VERSION ""

NS_ :

BS_:

BU_: Turbocharger OnBoardDataLogger OffBoardDiagnosticTool2 OffBoardDiagnosticTool1 FileServer ParkingBrakeController SeatControl2 FanDriveController SteeringColumnUnit CommunicationUnitRadio CommunicationUnitSatellite CommunicationUnitCellular PropulsionBatteryCharger ChassisController2 ChassisController1 EngineValveControl AuxiliaryHeater2 AuxiliaryHeater1 ClutchUnit RampControl InformationSystem1 SuspensionSystemController2 OilSensor VehicleDynamicStability ExhaustEmissionController TransmissionDisplay2 TransmissionDisplay1 ClimateControl2 WaterPumpController RearAxleSteeringController LightingOperatorControl SeatController1 IgnitionController2 IgnitionController1 TirePressureController CabController2 CabController1 PneumaticSystemController SuspensionSystemController1 HydraulicPumpController EnduranceBrakingSystem RetarderExhaustEngine2 OnBoardDiagnosticUnit HeadwayController RetarderExhaustEngine1 CabDisplay1 ManagementComputer VirtualTerminal OffVehicleGateway PowerTakeOffFront HitchControl AuxiliaryValveControl BodyController TractorTrailerBridge1 StarterSystem ElectricalSystem VehicleSecurity VehicleNavigation AerodynamicControl ElectricalChargingSystem ClimateControl1 TripRecorder InstrumentCluster SuspensionDriveAxle2 SuspensionDriveAxle1 SuspensionSteerAxle SteeringController FuelSystem CruiseControl RetarderDriveline RetarderEngine BrakesDriveAxle2 BrakesDriveAxle1 BrakesSystemController BrakesSteerAxle AxleDrive2 AxleDrive1 AxleSteering PowerTakeOff ShiftConsoleSecondary ShiftConsolePrimary Transmission2 Transmission1 Engine2 Engine1
VAL_TABLE_ FMI 31 "Not available" 19 "Received network data in error" 18 "Below normal (moderately severe)" 17 "Below normal (least severe)" 16 "Above normal (moderately severe)" 15 "Above normal (least severe)" 14 "Special intstructions" 13 "Out of calibration" 12 "Bad intelligent device" 11 "Root cause not known" 10 "Abnormal rate of change" 9 "Abnormal update rate" 8 "Abnormal frequency" 7 "Mechanical system not responding" 6 "Current above normal" 5 "Current below normal" 4 "Voltage below normal" 3 "Voltage above normal" 2 "Data erratic" 1 "Below normal (most severe)" 0 "Above normal (most severe)" ;

BO_ 3221225472 VECTOR__INDEPENDENT_SIG_MSG: 0 Vector__XXX
 SG_ TrailerWeight : 0|16@1+ (2,0) [0|128510] "kg" Vector__XXX
 SG_ ReferenceTirePressSetting : 0|8@1+ (1,0) [0|2000] "kPa" Vector__XXX
 SG_ ReferenceTirePress : 0|8@1+ (1,0) [0|2000] "kPa" Vector__XXX
 SG_ TirePressThresholdDetection : 0|3@1+ (1,0) [0|7] "" Vector__XXX
 SG_ TireAirLeakageRate : 0|16@1+ (0.1,0) [0|6425.5] "Pa/s" Vector__XXX
 SG_ CTIWheelEndElectricalFault : 0|2@1+ (1,0) [0|3] "" Vector__XXX
 SG_ CTITireStatus : 0|2@1+ (1,0) [0|3] "" Vector__XXX
 SG_ CTIWheelSensorStatus : 0|2@1+ (1,0) [0|3] "" Vector__XXX
 SG_ TireTemp : 0|16@1+ (0.03125,-273) [-273|1734.96875] "deg C" Vector__XXX
 SG_ TirePress : 0|8@1+ (4,0) [0|1000] "kPa" Vector__XXX
 SG_ EngTurningGearEngaged : 0|2@1+ (1,0) [0|3] "" Vector__XXX

BO_ 2632975290 TEST_ABSESC_DEVICE_BA: 8 Vector__XXX
 SG_ Can1RxIntrCnt : 32|32@1+ (1,0) [0|4294967295] "" Vector__XXX
 SG_ Can0RxIntrCnt : 0|32@1+ (1,0) [0|4294967295] "" Vector__XXX

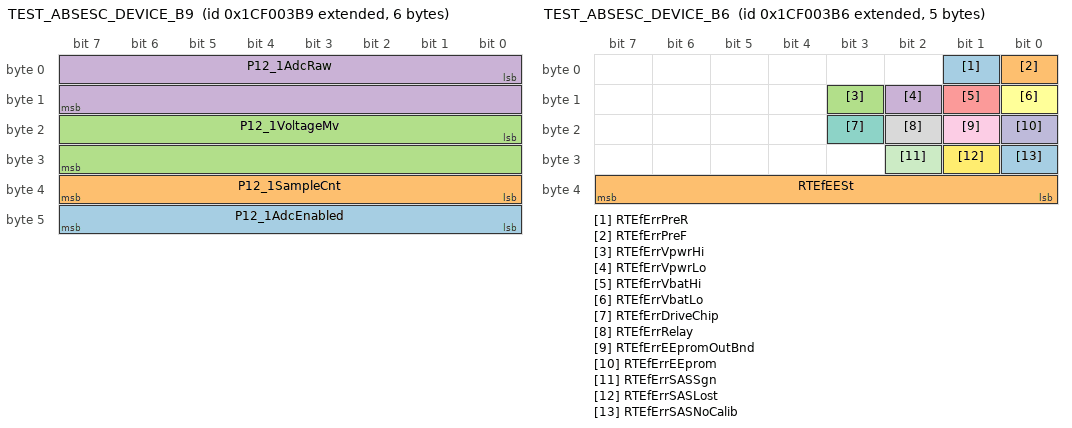
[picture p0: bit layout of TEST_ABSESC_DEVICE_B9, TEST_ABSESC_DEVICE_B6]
BO_ 2632975289 TEST_ABSESC_DEVICE_B9: 6 Vector__XXX
 SG_ P12_1AdcEnabled : 40|8@1+ (1,0) [0|1] "" Vector__XXX
 SG_ P12_1SampleCnt : 32|8@1+ (1,0) [0|255] "" Vector__XXX
 SG_ P12_1VoltageMv : 16|16@1+ (1,0) [0|5000] "mV" Vector__XXX
 SG_ P12_1AdcRaw : 0|16@1+ (1,0) [0|4095] "" Vector__XXX

BO_ 2632975286 TEST_ABSESC_DEVICE_B6: 5 Vector__XXX
 SG_ RTEfErrPreR : 1|1@1+ (1,0) [0|1] "" Vector__XXX
 SG_ RTEfErrPreF : 0|1@1+ (1,0) [0|1] "" Vector__XXX
 SG_ RTEfErrVpwrHi : 11|1@1+ (1,0) [0|1] "" Vector__XXX
 SG_ RTEfErrVpwrLo : 10|1@1+ (1,0) [0|1] "" Vector__XXX
 SG_ RTEfErrVbatHi : 9|1@1+ (1,0) [0|1] "" Vector__XXX
 SG_ RTEfErrVbatLo : 8|1@1+ (1,0) [0|1] "" Vector__XXX
 SG_ RTEfErrDriveChip : 19|1@1+ (1,0) [0|1] "" Vector__XXX
 SG_ RTEfErrRelay : 18|1@1+ (1,0) [0|1] "" Vector__XXX
 SG_ RTEfErrEEpromOutBnd : 17|1@1+ (1,0) [0|1] "" Vector__XXX
 SG_ RTEfErrEEprom : 16|1@1+ (1,0) [0|1] "" Vector__XXX
 SG_ RTEfErrSASSgn : 26|1@1+ (1,0) [0|1] "" Vector__XXX
 SG_ RTEfErrSASLost : 25|1@1+ (1,0) [0|1] "" Vector__XXX
 SG_ RTEfErrSASNoCalib : 24|1@1+ (1,0) [0|1] "" Vector__XXX
 SG_ RTEfEESt : 32|8@1+ (1,0) [0|255] "" Vector__XXX

BO_ 2632975285 TEST_ABSESC_DEVICE_B5: 8 Vector__XXX
 SG_ RTEfErrASRValveShortX : 57|1@1+ (1,0) [0|1] "" Vector__XXX
 SG_ RTEfErrASRValveOpenX : 56|1@1+ (1,0) [0|1] "" Vector__XXX
 SG_ RTEfErrASRValveShortR : 51|1@1+ (1,0) [0|1] "" Vector__XXX
 SG_ RTEfErrASRValveOpenR : 50|1@1+ (1,0) [0|1] "" Vector__XXX
 SG_ RTEfErrASRValveShortF : 49|1@1+ (1,0) [0|1] "" Vector__XXX
 SG_ RTEfErrASRValveOpenF : 48|1@1+ (1,0) [0|1] "" Vector__XXX
 SG_ RTEfErrOutValShortXR : 41|1@1+ (1,0) [0|1] "" Vector__XXX
 SG_ RTEfErrOutValOpenXR : 40|1@1+ (1,0) [0|1] "" Vector__XXX
 SG_ RTEfErrInValShortXR : 33|1@1+ (1,0) [0|1] "" Vector__XXX
 SG_ RTEfErrInValOpenXR : 32|1@1+ (1,0) [0|1] "" Vector__XXX
 SG_ RTEfErrOutValShortXL : 25|1@1+ (1,0) [0|1] "" Vector__XXX
 SG_ RTEfErrOutValOpenXL : 24|1@1+ (1,0) [0|1] "" Vector__XXX
 SG_ RTEfErrInValShortXL : 17|1@1+ (1,0) [0|1] "" Vector__XXX
 SG_ RTEfErrInValOpenXL : 16|1@1+ (1,0) [0|1] "" Vector__XXX
 SG_ RTEfErrOutValShortTr : 9|1@1+ (1,0) [0|1] "" Vector__XXX
 SG_ RTEfErrOutValOpenTr : 8|1@1+ (1,0) [0|1] "" Vector__XXX
 SG_ RTEfErrInValShortTr : 1|1@1+ (1,0) [0|1] "" Vector__XXX
 SG_ RTEfErrInValOpenTr : 0|1@1+ (1,0) [0|1] "" Vector__XXX

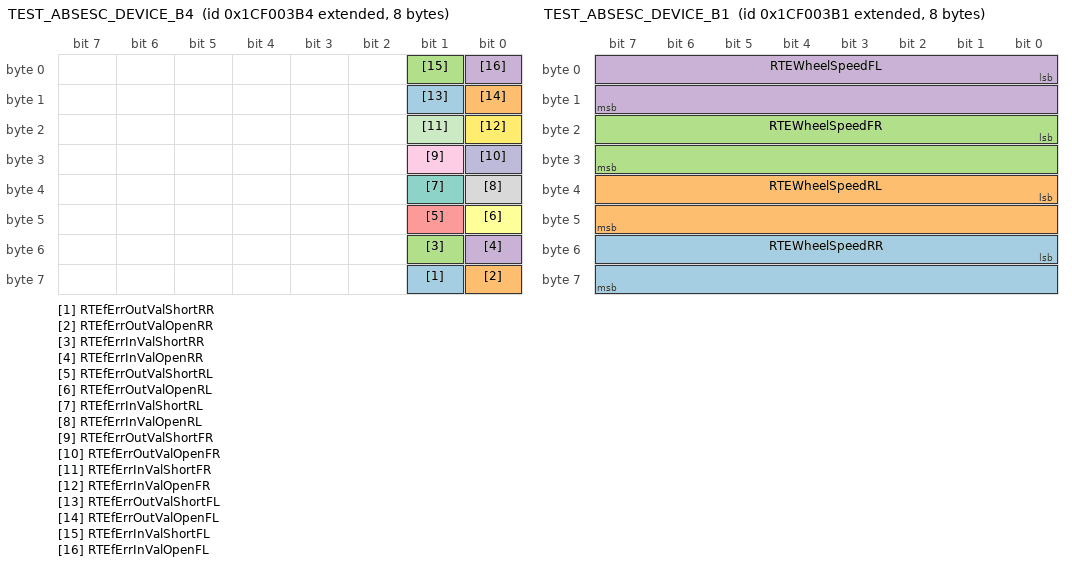
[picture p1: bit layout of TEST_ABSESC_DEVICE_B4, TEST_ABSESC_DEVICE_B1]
BO_ 2632975284 TEST_ABSESC_DEVICE_B4: 8 Vector__XXX
 SG_ RTEfErrOutValShortRR : 57|1@1+ (1,0) [0|1] "" Vector__XXX
 SG_ RTEfErrOutValOpenRR : 56|1@1+ (1,0) [0|1] "" Vector__XXX
 SG_ RTEfErrInValShortRR : 49|1@1+ (1,0) [0|1] "" Vector__XXX
 SG_ RTEfErrInValOpenRR : 48|1@1+ (1,0) [0|1] "" Vector__XXX
 SG_ RTEfErrOutValShortRL : 41|1@1+ (1,0) [0|1] "" Vector__XXX
 SG_ RTEfErrOutValOpenRL : 40|1@1+ (1,0) [0|1] "" Vector__XXX
 SG_ RTEfErrInValShortRL : 33|1@1+ (1,0) [0|1] "" Vector__XXX
 SG_ RTEfErrInValOpenRL : 32|1@1+ (1,0) [0|1] "" Vector__XXX
 SG_ RTEfErrOutValShortFR : 25|1@1+ (1,0) [0|1] "" Vector__XXX
 SG_ RTEfErrOutValOpenFR : 24|1@1+ (1,0) [0|1] "" Vector__XXX
 SG_ RTEfErrInValShortFR : 17|1@1+ (1,0) [0|1] "" Vector__XXX
 SG_ RTEfErrInValOpenFR : 16|1@1+ (1,0) [0|1] "" Vector__XXX
 SG_ RTEfErrOutValShortFL : 9|1@1+ (1,0) [0|1] "" Vector__XXX
 SG_ RTEfErrOutValOpenFL : 8|1@1+ (1,0) [0|1] "" Vector__XXX
 SG_ RTEfErrInValShortFL : 1|1@1+ (1,0) [0|1] "" Vector__XXX
 SG_ RTEfErrInValOpenFL : 0|1@1+ (1,0) [0|1] "" Vector__XXX

BO_ 2632975283 TEST_ABSESC_DEVICE_B3: 6 Vector__XXX
 SG_ RTEfErrWssGapXR : 42|1@1+ (1,0) [0|1] "" Vector__XXX
 SG_ RTEfErrWssShortXR : 41|1@1+ (1,0) [0|1] "" Vector__XXX
 SG_ RTEfErrWssOpenXR : 40|1@1+ (1,0) [0|1] "" Vector__XXX
 SG_ RTEfErrWssGapXL : 34|1@1+ (1,0) [0|1] "" Vector__XXX
 SG_ RTEfErrWssShortXL : 33|1@1+ (1,0) [0|1] "" Vector__XXX
 SG_ RTEfErrWssOpenXL : 32|1@1+ (1,0) [0|1] "" Vector__XXX
 SG_ RTEfErrWssGapRR : 26|1@1+ (1,0) [0|1] "" Vector__XXX
 SG_ RTEfErrWssShortRR : 25|1@1+ (1,0) [0|1] "" Vector__XXX
 SG_ RTEfErrWssOpenRR : 24|1@1+ (1,0) [0|1] "" Vector__XXX
 SG_ RTEfErrWssGapRL : 18|1@1+ (1,0) [0|1] "" Vector__XXX
 SG_ RTEfErrWssShortRL : 17|1@1+ (1,0) [0|1] "" Vector__XXX
 SG_ RTEfErrWssOpenRL : 16|1@1+ (1,0) [0|1] "" Vector__XXX
 SG_ RTEfErrWssGapFR : 10|1@1+ (1,0) [0|1] "" Vector__XXX
 SG_ RTEfErrWssShortFR : 9|1@1+ (1,0) [0|1] "" Vector__XXX
 SG_ RTEfErrWssOpenFR : 8|1@1+ (1,0) [0|1] "" Vector__XXX
 SG_ RTEfErrWssGapFL : 2|1@1+ (1,0) [0|1] "" Vector__XXX
 SG_ RTEfErrWssShortFL : 1|1@1+ (1,0) [0|1] "" Vector__XXX
 SG_ RTEfErrWssOpenFL : 0|1@1+ (1,0) [0|1] "" Vector__XXX

BO_ 2632975282 TEST_ABSESC_DEVICE_B2: 4 Vector__XXX
 SG_ RTEWheelSpeedXR : 16|16@1+ (1,0) [0|65535] "mm/s" Vector__XXX
 SG_ RTEWheelSpeedXL : 0|16@1+ (1,0) [0|65535] "mm/s" Vector__XXX

BO_ 2632975281 TEST_ABSESC_DEVICE_B1: 8 Vector__XXX
 SG_ RTEWheelSpeedRR : 48|16@1+ (1,0) [0|65535] "mm/s" Vector__XXX
 SG_ RTEWheelSpeedRL : 32|16@1+ (1,0) [0|65535] "mm/s" Vector__XXX
 SG_ RTEWheelSpeedFR : 16|16@1+ (1,0) [0|65535] "mm/s" Vector__XXX
 SG_ RTEWheelSpeedFL : 0|16@1+ (1,0) [0|65535] "mm/s" Vector__XXX

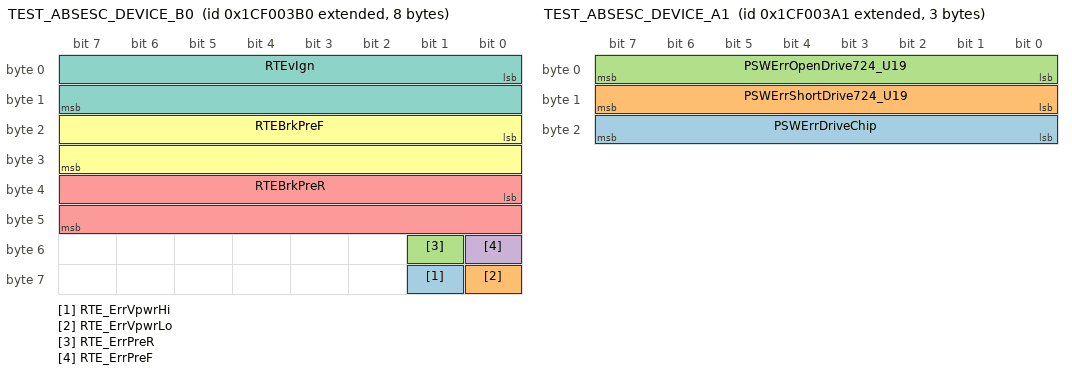
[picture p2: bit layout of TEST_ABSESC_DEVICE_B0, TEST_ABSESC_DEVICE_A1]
BO_ 2632975280 TEST_ABSESC_DEVICE_B0: 8 Vector__XXX
 SG_ RTE_ErrVpwrHi : 57|1@1+ (1,0) [0|1] "" Vector__XXX
 SG_ RTE_ErrVpwrLo : 56|1@1+ (1,0) [0|1] "" Vector__XXX
 SG_ RTE_ErrPreR : 49|1@1+ (1,0) [0|1] "" Vector__XXX
 SG_ RTE_ErrPreF : 48|1@1+ (1,0) [0|1] "" Vector__XXX
 SG_ RTEBrkPreR : 32|16@1+ (1,0) [0|65535] "kPa" Vector__XXX
 SG_ RTEBrkPreF : 16|16@1+ (1,0) [0|65535] "kPa" Vector__XXX
 SG_ RTEvIgn : 0|16@1+ (1,0) [0|65535] "0.1V" Vector__XXX

BO_ 2632975265 TEST_ABSESC_DEVICE_A1: 3 Vector__XXX
 SG_ PSWErrDriveChip : 16|8@1+ (1,0) [0|10] "" Vector__XXX
 SG_ PSWErrShortDrive724_U19 : 8|8@1+ (1,0) [0|3] "" Vector__XXX
 SG_ PSWErrOpenDrive724_U19 : 0|8@1+ (1,0) [0|3] "" Vector__XXX

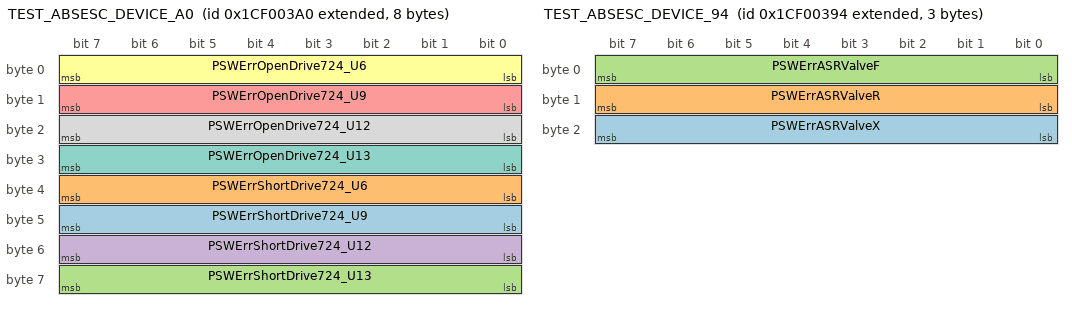
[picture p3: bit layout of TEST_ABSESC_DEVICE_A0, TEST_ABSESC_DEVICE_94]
BO_ 2632975264 TEST_ABSESC_DEVICE_A0: 8 Vector__XXX
 SG_ PSWErrShortDrive724_U9 : 40|8@1+ (1,0) [0|3] "" Vector__XXX
 SG_ PSWErrShortDrive724_U6 : 32|8@1+ (1,0) [0|3] "" Vector__XXX
 SG_ PSWErrShortDrive724_U13 : 56|8@1+ (1,0) [0|3] "" Vector__XXX
 SG_ PSWErrShortDrive724_U12 : 48|8@1+ (1,0) [0|3] "" Vector__XXX
 SG_ PSWErrOpenDrive724_U9 : 8|8@1+ (1,0) [0|3] "" Vector__XXX
 SG_ PSWErrOpenDrive724_U6 : 0|8@1+ (1,0) [0|3] "" Vector__XXX
 SG_ PSWErrOpenDrive724_U13 : 24|8@1+ (1,0) [0|3] "" Vector__XXX
 SG_ PSWErrOpenDrive724_U12 : 16|8@1+ (1,0) [0|3] "" Vector__XXX

BO_ 2632975252 TEST_ABSESC_DEVICE_94: 3 Vector__XXX
 SG_ PSWErrASRValveX : 16|8@1+ (1,0) [0|3] "" Vector__XXX
 SG_ PSWErrASRValveR : 8|8@1+ (1,0) [0|3] "" Vector__XXX
 SG_ PSWErrASRValveF : 0|8@1+ (1,0) [0|0] "" Vector__XXX

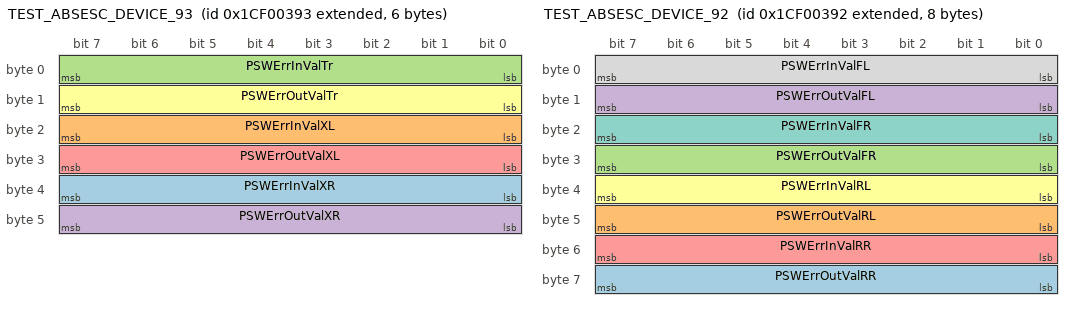
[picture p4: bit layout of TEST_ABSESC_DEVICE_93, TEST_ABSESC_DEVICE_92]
BO_ 2632975251 TEST_ABSESC_DEVICE_93: 6 Vector__XXX
 SG_ PSWErrInValXR : 32|8@1+ (1,0) [0|3] "" Vector__XXX
 SG_ PSWErrInValXL : 16|8@1+ (1,0) [0|3] "" Vector__XXX
 SG_ PSWErrInValTr : 0|8@1+ (1,0) [0|3] "" Vector__XXX
 SG_ PSWErrOutValXR : 40|8@1+ (1,0) [0|3] "" Vector__XXX
 SG_ PSWErrOutValXL : 24|8@1+ (1,0) [0|3] "" Vector__XXX
 SG_ PSWErrOutValTr : 8|8@1+ (1,0) [0|3] "" Vector__XXX

BO_ 2632975250 TEST_ABSESC_DEVICE_92: 8 Vector__XXX
 SG_ PSWErrOutValRR : 56|8@1+ (1,0) [0|3] "" Vector__XXX
 SG_ PSWErrOutValRL : 40|8@1+ (1,0) [0|3] "" Vector__XXX
 SG_ PSWErrOutValFR : 24|8@1+ (1,0) [0|3] "" Vector__XXX
 SG_ PSWErrOutValFL : 8|8@1+ (1,0) [0|3] "" Vector__XXX
 SG_ PSWErrInValRR : 48|8@1+ (1,0) [0|3] "" Vector__XXX
 SG_ PSWErrInValRL : 32|8@1+ (1,0) [0|3] "" Vector__XXX
 SG_ PSWErrInValFR : 16|8@1+ (1,0) [0|3] "" Vector__XXX
 SG_ PSWErrInValFL : 0|8@1+ (1,0) [0|3] "" Vector__XXX

BO_ 2632975249 TEST_ABSESC_DEVICE_91: 0 Vector__XXX

BO_ 2632975248 TEST_ABSESC_DEVICE_90: 2 Vector__XXX
 SG_ ASRRLowSideSt : 8|8@1+ (1,0) [0|1] "" Vector__XXX
 SG_ ASRFLowSideSt : 0|8@1+ (1,0) [0|1] "" Vector__XXX

BO_ 2632975233 TEST_ABSESC_DEVICE_81: 4 Vector__XXX
 SG_ PSWWheelSpeedXR : 16|16@1+ (1,0) [0|65535] "mm/s" Vector__XXX
 SG_ PSWWheelSpeedXL : 0|16@1+ (1,0) [0|65535] "mm/s" Vector__XXX

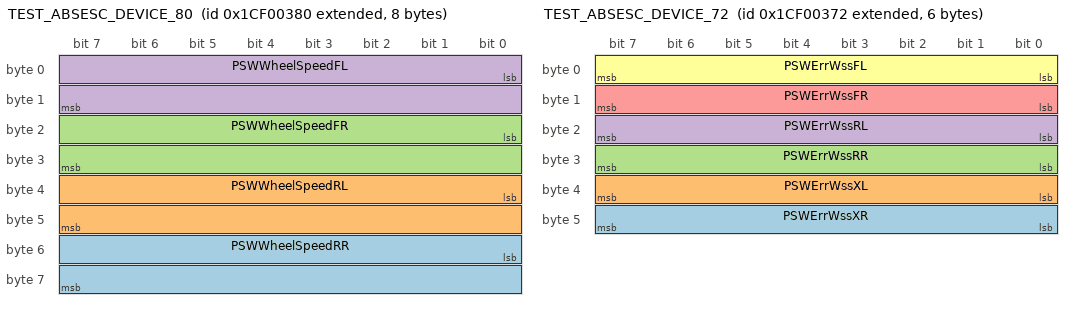
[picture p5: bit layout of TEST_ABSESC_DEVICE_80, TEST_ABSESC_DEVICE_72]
BO_ 2632975232 TEST_ABSESC_DEVICE_80: 8 Vector__XXX
 SG_ PSWWheelSpeedRR : 48|16@1+ (1,0) [0|65535] "mm/s" Vector__XXX
 SG_ PSWWheelSpeedRL : 32|16@1+ (1,0) [0|65535] "mm/s" Vector__XXX
 SG_ PSWWheelSpeedFR : 16|16@1+ (1,0) [0|65535] "mm/s" Vector__XXX
 SG_ PSWWheelSpeedFL : 0|16@1+ (1,0) [0|65535] "mm/s" Vector__XXX

BO_ 2632975218 TEST_ABSESC_DEVICE_72: 6 Vector__XXX
 SG_ PSWErrWssXR : 40|8@1+ (1,0) [0|3] "" Vector__XXX
 SG_ PSWErrWssXL : 32|8@1+ (1,0) [0|3] "" Vector__XXX
 SG_ PSWErrWssRR : 24|8@1+ (1,0) [0|3] "" Vector__XXX
 SG_ PSWErrWssRL : 16|8@1+ (1,0) [0|3] "" Vector__XXX
 SG_ PSWErrWssFR : 8|8@1+ (1,0) [0|3] "" Vector__XXX
 SG_ PSWErrWssFL : 0|8@1+ (1,0) [0|3] "" Vector__XXX

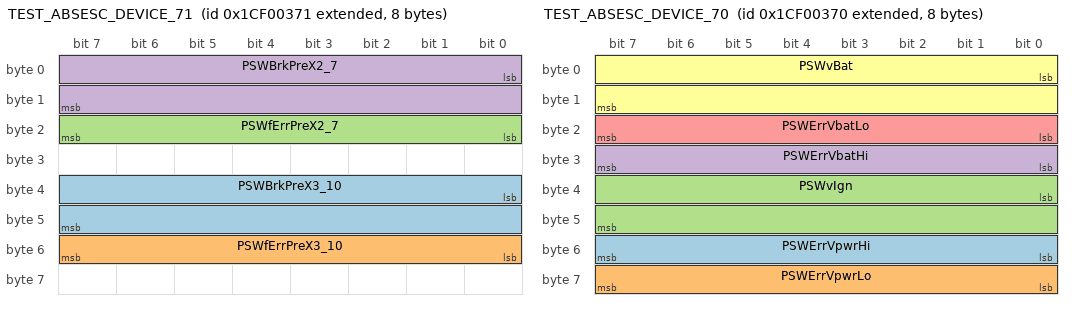
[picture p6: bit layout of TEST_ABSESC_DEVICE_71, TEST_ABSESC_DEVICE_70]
BO_ 2632975217 TEST_ABSESC_DEVICE_71: 8 Vector__XXX
 SG_ PSWBrkPreX3_10 : 32|16@1+ (1,0) [0|0] "" Vector__XXX
 SG_ PSWfErrPreX3_10 : 48|8@1+ (1,0) [0|0] "" Vector__XXX
 SG_ PSWfErrPreX2_7 : 16|8@1+ (1,0) [0|0] "" Vector__XXX
 SG_ PSWBrkPreX2_7 : 0|16@1+ (1,0) [0|0] "" Vector__XXX

BO_ 2632975216 TEST_ABSESC_DEVICE_70: 8 Vector__XXX
 SG_ PSWErrVpwrHi : 48|8@1+ (1,0) [0|0] "" Vector__XXX
 SG_ PSWErrVpwrLo : 56|8@1+ (1,0) [0|0] "" Vector__XXX
 SG_ PSWvIgn : 32|16@1+ (1,0) [0|0] "" Vector__XXX
 SG_ PSWErrVbatHi : 24|8@1+ (1,0) [0|0] "" Vector__XXX
 SG_ PSWErrVbatLo : 16|8@1+ (1,0) [0|0] "" Vector__XXX
 SG_ PSWvBat : 0|16@1+ (1,0) [0|0] "" Vector__XXX

BO_ 2632975205 TEST_ABSESC_DEVICE_65: 2 Vector__XXX
 SG_ PSWfErrEEpromOutBnd : 8|8@1+ (1,0) [0|0] "" Vector__XXX
 SG_ PSWfErrEEprom : 0|8@1+ (1,0) [0|0] "" Vector__XXX

BO_ 2632975204 TEST_ABSESC_DEVICE_64: 2 Vector__XXX
 SG_ flFlag : 0|16@1+ (1,0) [0|0] "" Vector__XXX

BO_ 2632975203 TEST_ABSESC_DEVICE_63: 2 Vector__XXX
 SG_ flFlag : 0|16@1+ (1,0) [0|0] "" Vector__XXX

BO_ 2632975202 TEST_ABSESC_DEVICE_62: 1 Vector__XXX
 SG_ PSWfErrEEprom : 0|8@1+ (1,0) [0|0] "" Vector__XXX

BO_ 2632975201 TEST_ABSESC_DEVICE_61: 1 Vector__XXX
 SG_ eeFlag : 0|8@1+ (1,0) [0|0] "" Vector__XXX

BO_ 2632975200 TEST_ABSESC_DEVICE_60: 2 Vector__XXX
 SG_ phase : 0|8@1+ (1,0) [0|4] "" Vector__XXX
 SG_ PSWfErrEEprom : 8|8@1+ (1,0) [0|1] "" Vector__XXX

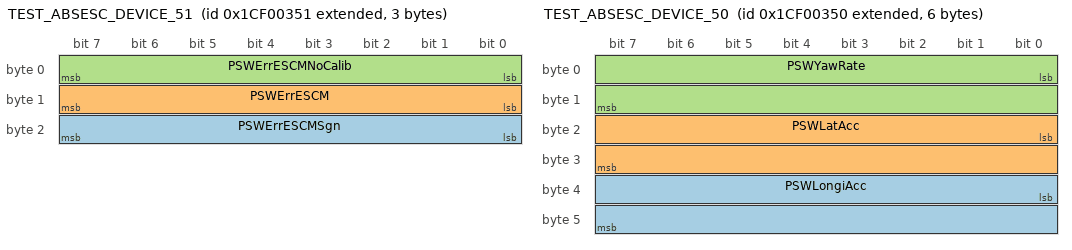
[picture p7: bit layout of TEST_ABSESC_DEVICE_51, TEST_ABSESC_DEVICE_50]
BO_ 2632975185 TEST_ABSESC_DEVICE_51: 3 Vector__XXX
 SG_ PSWErrESCMSgn : 16|8@1+ (1,0) [0|0] "" Vector__XXX
 SG_ PSWErrESCM : 8|8@1+ (1,0) [0|0] "" Vector__XXX
 SG_ PSWErrESCMNoCalib : 0|8@1+ (1,0) [0|0] "" Vector__XXX

BO_ 2632975184 TEST_ABSESC_DEVICE_50: 6 Vector__XXX
 SG_ PSWLongiAcc : 32|16@1+ (0.01,-21) [0|0] "m/s2" Vector__XXX
 SG_ PSWLatAcc : 16|16@1+ (0.01,-21) [0|0] "m/s2" Vector__XXX
 SG_ PSWYawRate : 0|16@1+ (0.01,-300) [0|0] "rad/s" Vector__XXX

BO_ 2632975170 TEST_ABSESC_DEVICE_42: 1 Vector__XXX
 SG_ PSWErrRelay : 0|8@1+ (1,0) [0|1] "" Vector__XXX

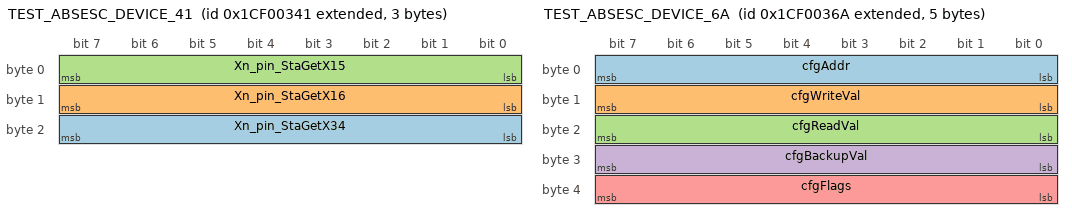
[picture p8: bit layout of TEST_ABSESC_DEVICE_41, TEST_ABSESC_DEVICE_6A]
BO_ 2632975169 TEST_ABSESC_DEVICE_41: 3 Vector__XXX
 SG_ Xn_pin_StaGetX34 : 16|8@1+ (1,0) [0|0] "" Vector__XXX
 SG_ Xn_pin_StaGetX16 : 8|8@1+ (1,0) [0|0] "" Vector__XXX
 SG_ Xn_pin_StaGetX15 : 0|8@1+ (1,0) [0|0] "" Vector__XXX

BO_ 2632975168 TEST_ABSESC_DEVICE_40: 3 Vector__XXX
 SG_ gpoFlag_phase : 0|8@1+ (1,0) [0|0] "0" Vector__XXX
 SG_ gpoFlag : 8|16@1+ (1,0) [0|0] "0" Vector__XXX

BO_ 2632975152 TEST_ABSESC_DEVICE_30: 4 Vector__XXX
 SG_ timercnt10ms : 0|32@1+ (1,0) [0|0] "" Vector__XXX

BO_ 2632975137 TEST_ABSESC_DEVICE_21: 2 Vector__XXX
 SG_ WD_cnt : 0|16@1+ (1,0) [0|65535] "" Vector__XXX

BO_ 2632975136 TEST_ABSESC_DEVICE_20: 2 Vector__XXX
 SG_ WD_cnt : 0|16@1+ (1,0) [0|65535] "" Vector__XXX

BO_ 2632975121 TEST_ABSESC_DEVICE_11: 4 Vector__XXX
 SG_ resetReason : 0|32@1+ (1,0) [0|0] "" Vector__XXX

BO_ 2632975120 TEST_ABSESC_DEVICE_10: 1 Vector__XXX
 SG_ rstFlag : 0|8@1+ (1,0) [0|0] "8" Vector__XXX

BO_ 2632975106 TEST_ABSESC_DEVICE_02: 4 Vector__XXX
 SG_ extCnt : 0|16@1+ (1,0) [0|65535] "" Vector__XXX
 SG_ stdCnt : 16|16@1+ (1,0) [0|65535] "" Vector__XXX

BO_ 2632975107 TEST_ABSESC_DEVICE_03: 2 Vector__XXX
 SG_ busoffState0 : 0|8@1+ (1,0) [0|1] "" Vector__XXX
 SG_ busoffState1 : 8|8@1+ (1,0) [0|1] "" Vector__XXX

BO_ 2632975210 TEST_ABSESC_DEVICE_6A: 5 Vector__XXX
 SG_ cfgAddr : 0|8@1+ (1,0) [0|31] "" Vector__XXX
 SG_ cfgWriteVal : 8|8@1+ (1,0) [0|255] "" Vector__XXX
 SG_ cfgReadVal : 16|8@1+ (1,0) [0|255] "" Vector__XXX
 SG_ cfgBackupVal : 24|8@1+ (1,0) [0|255] "" Vector__XXX
 SG_ cfgFlags : 32|8@1+ (1,0) [0|7] "" Vector__XXX

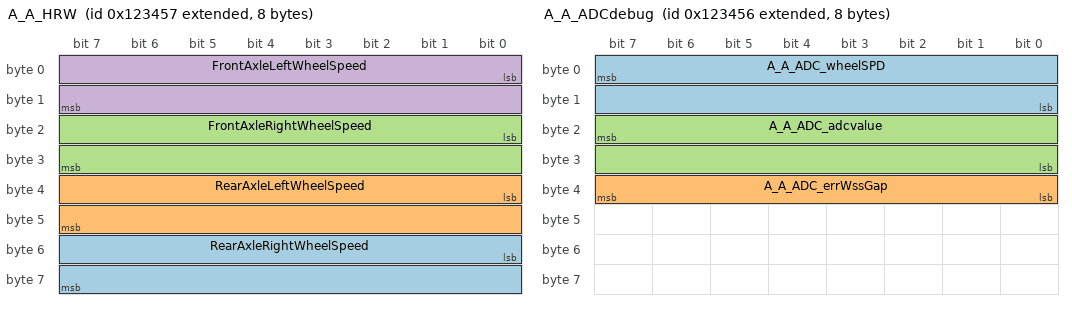
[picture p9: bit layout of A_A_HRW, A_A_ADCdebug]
BO_ 2148676695 A_A_HRW: 8 Vector__XXX
 SG_ RearAxleRightWheelSpeed : 48|16@1+ (0.0036,0) [0|200] "km/h" Vector__XXX
 SG_ RearAxleLeftWheelSpeed : 32|16@1+ (0.0036,0) [0|200] "km/h" Vector__XXX
 SG_ FrontAxleRightWheelSpeed : 16|16@1+ (0.0036,0) [0|200] "km/h" Vector__XXX
 SG_ FrontAxleLeftWheelSpeed : 0|16@1+ (0.0036,0) [0|200] "km/h" Vector__XXX

BO_ 2148676694 A_A_ADCdebug: 8 Vector__XXX
 SG_ A_A_ADC_wheelSPD : 7|16@0+ (0.0036,0) [0|150] "km/h" Vector__XXX
 SG_ A_A_ADC_errWssGap : 32|8@1+ (1,0) [0|5] "" Vector__XXX
 SG_ A_A_ADC_adcvalue : 23|16@0+ (1,0) [0|5000] "" Vector__XXX

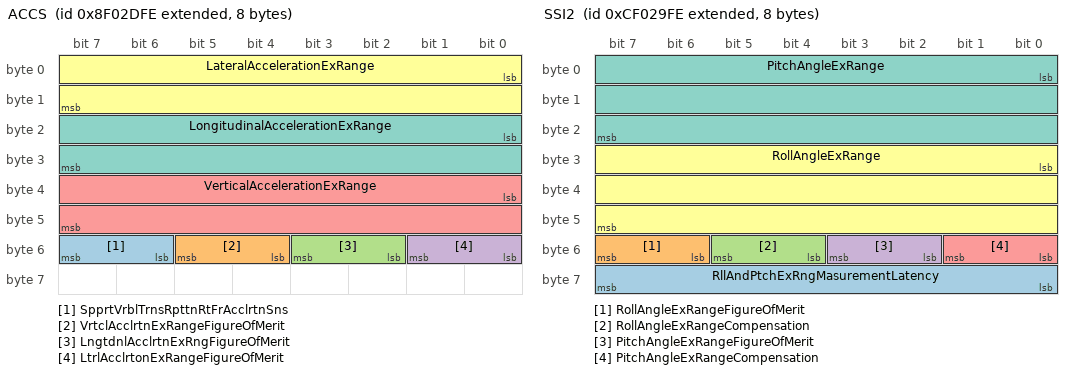
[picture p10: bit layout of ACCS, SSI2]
BO_ 2297441790 ACCS: 8 Vector__XXX
 SG_ SpprtVrblTrnsRpttnRtFrAcclrtnSns : 54|2@1+ (1,0) [0|3] "" Vector__XXX
 SG_ VrtclAcclrtnExRangeFigureOfMerit : 52|2@1+ (1,0) [0|3] "" Vector__XXX
 SG_ LngtdnlAcclrtnExRngFigureOfMerit : 50|2@1+ (1,0) [0|3] "" Vector__XXX
 SG_ LtrlAcclrtonExRangeFigureOfMerit : 48|2@1+ (1,0) [0|3] "" Vector__XXX
 SG_ VerticalAccelerationExRange : 32|16@1+ (0.01,-320) [-320|322.55] "m/s�" Vector__XXX
 SG_ LateralAccelerationExRange : 0|16@1+ (0.01,-320) [-320|322.55] "m/s�" Vector__XXX
 SG_ LongitudinalAccelerationExRange : 16|16@1+ (0.01,-320) [-320|322.55] "m/s�" Vector__XXX

BO_ 2566712062 VEP4: 8 Vector__XXX
 SG_ HybridBatteryPackRemainingCharge : 0|16@1+ (0.0025,0) [0|160.6375] "%" Vector__XXX

BO_ 2364549630 SSI2: 8 Vector__XXX
 SG_ RllAndPtchExRngMasurementLatency : 56|8@1+ (0.5,0) [0|125] "ms" Vector__XXX
 SG_ RollAngleExRangeFigureOfMerit : 54|2@1+ (1,0) [0|3] "" Vector__XXX
 SG_ RollAngleExRangeCompensation : 52|2@1+ (1,0) [0|3] "" Vector__XXX
 SG_ PitchAngleExRangeFigureOfMerit : 50|2@1+ (1,0) [0|3] "" Vector__XXX
 SG_ PitchAngleExRangeCompensation : 48|2@1+ (1,0) [0|3] "" Vector__XXX
 SG_ RollAngleExRange : 24|24@1+ (1,-250) [-250|250.9999] "deg" Vector__XXX
 SG_ PitchAngleExRange : 0|24@1+ (1,-250) [-250|250.9999] "deg" Vector__XXX

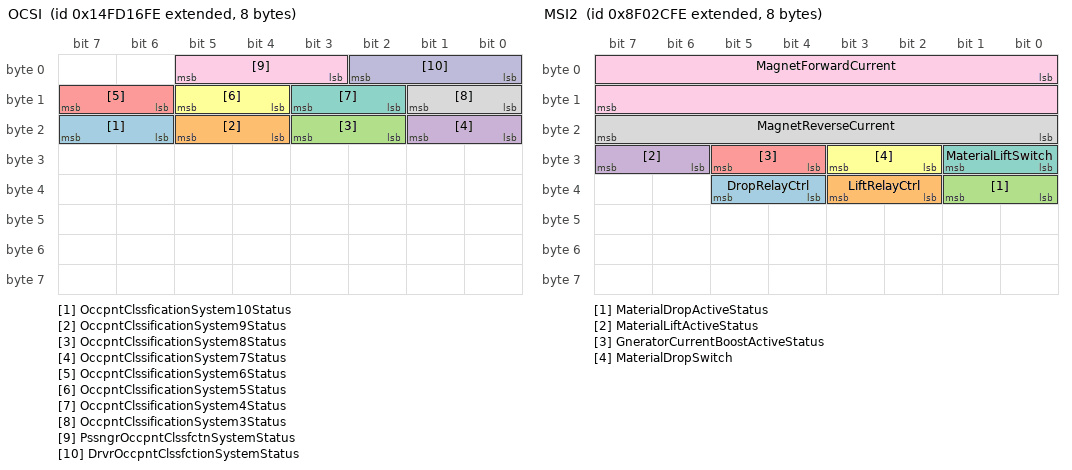
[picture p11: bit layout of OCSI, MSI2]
BO_ 2499614462 OCSI: 8 Vector__XXX
 SG_ OccpntClssficationSystem10Status : 22|2@1+ (1,0) [0|3] "" Vector__XXX
 SG_ OccpntClssificationSystem9Status : 20|2@1+ (1,0) [0|3] "" Vector__XXX
 SG_ OccpntClssificationSystem8Status : 18|2@1+ (1,0) [0|3] "" Vector__XXX
 SG_ OccpntClssificationSystem7Status : 16|2@1+ (1,0) [0|3] "" Vector__XXX
 SG_ OccpntClssificationSystem6Status : 14|2@1+ (1,0) [0|3] "" Vector__XXX
 SG_ OccpntClssificationSystem5Status : 12|2@1+ (1,0) [0|3] "" Vector__XXX
 SG_ OccpntClssificationSystem4Status : 10|2@1+ (1,0) [0|3] "" Vector__XXX
 SG_ OccpntClssificationSystem3Status : 8|2@1+ (1,0) [0|3] "" Vector__XXX
 SG_ PssngrOccpntClssfctnSystemStatus : 3|3@1+ (1,0) [0|7] "" Vector__XXX
 SG_ DrvrOccpntClssfctionSystemStatus : 0|3@1+ (1,0) [0|7] "" Vector__XXX

BO_ 2560098046 NCS: 8 Vector__XXX
 SG_ CabNoiseCtrlTuningStatus : 2|4@1+ (1,0) [0|15] "" Vector__XXX
 SG_ CabNoiseCtrlStatus : 0|2@1+ (1,0) [0|3] "" Vector__XXX

BO_ 2560163582 NC1: 8 Vector__XXX
 SG_ CabNoiseCtrlTuningState : 2|3@1+ (1,0) [0|7] "" Vector__XXX
 SG_ CabNoiseCtrlState : 0|2@1+ (1,0) [0|3] "" Vector__XXX

BO_ 2297441534 MSI2: 8 Vector__XXX
 SG_ DropRelayCtrl : 36|2@1+ (1,0) [0|3] "" Vector__XXX
 SG_ LiftRelayCtrl : 34|2@1+ (1,0) [0|3] "" Vector__XXX
 SG_ MaterialDropActiveStatus : 32|2@1+ (1,0) [0|3] "" Vector__XXX
 SG_ MaterialLiftActiveStatus : 30|2@1+ (1,0) [0|3] "" Vector__XXX
 SG_ GneratorCurrentBoostActiveStatus : 28|2@1+ (1,0) [0|3] "" Vector__XXX
 SG_ MaterialDropSwitch : 26|2@1+ (1,0) [0|3] "" Vector__XXX
 SG_ MaterialLiftSwitch : 24|2@1+ (1,0) [0|3] "" Vector__XXX
 SG_ MagnetReverseCurrent : 16|8@1+ (1,0) [0|250] "A" Vector__XXX
 SG_ MagnetForwardCurrent : 0|16@1+ (1,0) [0|64255] "Amps" Vector__XXX

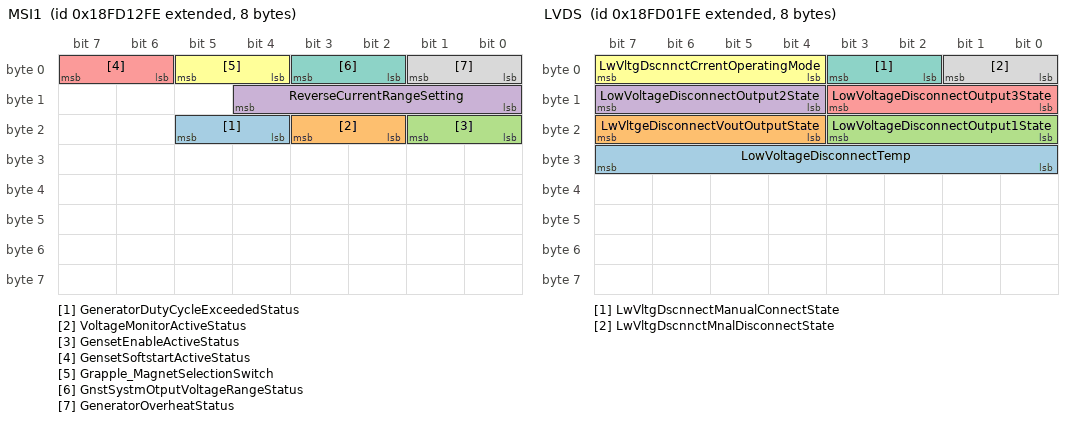
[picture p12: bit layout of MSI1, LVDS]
BO_ 2566722302 MSI1: 8 Vector__XXX
 SG_ GeneratorDutyCycleExceededStatus : 20|2@1+ (1,0) [0|3] "" Vector__XXX
 SG_ VoltageMonitorActiveStatus : 18|2@1+ (1,0) [0|3] "" Vector__XXX
 SG_ GensetEnableActiveStatus : 16|2@1+ (1,0) [0|3] "" Vector__XXX
 SG_ ReverseCurrentRangeSetting : 8|5@1+ (1,0) [0|31] "" Vector__XXX
 SG_ GensetSoftstartActiveStatus : 6|2@1+ (1,0) [0|3] "" Vector__XXX
 SG_ Grapple_MagnetSelectionSwitch : 4|2@1+ (1,0) [0|3] "" Vector__XXX
 SG_ GnstSystmOtputVoltageRangeStatus : 2|2@1+ (1,0) [0|3] "" Vector__XXX
 SG_ GeneratorOverheatStatus : 0|2@1+ (1,0) [0|3] "" Vector__XXX

BO_ 2566722558 MSCI: 8 Vector__XXX
 SG_ MagnetRatedPower : 8|16@1+ (1,0) [0|32127.5] "kW" Vector__XXX
 SG_ MagnetBoostTime : 0|8@1+ (1,0) [0|62.5] "s" Vector__XXX

BO_ 2560032510 LVDSOM: 8 Vector__XXX
 SG_ LwVltgDscnnctDsiredOperatingMode : 0|4@1+ (1,0) [0|15] "" Vector__XXX

BO_ 2566717950 LVDS: 8 Vector__XXX
 SG_ LowVoltageDisconnectTemp : 24|8@1+ (1,-40) [-40|210] "deg C" Vector__XXX
 SG_ LwVltgeDisconnectVoutOutputState : 20|4@1+ (1,0) [0|15] "" Vector__XXX
 SG_ LowVoltageDisconnectOutput1State : 16|4@1+ (1,0) [0|15] "" Vector__XXX
 SG_ LowVoltageDisconnectOutput2State : 12|4@1+ (1,0) [0|15] "" Vector__XXX
 SG_ LowVoltageDisconnectOutput3State : 8|4@1+ (1,0) [0|15] "" Vector__XXX
 SG_ LwVltgDscnnctCrrentOperatingMode : 4|4@1+ (1,0) [0|15] "" Vector__XXX
 SG_ LwVltgDscnnectManualConnectState : 2|2@1+ (1,0) [0|3] "" Vector__XXX
 SG_ LwVltgDscnnctMnalDisconnectState : 0|2@1+ (1,0) [0|3] "" Vector__XXX

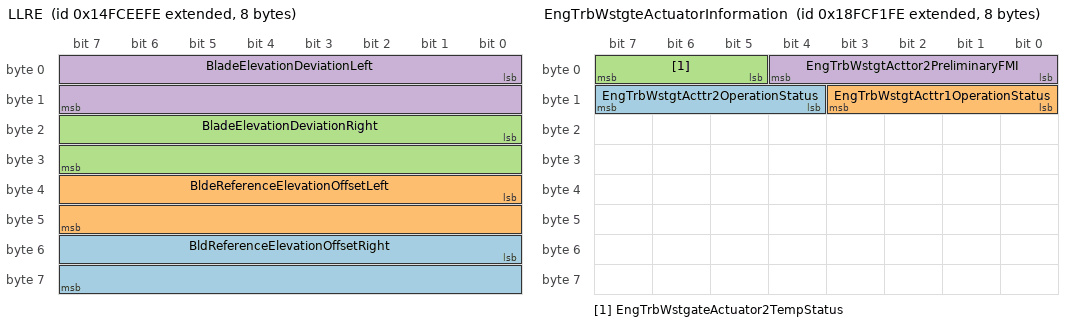
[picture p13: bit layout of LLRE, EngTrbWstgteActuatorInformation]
BO_ 2499604222 LLRE: 8 Vector__XXX
 SG_ BldReferenceElevationOffsetRight : 48|16@1+ (1,-32000) [-32000|32255] "mm" Vector__XXX
 SG_ BldeReferenceElevationOffsetLeft : 32|16@1+ (1,-32000) [-32000|32255] "mm" Vector__XXX
 SG_ BladeElevationDeviationRight : 16|16@1+ (1,-32000) [-32000|32255] "mm" Vector__XXX
 SG_ BladeElevationDeviationLeft : 0|16@1+ (1,-32000) [-32000|32255] "mm" Vector__XXX

BO_ 2358902526 JLCM: 8 Vector__XXX
 SG_ Joystick3Lamp10Cmd : 58|2@1+ (1,0) [0|3] "" Vector__XXX
 SG_ Joystick3Lamp9Cmd : 56|2@1+ (1,0) [0|3] "" Vector__XXX
 SG_ Joystick3Lamp8Cmd : 54|2@1+ (1,0) [0|3] "" Vector__XXX
 SG_ Joystick3Lamp7Cmd : 52|2@1+ (1,0) [0|3] "" Vector__XXX
 SG_ Joystick3Lamp6Cmd : 50|2@1+ (1,0) [0|3] "" Vector__XXX
 SG_ Joystick3Lamp5Cmd : 48|2@1+ (1,0) [0|3] "" Vector__XXX
 SG_ Joystick3Lamp4Cmd : 46|2@1+ (1,0) [0|3] "" Vector__XXX
 SG_ Joystick3Lamp3Cmd : 44|2@1+ (1,0) [0|3] "" Vector__XXX
 SG_ Joystick3Lamp2Cmd : 42|2@1+ (1,0) [0|3] "" Vector__XXX
 SG_ Joystick3Lamp1Cmd : 40|2@1+ (1,0) [0|3] "" Vector__XXX
 SG_ Joystick2Lamp10Cmd : 38|2@1+ (1,0) [0|3] "" Vector__XXX
 SG_ Joystick2Lamp9Cmd : 36|2@1+ (1,0) [0|3] "" Vector__XXX
 SG_ Joystick2Lamp8Cmd : 34|2@1+ (1,0) [0|3] "" Vector__XXX
 SG_ Joystick2Lamp7Cmd : 32|2@1+ (1,0) [0|3] "" Vector__XXX
 SG_ Joystick2Lamp6Cmd : 30|2@1+ (1,0) [0|3] "" Vector__XXX
 SG_ Joystick2Lamp5Cmd : 28|2@1+ (1,0) [0|3] "" Vector__XXX
 SG_ Joystick2Lamp4Cmd : 26|2@1+ (1,0) [0|3] "" Vector__XXX
 SG_ Joystick2Lamp3Cmd : 24|2@1+ (1,0) [0|3] "" Vector__XXX
 SG_ Joystick2Lamp2Cmd : 22|2@1+ (1,0) [0|3] "" Vector__XXX
 SG_ Joystick2Lamp1Cmd : 20|2@1+ (1,0) [0|3] "" Vector__XXX
 SG_ Joystick1Lamp10Cmd : 18|2@1+ (1,0) [0|3] "" Vector__XXX
 SG_ Joystick1Lamp9Cmd : 16|2@1+ (1,0) [0|3] "" Vector__XXX
 SG_ Joystick1Lamp8Cmd : 14|2@1+ (1,0) [0|3] "" Vector__XXX
 SG_ Joystick1Lamp7Cmd : 12|2@1+ (1,0) [0|3] "" Vector__XXX
 SG_ Joystick1Lamp6Cmd : 10|2@1+ (1,0) [0|3] "" Vector__XXX
 SG_ Joystick1Lamp5Cmd : 8|2@1+ (1,0) [0|3] "" Vector__XXX
 SG_ Joystick1Lamp4Cmd : 6|2@1+ (1,0) [0|3] "" Vector__XXX
 SG_ Joystick1Lamp3Cmd : 4|2@1+ (1,0) [0|3] "" Vector__XXX
 SG_ Joystick1Lamp2Cmd : 2|2@1+ (1,0) [0|3] "" Vector__XXX
 SG_ Joystick1Lamp1Cmd : 0|2@1+ (1,0) [0|3] "" Vector__XXX

BO_ 2566711550 IVAC: 8 Vector__XXX
 SG_ IntkVlvActtnSystmOlPrss2SlndCtrl : 2|2@1+ (1,0) [0|3] "" Vector__XXX
 SG_ IntkVlvActtnSystmOlPrss1SlndCtrl : 0|2@1+ (1,0) [0|3] "" Vector__XXX

BO_ 2633832958 ILI: 8 Vector__XXX
 SG_ SpecialIgnitorLoop90Resistance : 1584|16@1+ (0.1,0) [0|6425.5] "ohm" Vector__XXX
 SG_ SpecialIgnitorLoop89Resistance : 1568|16@1+ (0.1,0) [0|6425.5] "ohm" Vector__XXX
 SG_ SpecialIgnitorLoop88Resistance : 1552|16@1+ (0.1,0) [0|6425.5] "ohm" Vector__XXX
 SG_ SpecialIgnitorLoop87Resistance : 1536|16@1+ (0.1,0) [0|6425.5] "ohm" Vector__XXX
 SG_ SpecialIgnitorLoop86Resistance : 1520|16@1+ (0.1,0) [0|6425.5] "ohm" Vector__XXX
 SG_ SpecialIgnitorLoop85Resistance : 1504|16@1+ (0.1,0) [0|6425.5] "ohm" Vector__XXX
 SG_ SpecialIgnitorLoop84Resistance : 1488|16@1+ (0.1,0) [0|6425.5] "ohm" Vector__XXX
 SG_ SpecialIgnitorLoop83Resistance : 1472|16@1+ (0.1,0) [0|6425.5] "ohm" Vector__XXX
 SG_ SpecialIgnitorLoop82Resistance : 1456|16@1+ (0.1,0) [0|6425.5] "ohm" Vector__XXX
 SG_ SpecialIgnitorLoop81Resistance : 1440|16@1+ (0.1,0) [0|6425.5] "ohm" Vector__XXX
 SG_ SpecialIgnitorLoop80Resistance : 1424|16@1+ (0.1,0) [0|6425.5] "ohm" Vector__XXX
 SG_ SpecialIgnitorLoop79Resistance : 1408|16@1+ (0.1,0) [0|6425.5] "ohm" Vector__XXX
 SG_ SpecialIgnitorLoop78Resistance : 1392|16@1+ (0.1,0) [0|6425.5] "ohm" Vector__XXX
 SG_ SpecialIgnitorLoop77Resistance : 1376|16@1+ (0.1,0) [0|6425.5] "ohm" Vector__XXX
 SG_ SpecialIgnitorLoop76Resistance : 1360|16@1+ (0.1,0) [0|6425.5] "ohm" Vector__XXX
 SG_ SpecialIgnitorLoop75Resistance : 1344|16@1+ (0.1,0) [0|6425.5] "ohm" Vector__XXX
 SG_ SpecialIgnitorLoop74Resistance : 1328|16@1+ (0.1,0) [0|6425.5] "ohm" Vector__XXX
 SG_ SpecialIgnitorLoop73Resistance : 1312|16@1+ (0.1,0) [0|6425.5] "ohm" Vector__XXX
 SG_ SpecialIgnitorLoop72Resistance : 1296|16@1+ (0.1,0) [0|6425.5] "ohm" Vector__XXX
 SG_ SpecialIgnitorLoop71Resistance : 1280|16@1+ (0.1,0) [0|6425.5] "ohm" Vector__XXX
 SG_ SpecialIgnitorLoop70Resistance : 1264|16@1+ (0.1,0) [0|6425.5] "ohm" Vector__XXX
 SG_ SpecialIgnitorLoop69Resistance : 1248|16@1+ (0.1,0) [0|6425.5] "ohm" Vector__XXX
 SG_ SpecialIgnitorLoop68Resistance : 1232|16@1+ (0.1,0) [0|6425.5] "ohm" Vector__XXX
 SG_ SpecialIgnitorLoop67Resistance : 1216|16@1+ (0.1,0) [0|6425.5] "ohm" Vector__XXX
 SG_ SpecialIgnitorLoop66Resistance : 1200|16@1+ (0.1,0) [0|6425.5] "ohm" Vector__XXX
 SG_ SpecialIgnitorLoop65Resistance : 1184|16@1+ (0.1,0) [0|6425.5] "ohm" Vector__XXX
 SG_ SpecialIgnitorLoop64Resistance : 1168|16@1+ (0.1,0) [0|6425.5] "ohm" Vector__XXX
 SG_ SpecialIgnitorLoop63Resistance : 1152|16@1+ (0.1,0) [0|6425.5] "ohm" Vector__XXX
 SG_ SpecialIgnitorLoop61Resistance : 1120|16@1+ (0.1,0) [0|6425.5] "ohm" Vector__XXX
 SG_ SpecialIgnitorLoop60Resistance : 1104|16@1+ (0.1,0) [0|6425.5] "ohm" Vector__XXX
 SG_ SpecialIgnitorLoop59Resistance : 1088|16@1+ (0.1,0) [0|6425.5] "ohm" Vector__XXX
 SG_ SpecialIgnitorLoop58Resistance : 1072|16@1+ (0.1,0) [0|6425.5] "ohm" Vector__XXX
 SG_ SpecialIgnitorLoop57Resistance : 1056|16@1+ (0.1,0) [0|6425.5] "ohm" Vector__XXX
 SG_ SpecialIgnitorLoop56Resistance : 1040|16@1+ (0.1,0) [0|6425.5] "ohm" Vector__XXX
 SG_ SpecialIgnitorLoop55Resistance : 1024|16@1+ (0.1,0) [0|6425.5] "ohm" Vector__XXX
 SG_ SpecialIgnitorLoop54Resistance : 1008|16@1+ (0.1,0) [0|6425.5] "ohm" Vector__XXX
 SG_ SpecialIgnitorLoop53Resistance : 992|16@1+ (0.1,0) [0|6425.5] "ohm" Vector__XXX
 SG_ SpecialIgnitorLoop52Resistance : 976|16@1+ (0.1,0) [0|6425.5] "ohm" Vector__XXX
 SG_ SpecialIgnitorLoop51Resistance : 960|16@1+ (0.1,0) [0|6425.5] "ohm" Vector__XXX
 SG_ SpecialIgnitorLoop50Resistance : 944|16@1+ (0.1,0) [0|6425.5] "ohm" Vector__XXX
 SG_ SpecialIgnitorLoop49Resistance : 928|16@1+ (0.1,0) [0|6425.5] "ohm" Vector__XXX
 SG_ SpecialIgnitorLoop48Resistance : 912|16@1+ (0.1,0) [0|6425.5] "ohm" Vector__XXX
 SG_ SpecialIgnitorLoop47Resistance : 896|16@1+ (0.1,0) [0|6425.5] "ohm" Vector__XXX
 SG_ SpecialIgnitorLoop46Resistance : 880|16@1+ (0.1,0) [0|6425.5] "ohm" Vector__XXX
 SG_ SpecialIgnitorLoop45Resistance : 864|16@1+ (0.1,0) [0|6425.5] "ohm" Vector__XXX
 SG_ SpecialIgnitorLoop44Resistance : 848|16@1+ (0.1,0) [0|6425.5] "ohm" Vector__XXX
 SG_ SpecialIgnitorLoop43Resistance : 832|16@1+ (0.1,0) [0|6425.5] "ohm" Vector__XXX
 SG_ SpecialIgnitorLoop42Resistance : 816|16@1+ (0.1,0) [0|6425.5] "ohm" Vector__XXX
 SG_ SpecialIgnitorLoop41Resistance : 800|16@1+ (0.1,0) [0|6425.5] "ohm" Vector__XXX
 SG_ SpecialIgnitorLoop40Resistance : 784|16@1+ (0.1,0) [0|6425.5] "ohm" Vector__XXX
 SG_ SpecialIgnitorLoop39Resistance : 768|16@1+ (0.1,0) [0|6425.5] "ohm" Vector__XXX
 SG_ SpecialIgnitorLoop38Resistance : 752|16@1+ (0.1,0) [0|6425.5] "ohm" Vector__XXX
 SG_ SpecialIgnitorLoop37Resistance : 736|16@1+ (0.1,0) [0|6425.5] "ohm" Vector__XXX
 SG_ SpecialIgnitorLoop36Resistance : 720|16@1+ (0.1,0) [0|6425.5] "ohm" Vector__XXX
 SG_ SpecialIgnitorLoop35Resistance : 704|16@1+ (0.1,0) [0|6425.5] "ohm" Vector__XXX
 SG_ SpecialIgnitorLoop34Resistance : 688|16@1+ (0.1,0) [0|6425.5] "ohm" Vector__XXX
 SG_ SpecialIgnitorLoop33Resistance : 672|16@1+ (0.1,0) [0|6425.5] "ohm" Vector__XXX
 SG_ SpecialIgnitorLoop32Resistance : 656|16@1+ (0.1,0) [0|6425.5] "ohm" Vector__XXX
 SG_ SpecialIgnitorLoop31Resistance : 640|16@1+ (0.1,0) [0|6425.5] "ohm" Vector__XXX
 SG_ SpecialIgnitorLoop30Resistance : 624|16@1+ (0.1,0) [0|6425.5] "ohm" Vector__XXX
 SG_ SpecialIgnitorLoop29Resistance : 608|16@1+ (0.1,0) [0|6425.5] "ohm" Vector__XXX
 SG_ SpecialIgnitorLoop28Resistance : 592|16@1+ (0.1,0) [0|6425.5] "ohm" Vector__XXX
 SG_ SpecialIgnitorLoop27Resistance : 576|16@1+ (0.1,0) [0|6425.5] "ohm" Vector__XXX
 SG_ SpecialIgnitorLoop26Resistance : 560|16@1+ (0.1,0) [0|6425.5] "ohm" Vector__XXX
 SG_ SpecialIgnitorLoop25Resistance : 544|16@1+ (0.1,0) [0|6425.5] "ohm" Vector__XXX
 SG_ SpecialIgnitorLoop24Resistance : 528|16@1+ (0.1,0) [0|6425.5] "ohm" Vector__XXX
 SG_ SpecialIgnitorLoop23Resistance : 512|16@1+ (0.1,0) [0|6425.5] "ohm" Vector__XXX
 SG_ SpecialIgnitorLoop22Resistance : 496|16@1+ (0.1,0) [0|6425.5] "ohm" Vector__XXX
 SG_ SpecialIgnitorLoop21Resistance : 480|16@1+ (0.1,0) [0|6425.5] "ohm" Vector__XXX
 SG_ SpecialIgnitorLoop20Resistance : 464|16@1+ (0.1,0) [0|6425.5] "ohm" Vector__XXX
 SG_ SpecialIgnitorLoop19Resistance : 448|16@1+ (0.1,0) [0|6425.5] "ohm" Vector__XXX
 SG_ SpecialIgnitorLoop18Resistance : 432|16@1+ (0.1,0) [0|6425.5] "ohm" Vector__XXX
 SG_ SpecialIgnitorLoop17Resistance : 416|16@1+ (0.1,0) [0|6425.5] "ohm" Vector__XXX
 SG_ SpecialIgnitorLoop16Resistance : 400|16@1+ (0.1,0) [0|6425.5] "ohm" Vector__XXX
 SG_ SpecialIgnitorLoop15Resistance : 384|16@1+ (0.1,0) [0|6425.5] "ohm" Vector__XXX
 SG_ SpecialIgnitorLoop14Resistance : 368|16@1+ (0.1,0) [0|6425.5] "ohm" Vector__XXX
 SG_ SpecialIgnitorLoop13Resistance : 352|16@1+ (0.1,0) [0|6425.5] "ohm" Vector__XXX
 SG_ SpecialIgnitorLoop12Resistance : 336|16@1+ (0.1,0) [0|6425.5] "ohm" Vector__XXX
 SG_ SpecialIgnitorLoop11Resistance : 320|16@1+ (0.1,0) [0|6425.5] "ohm" Vector__XXX
 SG_ SpecialIgnitorLoop10Resistance : 304|16@1+ (0.1,0) [0|6425.5] "ohm" Vector__XXX
 SG_ SpecialIgnitorLoop9Resistance : 288|16@1+ (0.1,0) [0|6425.5] "ohm" Vector__XXX
 SG_ SpecialIgnitorLoop8Resistance : 272|16@1+ (0.1,0) [0|6425.5] "ohm" Vector__XXX
 SG_ SpecialIgnitorLoop7Resistance : 256|16@1+ (0.1,0) [0|6425.5] "ohm" Vector__XXX
 SG_ SpecialIgnitorLoop6Resistance : 240|16@1+ (0.1,0) [0|6425.5] "ohm" Vector__XXX
 SG_ SpecialIgnitorLoop5Resistance : 224|16@1+ (0.1,0) [0|6425.5] "ohm" Vector__XXX
 SG_ SpecialIgnitorLoop4Resistance : 208|16@1+ (0.1,0) [0|6425.5] "ohm" Vector__XXX
 SG_ SpecialIgnitorLoop3Resistance : 192|16@1+ (0.1,0) [0|6425.5] "ohm" Vector__XXX
 SG_ SpecialIgnitorLoop2Resistance : 176|16@1+ (0.1,0) [0|6425.5] "ohm" Vector__XXX
 SG_ SpecialIgnitorLoop1Resistance : 160|16@1+ (0.1,0) [0|6425.5] "ohm" Vector__XXX
 SG_ SdBagIgnitorLoop2RightResistance : 144|16@1+ (0.1,0) [0|6425.5] "ohm" Vector__XXX
 SG_ SdBagIgnitorLoop1RightResistance : 128|16@1+ (0.1,0) [0|6425.5] "ohm" Vector__XXX
 SG_ SdeBagIgnitorLoop2LeftResistance : 112|16@1+ (0.1,0) [0|6425.5] "ohm" Vector__XXX
 SG_ SdeBagIgnitorLoop1LeftResistance : 96|16@1+ (0.1,0) [0|6425.5] "ohm" Vector__XXX
 SG_ PssngrBltTnsnrIgntrLopResistance : 80|16@1+ (0.1,0) [0|6425.5] "ohm" Vector__XXX
 SG_ DrvrBltTnsnrIgntorLoopResistance : 64|16@1+ (0.1,0) [0|6425.5] "ohm" Vector__XXX
 SG_ PssngrArbgIgntrLp2ndStgRsistance : 48|16@1+ (0.1,0) [0|6425.5] "ohm" Vector__XXX
 SG_ DrvrArbgIgntrLp2ndStgeResistance : 32|16@1+ (0.1,0) [0|6425.5] "ohm" Vector__XXX
 SG_ PssngrArbgIgntrLp1stStgRsistance : 16|16@1+ (0.1,0) [0|6425.5] "ohm" Vector__XXX
 SG_ DrvrArbgIgntrLp1stStgeResistance : 0|16@1+ (0.1,0) [0|6425.5] "ohm" Vector__XXX

BO_ 2566719998 HRLFC: 8 Vector__XXX
 SG_ HighResolutionEngTotalFuelUsed : 32|32@1+ (0.001,0) [0|4211081.215] "L" Vector__XXX
 SG_ HighResolutionEngTripFuel : 0|32@1+ (0.001,0) [0|4211081.215] "L" Vector__XXX

BO_ 2565877502 EngTrboWastegateActuatorCtrlCmd: 8 Vector__XXX
 SG_ EngTurboWastegateActuator2Cmd : 16|16@1+ (1,0) [0|160.6375] "%" Vector__XXX
 SG_ EngTurboWastegateActuator1Cmd : 0|16@1+ (1,0) [0|160.6375] "%" Vector__XXX

BO_ 2566713854 EngTrbWstgteActuatorInformation: 8 Vector__XXX
 SG_ EngTrbWstgtActtr2OperationStatus : 12|4@1+ (1,0) [0|15] "" Vector__XXX
 SG_ EngTrbWstgtActtr1OperationStatus : 8|4@1+ (1,0) [0|15] "" Vector__XXX
 SG_ EngTrbWstgateActuator2TempStatus : 5|3@1+ (1,0) [0|7] "" Vector__XXX
 SG_ EngTrbWstgtActtor2PreliminaryFMI : 0|5@1+ (1,0) [0|31] "" Vector__XXX

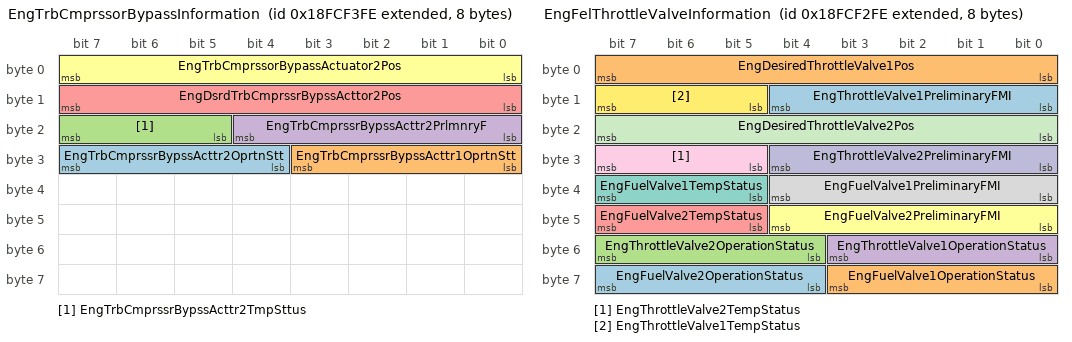
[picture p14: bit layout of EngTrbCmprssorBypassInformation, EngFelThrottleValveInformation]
BO_ 2566714366 EngTrbCmprssorBypassInformation: 8 Vector__XXX
 SG_ EngTrbCmprssrBypssActtr2OprtnStt : 28|4@1+ (1,0) [0|15] "" Vector__XXX
 SG_ EngTrbCmprssrBypssActtr1OprtnStt : 24|4@1+ (1,0) [0|15] "" Vector__XXX
 SG_ EngTrbCmprssrBypssActtr2TmpSttus : 21|3@1+ (1,0) [0|7] "" Vector__XXX
 SG_ EngTrbCmprssrBypssActtr2PrlmnryF : 16|5@1+ (1,0) [0|31] "" Vector__XXX
 SG_ EngDsrdTrbCmprssrBypssActtor2Pos : 8|8@1+ (1,0) [0|100] "%" Vector__XXX
 SG_ EngTrbCmprssorBypassActuator2Pos : 0|8@1+ (0.4,0) [0|100] "%" Vector__XXX

BO_ 2566714110 EngFelThrottleValveInformation: 8 Vector__XXX
 SG_ EngFuelValve2OperationStatus : 60|4@1+ (1,0) [0|15] "" Vector__XXX
 SG_ EngFuelValve1OperationStatus : 56|4@1+ (1,0) [0|15] "" Vector__XXX
 SG_ EngThrottleValve2OperationStatus : 52|4@1+ (1,0) [0|15] "" Vector__XXX
 SG_ EngThrottleValve1OperationStatus : 48|4@1+ (1,0) [0|15] "" Vector__XXX
 SG_ EngFuelValve2TempStatus : 45|3@1+ (1,0) [0|7] "" Vector__XXX
 SG_ EngFuelValve2PreliminaryFMI : 40|5@1+ (1,0) [0|31] "" Vector__XXX
 SG_ EngFuelValve1TempStatus : 37|3@1+ (1,0) [0|7] "" Vector__XXX
 SG_ EngFuelValve1PreliminaryFMI : 32|5@1+ (1,0) [0|31] "" Vector__XXX
 SG_ EngThrottleValve2TempStatus : 29|3@1+ (1,0) [0|7] "" Vector__XXX
 SG_ EngThrottleValve2PreliminaryFMI : 24|5@1+ (1,0) [0|31] "" Vector__XXX
 SG_ EngDesiredThrottleValve2Pos : 16|8@1+ (1,0) [0|100] "%" Vector__XXX
 SG_ EngThrottleValve1TempStatus : 13|3@1+ (1,0) [0|7] "" Vector__XXX
 SG_ EngThrottleValve1PreliminaryFMI : 8|5@1+ (1,0) [0|31] "" Vector__XXX
 SG_ EngDesiredThrottleValve1Pos : 0|8@1+ (1,0) [0|100] "%" Vector__XXX

BO_ 2566717438 ET5: 8 Vector__XXX
 SG_ EngExhstGsRcrcltn2MxerIntakeTemp : 16|16@1+ (0.03125,-273) [-273|1734.96875] "deg C" Vector__XXX
 SG_ EngExhaustGasRecirculation2Temp : 0|16@1+ (0.03125,-273) [-273|1734.96875] "deg C" Vector__XXX

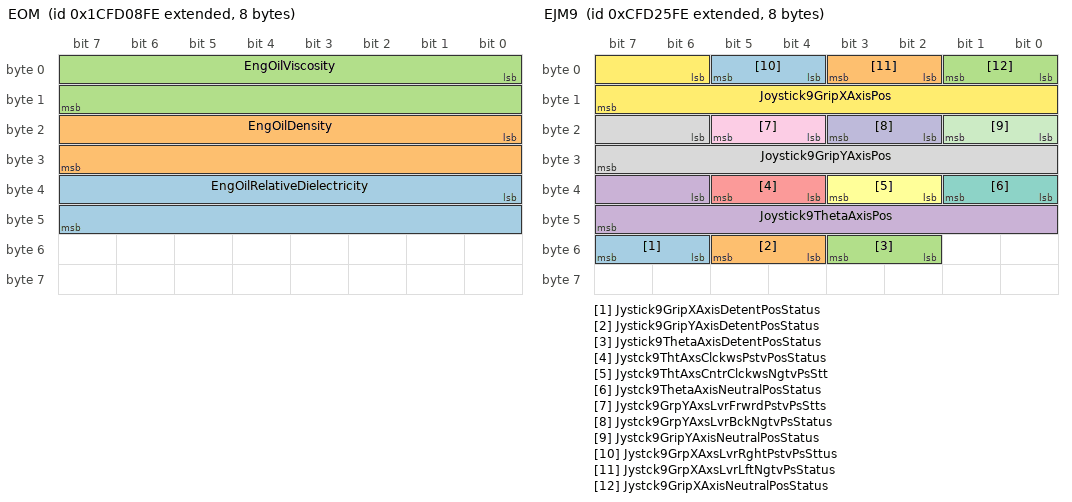
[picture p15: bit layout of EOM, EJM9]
BO_ 2633828606 EOM: 8 Vector__XXX
 SG_ EngOilRelativeDielectricity : 32|16@1+ (0.000122076103027,0) [0|7.844] "" Vector__XXX
 SG_ EngOilDensity : 16|16@1+ (3.051902575675E-005,0) [0|1.961] "g/cc" Vector__XXX
 SG_ EngOilViscosity : 0|16@1+ (0.015625,0) [0|1003.984375] "Cp" Vector__XXX

BO_ 2499607550 EMAP: 8 Vector__XXX
 SG_ EngExhstMnfldBnk2FlwBlncVlvActtr : 16|16@1+ (0.0025,0) [0|160.6375] "%" Vector__XXX
 SG_ EngExhstMnfldBnk1FlwBlncVlvActtr : 0|16@1+ (0.0025,0) [0|160.6375] "%" Vector__XXX

BO_ 2633825534 EMAC: 8 Vector__XXX
 SG_ EngExhstMnfldBnk2FlwBlncVlvActtr : 16|16@1+ (1,0) [0|160.6375] "%" Vector__XXX
 SG_ EngExhstMnfldBnk1FlwBlncVlvActtr : 0|16@1+ (1,0) [0|160.6375] "%" Vector__XXX

BO_ 2365400574 EJM9: 8 Vector__XXX
 SG_ Jystick9GripXAxisDetentPosStatus : 54|2@1+ (1,0) [0|3] "" Vector__XXX
 SG_ Jystick9GripYAxisDetentPosStatus : 52|2@1+ (1,0) [0|3] "" Vector__XXX
 SG_ Jystick9ThetaAxisDetentPosStatus : 50|2@1+ (1,0) [0|3] "" Vector__XXX
 SG_ Joystick9ThetaAxisPos : 38|10@1+ (1,0) [0|102] "%" Vector__XXX
 SG_ Jystck9ThtAxsClckwsPstvPosStatus : 36|2@1+ (1,0) [0|3] "" Vector__XXX
 SG_ Jystck9ThtAxsCntrClckwsNgtvPsStt : 34|2@1+ (1,0) [0|3] "" Vector__XXX
 SG_ Jystck9ThetaAxisNeutralPosStatus : 32|2@1+ (1,0) [0|3] "" Vector__XXX
 SG_ Joystick9GripYAxisPos : 22|10@1+ (1,0) [0|102] "%" Vector__XXX
 SG_ Jystck9GrpYAxsLvrFrwrdPstvPsStts : 20|2@1+ (1,0) [0|3] "" Vector__XXX
 SG_ Jystck9GrpYAxsLvrBckNgtvPsStatus : 18|2@1+ (1,0) [0|3] "" Vector__XXX
 SG_ Jystck9GripYAxisNeutralPosStatus : 16|2@1+ (1,0) [0|3] "" Vector__XXX
 SG_ Joystick9GripXAxisPos : 6|10@1+ (1,0) [0|102] "%" Vector__XXX
 SG_ Jystck9GrpXAxsLvrRghtPstvPsSttus : 4|2@1+ (1,0) [0|3] "" Vector__XXX
 SG_ Jystck9GrpXAxsLvrLftNgtvPsStatus : 2|2@1+ (1,0) [0|3] "" Vector__XXX
 SG_ Jystck9GripXAxisNeutralPosStatus : 0|2@1+ (1,0) [0|3] "" Vector__XXX

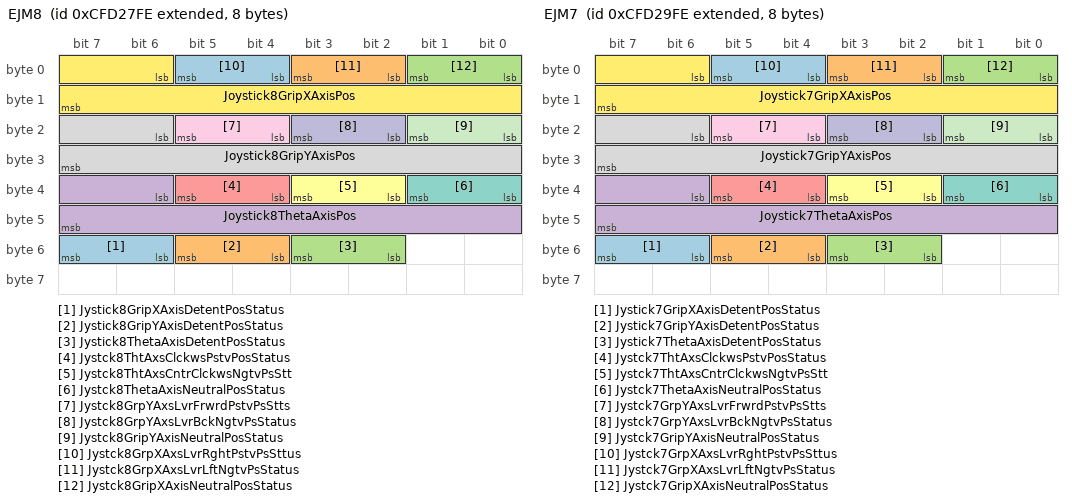
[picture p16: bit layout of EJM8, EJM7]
BO_ 2365401086 EJM8: 8 Vector__XXX
 SG_ Jystick8GripXAxisDetentPosStatus : 54|2@1+ (1,0) [0|3] "" Vector__XXX
 SG_ Jystick8GripYAxisDetentPosStatus : 52|2@1+ (1,0) [0|3] "" Vector__XXX
 SG_ Jystick8ThetaAxisDetentPosStatus : 50|2@1+ (1,0) [0|3] "" Vector__XXX
 SG_ Joystick8ThetaAxisPos : 38|10@1+ (1,0) [0|102] "%" Vector__XXX
 SG_ Jystck8ThtAxsClckwsPstvPosStatus : 36|2@1+ (1,0) [0|3] "" Vector__XXX
 SG_ Jystck8ThtAxsCntrClckwsNgtvPsStt : 34|2@1+ (1,0) [0|3] "" Vector__XXX
 SG_ Jystck8ThetaAxisNeutralPosStatus : 32|2@1+ (1,0) [0|3] "" Vector__XXX
 SG_ Joystick8GripYAxisPos : 22|10@1+ (1,0) [0|102] "%" Vector__XXX
 SG_ Jystck8GrpYAxsLvrFrwrdPstvPsStts : 20|2@1+ (1,0) [0|3] "" Vector__XXX
 SG_ Jystck8GrpYAxsLvrBckNgtvPsStatus : 18|2@1+ (1,0) [0|3] "" Vector__XXX
 SG_ Jystck8GripYAxisNeutralPosStatus : 16|2@1+ (1,0) [0|3] "" Vector__XXX
 SG_ Joystick8GripXAxisPos : 6|10@1+ (1,0) [0|102] "%" Vector__XXX
 SG_ Jystck8GrpXAxsLvrRghtPstvPsSttus : 4|2@1+ (1,0) [0|3] "" Vector__XXX
 SG_ Jystck8GrpXAxsLvrLftNgtvPsStatus : 2|2@1+ (1,0) [0|3] "" Vector__XXX
 SG_ Jystck8GripXAxisNeutralPosStatus : 0|2@1+ (1,0) [0|3] "" Vector__XXX

BO_ 2365401598 EJM7: 8 Vector__XXX
 SG_ Jystick7GripXAxisDetentPosStatus : 54|2@1+ (1,0) [0|3] "" Vector__XXX
 SG_ Jystick7GripYAxisDetentPosStatus : 52|2@1+ (1,0) [0|3] "" Vector__XXX
 SG_ Jystick7ThetaAxisDetentPosStatus : 50|2@1+ (1,0) [0|3] "" Vector__XXX
 SG_ Joystick7ThetaAxisPos : 38|10@1+ (1,0) [0|102] "%" Vector__XXX
 SG_ Jystck7ThtAxsClckwsPstvPosStatus : 36|2@1+ (1,0) [0|3] "" Vector__XXX
 SG_ Jystck7ThtAxsCntrClckwsNgtvPsStt : 34|2@1+ (1,0) [0|3] "" Vector__XXX
 SG_ Jystck7ThetaAxisNeutralPosStatus : 32|2@1+ (1,0) [0|3] "" Vector__XXX
 SG_ Joystick7GripYAxisPos : 22|10@1+ (1,0) [0|102] "%" Vector__XXX
 SG_ Jystck7GrpYAxsLvrFrwrdPstvPsStts : 20|2@1+ (1,0) [0|3] "" Vector__XXX
 SG_ Jystck7GrpYAxsLvrBckNgtvPsStatus : 18|2@1+ (1,0) [0|3] "" Vector__XXX
 SG_ Jystck7GripYAxisNeutralPosStatus : 16|2@1+ (1,0) [0|3] "" Vector__XXX
 SG_ Joystick7GripXAxisPos : 6|10@1+ (1,0) [0|102] "%" Vector__XXX
 SG_ Jystck7GrpXAxsLvrRghtPstvPsSttus : 4|2@1+ (1,0) [0|3] "" Vector__XXX
 SG_ Jystck7GrpXAxsLvrLftNgtvPsStatus : 2|2@1+ (1,0) [0|3] "" Vector__XXX
 SG_ Jystck7GripXAxisNeutralPosStatus : 0|2@1+ (1,0) [0|3] "" Vector__XXX

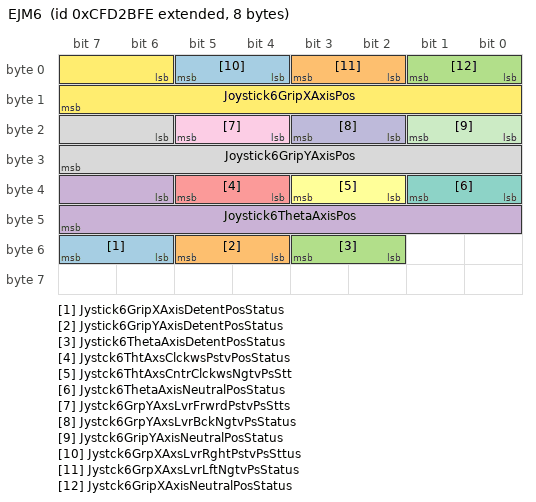
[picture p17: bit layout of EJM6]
BO_ 2365402110 EJM6: 8 Vector__XXX
 SG_ Jystick6GripXAxisDetentPosStatus : 54|2@1+ (1,0) [0|3] "" Vector__XXX
 SG_ Jystick6GripYAxisDetentPosStatus : 52|2@1+ (1,0) [0|3] "" Vector__XXX
 SG_ Jystick6ThetaAxisDetentPosStatus : 50|2@1+ (1,0) [0|3] "" Vector__XXX
 SG_ Joystick6ThetaAxisPos : 38|10@1+ (1,0) [0|102] "%" Vector__XXX
 SG_ Jystck6ThtAxsClckwsPstvPosStatus : 36|2@1+ (1,0) [0|3] "" Vector__XXX
 SG_ Jystck6ThtAxsCntrClckwsNgtvPsStt : 34|2@1+ (1,0) [0|3] "" Vector__XXX
 SG_ Jystck6ThetaAxisNeutralPosStatus : 32|2@1+ (1,0) [0|3] "" Vector__XXX
 SG_ Joystick6GripYAxisPos : 22|10@1+ (1,0) [0|102] "%" Vector__XXX
 SG_ Jystck6GrpYAxsLvrFrwrdPstvPsStts : 20|2@1+ (1,0) [0|3] "" Vector__XXX
 SG_ Jystck6GrpYAxsLvrBckNgtvPsStatus : 18|2@1+ (1,0) [0|3] "" Vector__XXX
 SG_ Jystck6GripYAxisNeutralPosStatus : 16|2@1+ (1,0) [0|3] "" Vector__XXX
 SG_ Joystick6GripXAxisPos : 6|10@1+ (1,0) [0|102] "%" Vector__XXX
 SG_ Jystck6GrpXAxsLvrRghtPstvPsSttus : 4|2@1+ (1,0) [0|3] "" Vector__XXX
 SG_ Jystck6GrpXAxsLvrLftNgtvPsStatus : 2|2@1+ (1,0) [0|3] "" Vector__XXX
 SG_ Jystck6GripXAxisNeutralPosStatus : 0|2@1+ (1,0) [0|3] "" Vector__XXX

CM_ BU_ HitchControl "Straight truck hitch (NOT Agricultural hitch � it is in IG 2) ";
CM_ BO_ 3221225472 "This is a message for not used signals, created by Vector CANdb++ DBC OLE DB Provider.";
CM_ SG_ 3221225472 TrailerWeight "Total mass of freight-carrying vehicle designed to be pulled by truck, including the weight of the contents.";
CM_ SG_ 3221225472 ReferenceTirePressSetting "Reference value of the tire pressure setting as basis for the tire pressure monitoring";
CM_ SG_ 3221225472 ReferenceTirePress "Reference value of the tire pressure as basis for the tire pressure monitoring";
CM_ SG_ 3221225472 TirePressThresholdDetection "Signal indicating the pressure level of the tire. The levels defined represent different pressure conditions of the tire:";
CM_ SG_ 3221225472 TireAirLeakageRate "The pressure loss rate of a tire.";
CM_ SG_ 3221225472 CTIWheelEndElectricalFault "Indicates the status of electrical fault on CTI wheel interface.";
CM_ SG_ 3221225472 CTITireStatus "Indicates the status of the tire.";
CM_ SG_ 3221225472 CTIWheelSensorStatus "Indicates whether the wheel is being monitored by the CTI controller.";
CM_ SG_ 3221225472 TireTemp "Temperature at the surface of the tire sidewall.";
CM_ SG_ 3221225472 TirePress "Pressure at which air is contained in cavity formed by tire and rim.";
CM_ SG_ 3221225472 EngTurningGearEngaged "Status signal which indicates that the turning gear is engaged. The turning gear is used to turn the flywheel/crankshaft,";
CM_ SG_ 2632975265 PSWErrDriveChip "The ratio of actual position of the analog engine speed/torque request input device (such as an accelerator pedal or";
CM_ SG_ 2632975265 PSWErrShortDrive724_U19 "The ratio of actual position of the analog engine speed/torque request input device (such as an accelerator pedal or";
CM_ SG_ 2632975265 PSWErrOpenDrive724_U19 "The ratio of actual position of the analog engine speed/torque request input device (such as an accelerator pedal or";
CM_ SG_ 2632975264 PSWErrShortDrive724_U9 "The ratio of actual position of the analog engine speed/torque request input device (such as an accelerator pedal or";
CM_ SG_ 2632975264 PSWErrShortDrive724_U6 "The ratio of actual position of the analog engine speed/torque request input device (such as an accelerator pedal or";
CM_ SG_ 2632975264 PSWErrShortDrive724_U13 "The ratio of actual position of the analog engine speed/torque request input device (such as an accelerator pedal or";
CM_ SG_ 2632975264 PSWErrShortDrive724_U12 "The ratio of actual position of the analog engine speed/torque request input device (such as an accelerator pedal or";
CM_ SG_ 2632975264 PSWErrOpenDrive724_U9 "The ratio of actual position of the analog engine speed/torque request input device (such as an accelerator pedal or";
CM_ SG_ 2632975264 PSWErrOpenDrive724_U6 "The ratio of actual position of the analog engine speed/torque request input device (such as an accelerator pedal or";
CM_ SG_ 2632975264 PSWErrOpenDrive724_U13 "The ratio of actual position of the analog engine speed/torque request input device (such as an accelerator pedal or";
CM_ SG_ 2632975264 PSWErrOpenDrive724_U12 "The ratio of actual position of the analog engine speed/torque request input device (such as an accelerator pedal or";
CM_ SG_ 2632975251 PSWErrInValXR "The ratio of actual position of the analog engine speed/torque request input device (such as an accelerator pedal or";
CM_ SG_ 2632975251 PSWErrInValXL "The ratio of actual position of the analog engine speed/torque request input device (such as an accelerator pedal or";
CM_ SG_ 2632975251 PSWErrInValTr "The ratio of actual position of the analog engine speed/torque request input device (such as an accelerator pedal or";
CM_ SG_ 2632975250 PSWErrInValRR "The ratio of actual position of the analog engine speed/torque request input device (such as an accelerator pedal or";
CM_ SG_ 2632975250 PSWErrInValRL "The ratio of actual position of the analog engine speed/torque request input device (such as an accelerator pedal or";
CM_ SG_ 2632975250 PSWErrInValFR "The ratio of actual position of the analog engine speed/torque request input device (such as an accelerator pedal or";
CM_ SG_ 2632975250 PSWErrInValFL "The ratio of actual position of the analog engine speed/torque request input device (such as an accelerator pedal or";
CM_ SG_ 2632975248 ASRRLowSideSt "The ratio of actual position of the analog engine speed/torque request input device (such as an accelerator pedal or";
CM_ SG_ 2632975248 ASRFLowSideSt "The ratio of actual position of the analog engine speed/torque request input device (such as an accelerator pedal or";
CM_ SG_ 2632975233 PSWWheelSpeedXR "The ratio of actual position of the analog engine speed/torque request input device (such as an accelerator pedal or";
CM_ SG_ 2632975233 PSWWheelSpeedXL "The ratio of actual position of the analog engine speed/torque request input device (such as an accelerator pedal or";
CM_ SG_ 2632975232 PSWWheelSpeedRR "The ratio of actual position of the analog engine speed/torque request input device (such as an accelerator pedal or";
CM_ SG_ 2632975232 PSWWheelSpeedRL "The ratio of actual position of the analog engine speed/torque request input device (such as an accelerator pedal or";
CM_ SG_ 2632975232 PSWWheelSpeedFR "The ratio of actual position of the analog engine speed/torque request input device (such as an accelerator pedal or";
CM_ SG_ 2632975232 PSWWheelSpeedFL "The ratio of actual position of the analog engine speed/torque request input device (such as an accelerator pedal or";
CM_ SG_ 2148676695 RearAxleRightWheelSpeed "High resolution measurement of the speed of the right wheel on the rear axle.";
CM_ SG_ 2148676695 RearAxleLeftWheelSpeed "High resolution measurement of the speed of the left wheel on the rear axle.";
CM_ SG_ 2148676695 FrontAxleRightWheelSpeed "High resolution measurement of the speed of the right wheel on the front axle.";
CM_ SG_ 2148676695 FrontAxleLeftWheelSpeed "High resolution measurement of the speed of the left wheel on the front axle.";
CM_ BO_ 2148676694 "Alternate Fuel 1";
CM_ SG_ 2148676694 A_A_ADC_wheelSPD "Switch signal which indicates that the pressure in the coolant circuit of an air conditioning system is high and the fan may";
CM_ SG_ 2148676694 A_A_ADC_errWssGap "Switch signal which indicates that the pressure in the coolant circuit of an air conditioning system is high and the fan may";
CM_ SG_ 2148676694 A_A_ADC_adcvalue "Switch signal which indicates that the pressure in the coolant circuit of an air conditioning system is high and the fan may";
CM_ BO_ 2297441790 "The acceleration sensor message shall provide a measurement of the vehicle's acceleration in the lateral, longitudinal,
and vertical axes.";
CM_ SG_ 2297441790 SpprtVrblTrnsRpttnRtFrAcclrtnSns "Indicates which acceleration transmission rate are supported by the ECU in addition to the required 10 ms transmission";
CM_ SG_ 2297441790 VrtclAcclrtnExRangeFigureOfMerit "Figure of merit for vertical acceleration measurement.";
CM_ SG_ 2297441790 LngtdnlAcclrtnExRngFigureOfMerit "Figure of merit for longitudinal acceleration measurement.";
CM_ SG_ 2297441790 LtrlAcclrtonExRangeFigureOfMerit "Figure of merit for lateral acceleration measurement.";
CM_ SG_ 2297441790 VerticalAccelerationExRange "Indicates vertical acceleration of the vehicle and the effect of gravity. A positive vertical acceleration signal results when";
CM_ SG_ 2297441790 LateralAccelerationExRange "Indicates lateral acceleration of the vehicle. A positive lateral acceleration signal results when the vehicle is accelerated";
CM_ SG_ 2297441790 LongitudinalAccelerationExRange "Indicates longitudinal acceleration of the vehicle. A positive longitudinal acceleration signal results when the vehicle";
CM_ BO_ 2566712062 "Hybrid system voltage information.";
CM_ SG_ 2566712062 HybridBatteryPackRemainingCharge "Indicates the hybrid battery pack remaining charge. 0% means no charge remaining, 100% means full charge remaining.";
CM_ BO_ 2364549630 "The Slope Sensor Information 2 message shall provide a measurement of the vehicle's extended pitch angle and a";
CM_ SG_ 2364549630 RllAndPtchExRngMasurementLatency "Time between start of sensor processing and CAN transmission";
CM_ SG_ 2364549630 RollAngleExRangeFigureOfMerit "Figure of merit for roll angle measurement.";
CM_ SG_ 2364549630 RollAngleExRangeCompensation "Compensated mode for the roll measurement. Compensation is the use of multiple sensors together to enhance the";
CM_ SG_ 2364549630 PitchAngleExRangeFigureOfMerit "Figure of merit for pitch angle measurement.";
CM_ SG_ 2364549630 PitchAngleExRangeCompensation "Compensated mode for the pitch measurement. Compensation is the use of multiple sensors together to enhance the";
CM_ SG_ 2364549630 RollAngleExRange "The angle between the vehicle y-axis and the ground plane.";
CM_ SG_ 2364549630 PitchAngleExRange "The angle between the vehicle x-axis and the ground plane.";
CM_ BO_ 2499614462 "Message containing status of Occupant Classification System for driver, passenger and rear seating positions. The PGN";
CM_ SG_ 2499614462 OccpntClssficationSystem10Status "State of Occupant Classification System for seat position 10.";
CM_ SG_ 2499614462 OccpntClssificationSystem9Status "State of Occupant Classification System for seat position 9.";
CM_ SG_ 2499614462 OccpntClssificationSystem8Status "State of Occupant Classification System for seat position 8.";
CM_ SG_ 2499614462 OccpntClssificationSystem7Status "State of Occupant Classification System for seat position 7.";
CM_ SG_ 2499614462 OccpntClssificationSystem6Status "State of Occupant Classification System for seat position 6.";
CM_ SG_ 2499614462 OccpntClssificationSystem5Status "State of Occupant Classification System for seat position 5.";
CM_ SG_ 2499614462 OccpntClssificationSystem4Status "State of Occupant Classification System for seat position 4.";
CM_ SG_ 2499614462 OccpntClssificationSystem3Status "State of Occupant Classification System for seat position 3.";
CM_ SG_ 2499614462 PssngrOccpntClssfctnSystemStatus "State of Occupant Classification System for passenger.";
CM_ SG_ 2499614462 DrvrOccpntClssfctionSystemStatus "State of Occupant Classification System for driver.";
CM_ BO_ 2560098046 "Used to report the current state of the Noise Control System.";
CM_ SG_ 2560098046 CabNoiseCtrlTuningStatus "This parameter returns the current status of tuning function of the Cab Noise Control system. When the tuning state is";
CM_ SG_ 2560098046 CabNoiseCtrlStatus "This parameter returns the current status of the Cab Noise Control system.";
CM_ BO_ 2560163582 "Used to issue commands to the Noise Control System. This command PGN typically originates from either a Cab control";
CM_ SG_ 2560163582 CabNoiseCtrlTuningState "Command values for the Tuning State of the Cab Noise Control System. The Tuning State allows the Cab Noise Control";
CM_ SG_ 2560163582 CabNoiseCtrlState "Command signal to change the state of the Cab Noise Control System to on-line or off-line";
CM_ BO_ 2297441534 "Magnet Status Information 2";
CM_ SG_ 2297441534 DropRelayCtrl "Command signal used to Engage and Disengage the Drop Relay controlling a Steady-State Magnet.";
CM_ SG_ 2297441534 LiftRelayCtrl "Command signal used to Engage and Disengage the Lift Relay controlling a Steady-State Magnet.";
CM_ SG_ 2297441534 MaterialDropActiveStatus "The status of Material Drop Relay. When it is on, the generator generates reverse direction current so that the material";
CM_ SG_ 2297441534 MaterialLiftActiveStatus "The status of Material Lift Relay. When it is on, the generator generates forward direction current so that the material";
CM_ SG_ 2297441534 GneratorCurrentBoostActiveStatus "Status of generator current boost relay that can boost the generator output current for picking-up material operations.";
CM_ SG_ 2297441534 MaterialDropSwitch "This is a switch that can be used to enable the drop functionality of the Material Handler machine.";
CM_ SG_ 2297441534 MaterialLiftSwitch "This is a switch that can be used to enable the lift functionality of the Material Handler machine. When it is activated, the";
CM_ SG_ 2297441534 MagnetReverseCurrent "A reverse current being supplied to the electric magnet to reduce the forward current generated magnet field as quick as";
CM_ SG_ 2297441534 MagnetForwardCurrent "The forward current being supplied by the generator to the electric magnet to create a magnet field to lift material.";
CM_ BO_ 2566722302 "Magnet Status Information 1";
CM_ SG_ 2566722302 GeneratorDutyCycleExceededStatus "The status of the duty cycle of the generator usage, indicating if the generator has been on for too much time within a";
CM_ SG_ 2566722302 VoltageMonitorActiveStatus "Status of Voltage Monitor Relay. When it is activated, the Generator Voltage Monitor is connected to the generator output";
CM_ SG_ 2566722302 GensetEnableActiveStatus "Status of the Genset Enable Relay that enables or disables the Genset.";
CM_ SG_ 2566722302 ReverseCurrentRangeSetting "The operator setting for the Reverse Current. The setting defines the maximum reverse current. The actual current limits";
CM_ SG_ 2566722302 GensetSoftstartActiveStatus "The Genset Softstart Active Status refers to the status of the genset softstart relay. The moment the Genset System is";
CM_ SG_ 2566722302 Grapple_MagnetSelectionSwitch "This is a switch that can be used to select either the Grapple or Magnet function of the material handler machine.";
CM_ SG_ 2566722302 GnstSystmOtputVoltageRangeStatus "Status of generator voltage in or out of desired operating range.";
CM_ SG_ 2566722302 GeneratorOverheatStatus "The Status of Generator being Overheated.";
CM_ BO_ 2566722558 "This message carries data related to the configuration of the magnetic material handling system, possibly including the";
CM_ SG_ 2566722558 MagnetRatedPower "The rated power that the magnet can accept during material holding operations. Note that the magnet may experience";
CM_ SG_ 2566722558 MagnetBoostTime "The duration of time after the activation of the magnet circuit that a relatively high current is sent to the magnet for";
CM_ BO_ 2560032510 "Low Voltage Disconnect (LVD) Set Operating Mode is sent to the LVD to either manuallly override the normal LVD";
CM_ SG_ 2560032510 LwVltgDscnnctDsiredOperatingMode "Desired Operating Mode of the LVD. Used to issue a J1939 request to the LVD to change modes.";
CM_ BO_ 2566717950 "Status of the Low-Voltage Disconnect (LVD) device.";
CM_ SG_ 2566717950 LowVoltageDisconnectTemp "Internal temperature of the LVD.";
CM_ SG_ 2566717950 LwVltgeDisconnectVoutOutputState "State of the Vout Output from the LVD. Vout is the LVD's main internal, controllable, high-current output. If the LVD";
CM_ SG_ 2566717950 LowVoltageDisconnectOutput1State "State of the Output #1 from the LVD. Output #1 controls an external load or relay. This external load could be";
CM_ SG_ 2566717950 LowVoltageDisconnectOutput2State "State of the Output #2 from the LVD. Output #2 controls an external load or relay. This external load could be";
CM_ SG_ 2566717950 LowVoltageDisconnectOutput3State "State of the Output #3 from the LVD. Output #3 controls an external load or relay. This external load could be";
CM_ SG_ 2566717950 LwVltgDscnnctCrrentOperatingMode "Current operating mode of the LVD. The current mode is dependent on the state of the Manual Disconnect/Connect";
CM_ SG_ 2566717950 LwVltgDscnnectManualConnectState "State of the Manual Connect hardwired input to the LVD. Manual Connect is used to override the LVD's normal activlty";
CM_ SG_ 2566717950 LwVltgDscnnctMnalDisconnectState "State of the Manual Disconnect hardwired input to the LVD. Manual Disconnect is used to override the LVD's normal";
CM_ BO_ 2499604222 "This PGN will be used to communicate the reference elvation information for the land leveling system. It will";
CM_ SG_ 2499604222 BldReferenceElevationOffsetRight "Indicates the blade's right elevation offset with respect to the reference elevation. An offset of 0 m represents no offset";
CM_ SG_ 2499604222 BldeReferenceElevationOffsetLeft "Indicates the blade's left elevation offset with respect to the reference elevation. An offset of 0 m represents no offset";
CM_ SG_ 2499604222 BladeElevationDeviationRight "Indicate the blade's right elevation deviation with respect to the reference elevation. Serves as an indication of how far";
CM_ SG_ 2499604222 BladeElevationDeviationLeft "Indicate the blade's left elevation deviation with respect to the reference elevation. Serves as an indication of how far the";
CM_ BO_ 2358902526 "Used to transfer joystick lamp command informations which are used to switch on/off/blinking joystick 1...3 lamps 1...10.";
CM_ SG_ 2358902526 Joystick3Lamp10Cmd "Tells joystick 3 to switch on/off/blinking lamp 10.";
CM_ SG_ 2358902526 Joystick3Lamp9Cmd "Tells joystick 3 to switch on/off/blinking lamp 9.";
CM_ SG_ 2358902526 Joystick3Lamp8Cmd "Tells joystick 3 to switch on/off/blinking lamp 8.";
CM_ SG_ 2358902526 Joystick3Lamp7Cmd "Tells joystick 3 to switch on/off/blinking lamp 7.";
CM_ SG_ 2358902526 Joystick3Lamp6Cmd "Tells joystick 3 to switch on/off/blinking lamp 6.";
CM_ SG_ 2358902526 Joystick3Lamp5Cmd "Tells joystick 3 to switch on/off/blinking lamp 5.";
CM_ SG_ 2358902526 Joystick3Lamp4Cmd "Tells joystick 3 to switch on/off/blinking lamp 4.";
CM_ SG_ 2358902526 Joystick3Lamp3Cmd "Tells joystick 3 to switch on/off/blinking lamp 3.";
CM_ SG_ 2358902526 Joystick3Lamp2Cmd "Tells joystick 3 to switch on/off/blinking lamp 2.";
CM_ SG_ 2358902526 Joystick3Lamp1Cmd "Tells joystick 3 to switch on/off/blinking lamp 1.";
CM_ SG_ 2358902526 Joystick2Lamp10Cmd "Tells joystick 2 to switch on/off/blinking lamp 10.";
CM_ SG_ 2358902526 Joystick2Lamp9Cmd "Tells joystick 2 to switch on/off/blinking lamp 9.";
CM_ SG_ 2358902526 Joystick2Lamp8Cmd "Tells joystick 2 to switch on/off/blinking lamp 8.";
CM_ SG_ 2358902526 Joystick2Lamp7Cmd "Tells joystick 2 to switch on/off/blinking lamp 7.";
CM_ SG_ 2358902526 Joystick2Lamp6Cmd "Tells joystick 2 to switch on/off/blinking lamp 6.";
CM_ SG_ 2358902526 Joystick2Lamp5Cmd "Tells joystick 2 to switch on/off/blinking lamp 5.";
CM_ SG_ 2358902526 Joystick2Lamp4Cmd "Tells joystick 2 to switch on/off/blinking lamp 4.";
CM_ SG_ 2358902526 Joystick2Lamp3Cmd "Tells joystick 2 to switch on/off/blinking lamp 3.";
CM_ SG_ 2358902526 Joystick2Lamp2Cmd "Tells joystick 2 to switch on/off/blinking lamp 2.";
CM_ SG_ 2358902526 Joystick2Lamp1Cmd "Tells joystick 2 to switch on/off/blinking lamp 1.";
CM_ SG_ 2358902526 Joystick1Lamp10Cmd "Tells joystick 1 to switch on/off/blinking lamp 10.";
CM_ SG_ 2358902526 Joystick1Lamp9Cmd "Tells joystick 1 to switch on/off/blinking lamp 9.";
CM_ SG_ 2358902526 Joystick1Lamp8Cmd "Tells joystick 1 to switch on/off/blinking lamp 8.";
CM_ SG_ 2358902526 Joystick1Lamp7Cmd "Tells joystick 1 to switch on/off/blinking lamp 7.";
CM_ SG_ 2358902526 Joystick1Lamp6Cmd "Tells joystick 1 to switch on/off/blinking lamp 6.";
CM_ SG_ 2358902526 Joystick1Lamp5Cmd "Tells joystick 1 to switch on/off/blinking lamp 5.";
CM_ SG_ 2358902526 Joystick1Lamp4Cmd "Tells joystick 1 to switch on/off/blinking lamp 4.";
CM_ SG_ 2358902526 Joystick1Lamp3Cmd "Tells joystick 1 to switch on/off/blinking lamp 3.";
CM_ SG_ 2358902526 Joystick1Lamp2Cmd "Tells joystick 1 to switch on/off/blinking lamp 2.";
CM_ SG_ 2358902526 Joystick1Lamp1Cmd "Tells joystick 1 to switch on/off/blinking lamp 1.";
CM_ BO_ 2566711550 "Contains information about the intake valve actuation system control.";
CM_ SG_ 2566711550 IntkVlvActtnSystmOlPrss2SlndCtrl "Indicates the current command to the solenoid that controls the intake valve actuation system oil pressure 2 valve. This";
CM_ SG_ 2566711550 IntkVlvActtnSystmOlPrss1SlndCtrl "Indicates the current command to the solenoid that controls the intake valve actuation system oil pressure 1 valve. This";
CM_ BO_ 2633832958 "Message containing resistance values for every equipped ignitor loop of the restraint-system. (Maximum of 100 Ignitor";
CM_ SG_ 2633832958 SpecialIgnitorLoop90Resistance "Resistance of Special Ignitor Loop 90. Since there are many different vehicle types (e.g. truck, bus, firetruck or";
CM_ SG_ 2633832958 SpecialIgnitorLoop89Resistance "Resistance of Special Ignitor Loop 89. Since there are many different vehicle types (e.g. truck, bus, firetruck or";
CM_ SG_ 2633832958 SpecialIgnitorLoop88Resistance "Resistance of Special Ignitor Loop 88. Since there are many different vehicle types (e.g. truck, bus, firetruck or";
CM_ SG_ 2633832958 SpecialIgnitorLoop87Resistance "Resistance of Special Ignitor Loop 87. Since there are many different vehicle types (e.g. truck, bus, firetruck or";
CM_ SG_ 2633832958 SpecialIgnitorLoop86Resistance "Resistance of Special Ignitor Loop 86. Since there are many different vehicle types (e.g. truck, bus, firetruck or";
CM_ SG_ 2633832958 SpecialIgnitorLoop85Resistance "Resistance of Special Ignitor Loop 85. Since there are many different vehicle types (e.g. truck, bus, firetruck or";
CM_ SG_ 2633832958 SpecialIgnitorLoop84Resistance "Resistance of Special Ignitor Loop 84. Since there are many different vehicle types (e.g. truck, bus, firetruck or";
CM_ SG_ 2633832958 SpecialIgnitorLoop83Resistance "Resistance of Special Ignitor Loop 83. Since there are many different vehicle types (e.g. truck, bus, firetruck or";
CM_ SG_ 2633832958 SpecialIgnitorLoop82Resistance "Resistance of Special Ignitor Loop 82. Since there are many different vehicle types (e.g. truck, bus, firetruck or";
CM_ SG_ 2633832958 SpecialIgnitorLoop81Resistance "Resistance of Special Ignitor Loop 81. Since there are many different vehicle types (e.g. truck, bus, firetruck or";
CM_ SG_ 2633832958 SpecialIgnitorLoop80Resistance "Resistance of Special Ignitor Loop 80. Since there are many different vehicle types (e.g. truck, bus, firetruck or";
CM_ SG_ 2633832958 SpecialIgnitorLoop79Resistance "Resistance of Special Ignitor Loop 79. Since there are many different vehicle types (e.g. truck, bus, firetruck or";
CM_ SG_ 2633832958 SpecialIgnitorLoop78Resistance "Resistance of Special Ignitor Loop 78. Since there are many different vehicle types (e.g. truck, bus, firetruck or";
CM_ SG_ 2633832958 SpecialIgnitorLoop77Resistance "Resistance of Special Ignitor Loop 77. Since there are many different vehicle types (e.g. truck, bus, firetruck or";
CM_ SG_ 2633832958 SpecialIgnitorLoop76Resistance "Resistance of Special Ignitor Loop 76. Since there are many different vehicle types (e.g. truck, bus, firetruck or";
CM_ SG_ 2633832958 SpecialIgnitorLoop75Resistance "Resistance of Special Ignitor Loop 75. Since there are many different vehicle types (e.g. truck, bus, firetruck or";
CM_ SG_ 2633832958 SpecialIgnitorLoop74Resistance "Resistance of Special Ignitor Loop 74. Since there are many different vehicle types (e.g. truck, bus, firetruck or";
CM_ SG_ 2633832958 SpecialIgnitorLoop73Resistance "Resistance of Special Ignitor Loop 73. Since there are many different vehicle types (e.g. truck, bus, firetruck or";
CM_ SG_ 2633832958 SpecialIgnitorLoop72Resistance "Resistance of Special Ignitor Loop 72. Since there are many different vehicle types (e.g. truck, bus, firetruck or";
CM_ SG_ 2633832958 SpecialIgnitorLoop71Resistance "Resistance of Special Ignitor Loop 71. Since there are many different vehicle types (e.g. truck, bus, firetruck or";
CM_ SG_ 2633832958 SpecialIgnitorLoop70Resistance "Resistance of Special Ignitor Loop 70. Since there are many different vehicle types (e.g. truck, bus, firetruck or";
CM_ SG_ 2633832958 SpecialIgnitorLoop69Resistance "Resistance of Special Ignitor Loop 69. Since there are many different vehicle types (e.g. truck, bus, firetruck or";
CM_ SG_ 2633832958 SpecialIgnitorLoop68Resistance "Resistance of Special Ignitor Loop 68. Since there are many different vehicle types (e.g. truck, bus, firetruck or";
CM_ SG_ 2633832958 SpecialIgnitorLoop67Resistance "Resistance of Special Ignitor Loop 67. Since there are many different vehicle types (e.g. truck, bus, firetruck or";
CM_ SG_ 2633832958 SpecialIgnitorLoop66Resistance "Resistance of Special Ignitor Loop 66. Since there are many different vehicle types (e.g. truck, bus, firetruck or";
CM_ SG_ 2633832958 SpecialIgnitorLoop65Resistance "Resistance of Special Ignitor Loop 65. Since there are many different vehicle types (e.g. truck, bus, firetruck or";
CM_ SG_ 2633832958 SpecialIgnitorLoop64Resistance "Resistance of Special Ignitor Loop 64. Since there are many different vehicle types (e.g. truck, bus, firetruck or";
CM_ SG_ 2633832958 SpecialIgnitorLoop63Resistance "Resistance of Special Ignitor Loop 63. Since there are many different vehicle types (e.g. truck, bus, firetruck or";
CM_ SG_ 2633832958 SpecialIgnitorLoop61Resistance "Resistance of Special Ignitor Loop 61. Since there are many different vehicle types (e.g. truck, bus, firetruck or";
CM_ SG_ 2633832958 SpecialIgnitorLoop60Resistance "Resistance of Special Ignitor Loop 60. Since there are many different vehicle types (e.g. truck, bus, firetruck or";
CM_ SG_ 2633832958 SpecialIgnitorLoop59Resistance "Resistance of Special Ignitor Loop 59. Since there are many different vehicle types (e.g. truck, bus, firetruck or";
CM_ SG_ 2633832958 SpecialIgnitorLoop58Resistance "Resistance of Special Ignitor Loop 58. Since there are many different vehicle types (e.g. truck, bus, firetruck or";
CM_ SG_ 2633832958 SpecialIgnitorLoop57Resistance "Resistance of Special Ignitor Loop 57. Since there are many different vehicle types (e.g. truck, bus, firetruck or";
CM_ SG_ 2633832958 SpecialIgnitorLoop56Resistance "Resistance of Special Ignitor Loop 56. Since there are many different vehicle types (e.g. truck, bus, firetruck or";
CM_ SG_ 2633832958 SpecialIgnitorLoop55Resistance "Resistance of Special Ignitor Loop 55. Since there are many different vehicle types (e.g. truck, bus, firetruck or";
CM_ SG_ 2633832958 SpecialIgnitorLoop54Resistance "Resistance of Special Ignitor Loop 54. Since there are many different vehicle types (e.g. truck, bus, firetruck or";
CM_ SG_ 2633832958 SpecialIgnitorLoop53Resistance "Resistance of Special Ignitor Loop 53. Since there are many different vehicle types (e.g. truck, bus, firetruck or";
CM_ SG_ 2633832958 SpecialIgnitorLoop52Resistance "Resistance of Special Ignitor Loop 52. Since there are many different vehicle types (e.g. truck, bus, firetruck or";
CM_ SG_ 2633832958 SpecialIgnitorLoop51Resistance "Resistance of Special Ignitor Loop 51. Since there are many different vehicle types (e.g. truck, bus, firetruck or";
CM_ SG_ 2633832958 SpecialIgnitorLoop50Resistance "Resistance of Special Ignitor Loop 50. Since there are many different vehicle types (e.g. truck, bus, firetruck or";
CM_ SG_ 2633832958 SpecialIgnitorLoop49Resistance "Resistance of Special Ignitor Loop 49. Since there are many different vehicle types (e.g. truck, bus, firetruck or";
CM_ SG_ 2633832958 SpecialIgnitorLoop48Resistance "Resistance of Special Ignitor Loop 48. Since there are many different vehicle types (e.g. truck, bus, firetruck or";
CM_ SG_ 2633832958 SpecialIgnitorLoop47Resistance "Resistance of Special Ignitor Loop 47. Since there are many different vehicle types (e.g. truck, bus, firetruck or";
CM_ SG_ 2633832958 SpecialIgnitorLoop46Resistance "Resistance of Special Ignitor Loop 46. Since there are many different vehicle types (e.g. truck, bus, firetruck or";
CM_ SG_ 2633832958 SpecialIgnitorLoop45Resistance "Resistance of Special Ignitor Loop 45. Since there are many different vehicle types (e.g. truck, bus, firetruck or";
CM_ SG_ 2633832958 SpecialIgnitorLoop44Resistance "Resistance of Special Ignitor Loop 44. Since there are many different vehicle types (e.g. truck, bus, firetruck or";
CM_ SG_ 2633832958 SpecialIgnitorLoop43Resistance "Resistance of Special Ignitor Loop 43. Since there are many different vehicle types (e.g. truck, bus, firetruck or";
CM_ SG_ 2633832958 SpecialIgnitorLoop42Resistance "Resistance of Special Ignitor Loop 42. Since there are many different vehicle types (e.g. truck, bus, firetruck or";
CM_ SG_ 2633832958 SpecialIgnitorLoop41Resistance "Resistance of Special Ignitor Loop 41. Since there are many different vehicle types (e.g. truck, bus, firetruck or";
CM_ SG_ 2633832958 SpecialIgnitorLoop40Resistance "Resistance of Special Ignitor Loop 40. Since there are many different vehicle types (e.g. truck, bus, firetruck or";
CM_ SG_ 2633832958 SpecialIgnitorLoop39Resistance "Resistance of Special Ignitor Loop 39. Since there are many different vehicle types (e.g. truck, bus, firetruck or";
CM_ SG_ 2633832958 SpecialIgnitorLoop38Resistance "Resistance of Special Ignitor Loop 38. Since there are many different vehicle types (e.g. truck, bus, firetruck or";
CM_ SG_ 2633832958 SpecialIgnitorLoop37Resistance "Resistance of Special Ignitor Loop 37. Since there are many different vehicle types (e.g. truck, bus, firetruck or";
CM_ SG_ 2633832958 SpecialIgnitorLoop36Resistance "Resistance of Special Ignitor Loop 36. Since there are many different vehicle types (e.g. truck, bus, firetruck or";
CM_ SG_ 2633832958 SpecialIgnitorLoop35Resistance "Resistance of Special Ignitor Loop 35. Since there are many different vehicle types (e.g. truck, bus, firetruck or";
CM_ SG_ 2633832958 SpecialIgnitorLoop34Resistance "Resistance of Special Ignitor Loop 34. Since there are many different vehicle types (e.g. truck, bus, firetruck or";
CM_ SG_ 2633832958 SpecialIgnitorLoop33Resistance "Resistance of Special Ignitor Loop 33. Since there are many different vehicle types (e.g. truck, bus, firetruck or";
CM_ SG_ 2633832958 SpecialIgnitorLoop32Resistance "Resistance of Special Ignitor Loop 32. Since there are many different vehicle types (e.g. truck, bus, firetruck or";
CM_ SG_ 2633832958 SpecialIgnitorLoop31Resistance "Resistance of Special Ignitor Loop 31. Since there are many different vehicle types (e.g. truck, bus, firetruck or";
CM_ SG_ 2633832958 SpecialIgnitorLoop30Resistance "Resistance of Special Ignitor Loop 30. Since there are many different vehicle types (e.g. truck, bus, firetruck or";
CM_ SG_ 2633832958 SpecialIgnitorLoop29Resistance "Resistance of Special Ignitor Loop 29. Since there are many different vehicle types (e.g. truck, bus, firetruck or";
CM_ SG_ 2633832958 SpecialIgnitorLoop28Resistance "Resistance of Special Ignitor Loop 28. Since there are many different vehicle types (e.g. truck, bus, firetruck or";
CM_ SG_ 2633832958 SpecialIgnitorLoop27Resistance "Resistance of Special Ignitor Loop 27. Since there are many different vehicle types (e.g. truck, bus, firetruck or";
CM_ SG_ 2633832958 SpecialIgnitorLoop26Resistance "Resistance of Special Ignitor Loop 26. Since there are many different vehicle types (e.g. truck, bus, firetruck or";
CM_ SG_ 2633832958 SpecialIgnitorLoop25Resistance "Resistance of Special Ignitor Loop 25. Since there are many different vehicle types (e.g. truck, bus, firetruck or";
CM_ SG_ 2633832958 SpecialIgnitorLoop24Resistance "Resistance of Special Ignitor Loop 24. Since there are many different vehicle types (e.g. truck, bus, firetruck or";
CM_ SG_ 2633832958 SpecialIgnitorLoop23Resistance "Resistance of Special Ignitor Loop 23. Since there are many different vehicle types (e.g. truck, bus, firetruck or";
CM_ SG_ 2633832958 SpecialIgnitorLoop22Resistance "Resistance of Special Ignitor Loop 22. Since there are many different vehicle types (e.g. truck, bus, firetruck or";
CM_ SG_ 2633832958 SpecialIgnitorLoop21Resistance "Resistance of Special Ignitor Loop 21. Since there are many different vehicle types (e.g. truck, bus, firetruck or";
CM_ SG_ 2633832958 SpecialIgnitorLoop20Resistance "Resistance of Special Ignitor Loop 20. Since there are many different vehicle types (e.g. truck, bus, firetruck or";
CM_ SG_ 2633832958 SpecialIgnitorLoop19Resistance "Resistance of Special Ignitor Loop 19. Since there are many different vehicle types (e.g. truck, bus, firetruck or";
CM_ SG_ 2633832958 SpecialIgnitorLoop18Resistance "Resistance of Special Ignitor Loop 18. Since there are many different vehicle types (e.g. truck, bus, firetruck or";
CM_ SG_ 2633832958 SpecialIgnitorLoop17Resistance "Resistance of Special Ignitor Loop 17. Since there are many different vehicle types (e.g. truck, bus, firetruck or";
CM_ SG_ 2633832958 SpecialIgnitorLoop16Resistance "Resistance of Special Ignitor Loop 16. Since there are many different vehicle types (e.g. truck, bus, firetruck or";
CM_ SG_ 2633832958 SpecialIgnitorLoop15Resistance "Resistance of Special Ignitor Loop 15. Since there are many different vehicle types (e.g. truck, bus, firetruck or";
CM_ SG_ 2633832958 SpecialIgnitorLoop14Resistance "Resistance of Special Ignitor Loop 14. Since there are many different vehicle types (e.g. truck, bus, firetruck or";
CM_ SG_ 2633832958 SpecialIgnitorLoop13Resistance "Resistance of Special Ignitor Loop 13. Since there are many different vehicle types (e.g. truck, bus, firetruck or";
CM_ SG_ 2633832958 SpecialIgnitorLoop12Resistance "Resistance of Special Ignitor Loop 12. Since there are many different vehicle types (e.g. truck, bus, firetruck or";
CM_ SG_ 2633832958 SpecialIgnitorLoop11Resistance "Resistance of Special Ignitor Loop 11. Since there are many different vehicle types (e.g. truck, bus, firetruck or";
CM_ SG_ 2633832958 SpecialIgnitorLoop10Resistance "Resistance of Special Ignitor Loop 10. Since there are many different vehicle types (e.g. truck, bus, firetruck or";
CM_ SG_ 2633832958 SpecialIgnitorLoop9Resistance "Resistance of Special Ignitor Loop 9. Since there are many different vehicle types (e.g. truck, bus, firetruck or";
CM_ SG_ 2633832958 SpecialIgnitorLoop8Resistance "Resistance of Special Ignitor Loop 8. Since there are many different vehicle types (e.g. truck, bus, firetruck or";
CM_ SG_ 2633832958 SpecialIgnitorLoop7Resistance "Resistance of Special Ignitor Loop 7. Since there are many different vehicle types (e.g. truck, bus, firetruck or";
CM_ SG_ 2633832958 SpecialIgnitorLoop6Resistance "Resistance of Special Ignitor Loop 6. Since there are many different vehicle types (e.g. truck, bus, firetruck or";
CM_ SG_ 2633832958 SpecialIgnitorLoop5Resistance "Resistance of Special Ignitor Loop 5. Since there are many different vehicle types (e.g. truck, bus, firetruck or";
CM_ SG_ 2633832958 SpecialIgnitorLoop4Resistance "Resistance of Special Ignitor Loop 4. Since there are many different vehicle types (e.g. truck, bus, firetruck or";
CM_ SG_ 2633832958 SpecialIgnitorLoop3Resistance "Resistance of Special Ignitor Loop 3. Since there are many different vehicle types (e.g. truck, bus, firetruck or";
CM_ SG_ 2633832958 SpecialIgnitorLoop2Resistance "Resistance of Special Ignitor Loop 2. Since there are many different vehicle types (e.g. truck, bus, firetruck or";
CM_ SG_ 2633832958 SpecialIgnitorLoop1Resistance "Resistance of Special Ignitor Loop 1. Since there are many different vehicle types (e.g. truck, bus, firetruck or";
CM_ SG_ 2633832958 SdBagIgnitorLoop2RightResistance "Resistance of Side Bag Ignitor Loop 2 - Right.";
CM_ SG_ 2633832958 SdBagIgnitorLoop1RightResistance "Resistance of Side Bag Ignitor Loop 1 - Right.";
CM_ SG_ 2633832958 SdeBagIgnitorLoop2LeftResistance "Resistance of Side Bag Ignitor Loop 2 - Left.";
CM_ SG_ 2633832958 SdeBagIgnitorLoop1LeftResistance "Resistance of Side Bag Ignitor Loop 1 - Left.";
CM_ SG_ 2633832958 PssngrBltTnsnrIgntrLopResistance "Resistance of Passenger Belt Tensioner Ignitor Loop 1st Stage.";
CM_ SG_ 2633832958 DrvrBltTnsnrIgntorLoopResistance "Resistance of Driver Belt Tensioner Ignitor Loop 1st Stage.";
CM_ SG_ 2633832958 PssngrArbgIgntrLp2ndStgRsistance "Resistance of Passenger Airbag Ignitor Loop 2nd Stage.";
CM_ SG_ 2633832958 DrvrArbgIgntrLp2ndStgeResistance "Resistance of Driver Airbag Ignitor Loop 2nd Stage.";
CM_ SG_ 2633832958 PssngrArbgIgntrLp1stStgRsistance "Resistance of Passenger Airbag Ignitor Loop 1st Stage.";
CM_ SG_ 2633832958 DrvrArbgIgntrLp1stStgeResistance "Resistance of Driver Airbag Ignitor Loop 1st Stage.";
CM_ BO_ 2566719998 "Engine fuel consumption accumulators. See PGN 65257 for alternate resolution.";
CM_ SG_ 2566719998 HighResolutionEngTotalFuelUsed "Accumulated amount of fuel used during vehicle operation. High resolution used for calculations and fleet management";
CM_ SG_ 2566719998 HighResolutionEngTripFuel "Fuel consumed during all or part of a journey. High resolution used for calculations and fleet management systems. See";
CM_ BO_ 2565877502 "Engine Turbocharger Wastegate Actuator Control Command";
CM_ SG_ 2565877502 EngTurboWastegateActuator2Cmd "The command to a Turbocharger Wastegate actuator 2, normalized to percent, where 0% nominally represents fully";
CM_ SG_ 2565877502 EngTurboWastegateActuator1Cmd "The ccommand to a Turbocharger Wastegate actuator 1, normalized to percent, where 0% nominally represents fully";
CM_ BO_ 2566713854 "Engine Turbocharger Wastegate Actuator Information";
CM_ SG_ 2566713854 EngTrbWstgtActtr2OperationStatus "Used to identify the status of Engine Turbocharger Wastegate Actuator 2";
CM_ SG_ 2566713854 EngTrbWstgtActtr1OperationStatus "Used to identify the status of Engine Turbocharger Wastegate Actuator 1";
CM_ SG_ 2566713854 EngTrbWstgateActuator2TempStatus "Used to identify the status of the Engine Turbocharger Wastegate Actuator 2 drive circuitry temperature. Temperature";
CM_ SG_ 2566713854 EngTrbWstgtActtor2PreliminaryFMI "Used to identify the applicable J1939-73 FMI detected in the Engine Turbocharger Wastegate Actuator 2 by the";
CM_ BO_ 2566714366 "Engine Turbocharger Compressor Bypass Information";
CM_ SG_ 2566714366 EngTrbCmprssrBypssActtr2OprtnStt "Used to identify the status of Engine Turbocharger Compressor Bypass Actuator 2";
CM_ SG_ 2566714366 EngTrbCmprssrBypssActtr1OprtnStt "Used to identify the status of Engine Turbocharger Compressor Bypass Actuator 1";
CM_ SG_ 2566714366 EngTrbCmprssrBypssActtr2TmpSttus "Used to identify the status of the Engine Turbocharger Compresssor Bypass Actuator 2 drive circuitry temperature.";
CM_ SG_ 2566714366 EngTrbCmprssrBypssActtr2PrlmnryF "Used to identify the applicable J1939-73 FMI detected in the Engine Turbocharger Compressor Bypass Actuator 1 by the";
CM_ SG_ 2566714366 EngDsrdTrbCmprssrBypssActtor2Pos "The desired position of the Engine Turbocharger Compressor Bypass actuator 2 by the engine ECM, where 0%";
CM_ SG_ 2566714366 EngTrbCmprssorBypassActuator2Pos "Measures the position of the turbocharger compressor bypass actuator 2, where 0% represents bypass fully closed and";
CM_ BO_ 2566714110 "Engine Fuel/Throttle Valve Information";
CM_ SG_ 2566714110 EngFuelValve2OperationStatus "Used to identify the status of Engine Fuel Valve 2";
CM_ SG_ 2566714110 EngFuelValve1OperationStatus "Used to identify the status of Engine Fuel Valve 1";
CM_ SG_ 2566714110 EngThrottleValve2OperationStatus "Used to identify the status of Engine Throttle Valve 2";
CM_ SG_ 2566714110 EngThrottleValve1OperationStatus "Used to identify the status of Engine Throttle Valve 1";
CM_ SG_ 2566714110 EngFuelValve2TempStatus "Used to identify the status of the Engine Fuel valve 2 drive circuitry temperature. Temperature excursions may affect the";
CM_ SG_ 2566714110 EngFuelValve2PreliminaryFMI "Used to identify the applicable J1939-73 FMI detected in the Engine Fuel Valve 2 by the manufacturers software. When";
CM_ SG_ 2566714110 EngFuelValve1TempStatus "Used to identify the status of the Engine Fuel valve 1 drive circuitry temperature. Temperature excursions may affect the";
CM_ SG_ 2566714110 EngFuelValve1PreliminaryFMI "Used to identify the applicable J1939-73 FMI detected in the Engine Fuel Valve 1 by the manufacturers software. When";
CM_ SG_ 2566714110 EngThrottleValve2TempStatus "Used to identify the status of the Engine Throttle Valve 2 drive circuitry temperature. Temperature excursions may affect";
CM_ SG_ 2566714110 EngThrottleValve2PreliminaryFMI "Used to identify the applicable J1939-73 FMI detected in the Engine Throttle Valve 2 by the manufacturers software.";
CM_ SG_ 2566714110 EngDesiredThrottleValve2Pos "The desired position of the Throttle valve 2 that is regulating the fluid, usually air/fuel mixture to the engine as";
CM_ SG_ 2566714110 EngThrottleValve1TempStatus "Used to identify the status of the Engine Throttle Valve 1 drive circuitry temperature. Temperature excursions may affect";
CM_ SG_ 2566714110 EngThrottleValve1PreliminaryFMI "Used to identify the appplicable J1939-73 FMI detected in the Engine Throttle Valve 1 by the manufacturers software.";
CM_ SG_ 2566714110 EngDesiredThrottleValve1Pos "The desired position of the Throttle valve 1 that is regulating the fluid, usually air/fuel mixture to the engine as";
CM_ BO_ 2566717438 "Engine Temperature 5";
CM_ SG_ 2566717438 EngExhstGsRcrcltn2MxerIntakeTemp "The temperature of the EGR gas entering the intake of EGR2 system mixer.";
CM_ SG_ 2566717438 EngExhaustGasRecirculation2Temp "Temperature of Recirculated Exhaust Gas of EGR2";
CM_ BO_ 2633828606 "Engine oil related parameters";
CM_ SG_ 2633828606 EngOilRelativeDielectricity "Engine oil relative dielectricity used to describe the engine oil quality.";
CM_ SG_ 2633828606 EngOilDensity "Density of the engine oil";
CM_ SG_ 2633828606 EngOilViscosity "Dynamic viscosity of the engine oil";
CM_ BO_ 2499607550 "Engine manifold actuator position parameters";
CM_ SG_ 2499607550 EngExhstMnfldBnk2FlwBlncVlvActtr "Actual percentage of maximum Engine Manifold Bank 2 Balance valve opening. 0% means valve is closed. 100% means";
CM_ SG_ 2499607550 EngExhstMnfldBnk1FlwBlncVlvActtr "Actual percentage of maximum Engine Exhaust Manifold Bank 1 Balance valve opening. 0% means valve is closed.";
CM_ BO_ 2633825534 "Engine manifold actuator control parameters.";
CM_ SG_ 2633825534 EngExhstMnfldBnk2FlwBlncVlvActtr "Commanded percentage of maximum Engine Ehaust Manifold Bank 2 Balance valve opening. 0% means valve is closed.";
CM_ SG_ 2633825534 EngExhstMnfldBnk1FlwBlncVlvActtr "Commanded percentage of maximum Engine Exhaust Manifold Bank 1 Balance valve opening. 0% means valve is";
CM_ BO_ 2365400574 "Extended Joystick Message 9";
CM_ SG_ 2365400574 Jystick9GripXAxisDetentPosStatus "Reports when the current joystick grip position is in the detent position for that axis of travel.";
CM_ SG_ 2365400574 Jystick9GripYAxisDetentPosStatus "Reports when the current joystick grip position is in the detent position for that axis of travel.";
CM_ SG_ 2365400574 Jystick9ThetaAxisDetentPosStatus "Reports when the current joystick position is in the detent position for that axis of travel.";
CM_ SG_ 2365400574 Joystick9ThetaAxisPos "The position of the joystick in the relative motion of travel from the neutral position. Position value of 0 is Neutral and";
CM_ SG_ 2365400574 Jystck9ThtAxsClckwsPstvPosStatus "Reports when the current joystick position is on the positive travel side (forward, right, clockwise, up) relative to the";
CM_ SG_ 2365400574 Jystck9ThtAxsCntrClckwsNgtvPsStt "Reports when the current joystick position is on the negative travel side (back, left, counterclockwise, down) relative to the";
CM_ SG_ 2365400574 Jystck9ThetaAxisNeutralPosStatus "Reports when the current joystick position is in the neutral position for that axis of travel. The neutral position";
CM_ SG_ 2365400574 Joystick9GripYAxisPos "The position of the joystick grip in the relative motion of travel from the neutral position. Position value of 0 is Neutral and";
CM_ SG_ 2365400574 Jystck9GrpYAxsLvrFrwrdPstvPsStts "Reports when the current joystick grip position is on the positive travel side (forward, right, clockwise, up) relative to the";
CM_ SG_ 2365400574 Jystck9GrpYAxsLvrBckNgtvPsStatus "Reports when the current joystick grip position is on the negative travel side (back, left, counterclockwise, down) relative";
CM_ SG_ 2365400574 Jystck9GripYAxisNeutralPosStatus "Reports when the current joystick grip position is in the neutral position for that axis of travel. The neutral position";
CM_ SG_ 2365400574 Joystick9GripXAxisPos "The position of the joystick grip in the relative motion of travel from the neutral position. Position value of 0 is Neutral and";
CM_ SG_ 2365400574 Jystck9GrpXAxsLvrRghtPstvPsSttus "Reports when the current joystick grip position is on the positive travel side (forward, right, clockwise, up) relative to the";
CM_ SG_ 2365400574 Jystck9GrpXAxsLvrLftNgtvPsStatus "Reports when the current joystick grip position is on the negative travel side (back, left, counterclockwise, down) relative";
CM_ SG_ 2365400574 Jystck9GripXAxisNeutralPosStatus "Reports when the current joystick grip position is in the neutral position for that axis of travel. The neutral position";
CM_ BO_ 2365401086 "Extended Joystick Message 8";
CM_ SG_ 2365401086 Jystick8GripXAxisDetentPosStatus "Reports when the current joystick grip position is in the detent position for that axis of travel.";
CM_ SG_ 2365401086 Jystick8GripYAxisDetentPosStatus "Reports when the current joystick grip position is in the detent position for that axis of travel.";
CM_ SG_ 2365401086 Jystick8ThetaAxisDetentPosStatus "Reports when the current joystick position is in the detent position for that axis of travel.";
CM_ SG_ 2365401086 Joystick8ThetaAxisPos "The position of the joystick in the relative motion of travel from the neutral position. Position value of 0 is Neutral and";
CM_ SG_ 2365401086 Jystck8ThtAxsClckwsPstvPosStatus "Reports when the current joystick position is on the positive travel side (forward, right, clockwise, up) relative to the";
CM_ SG_ 2365401086 Jystck8ThtAxsCntrClckwsNgtvPsStt "Reports when the current joystick position is on the negative travel side (back, left, counterclockwise, down) relative to the";
CM_ SG_ 2365401086 Jystck8ThetaAxisNeutralPosStatus "Reports when the current joystick position is in the neutral position for that axis of travel. The neutral position";
CM_ SG_ 2365401086 Joystick8GripYAxisPos "The position of the joystick grip in the relative motion of travel from the neutral position. Position value of 0 is Neutral and";
CM_ SG_ 2365401086 Jystck8GrpYAxsLvrFrwrdPstvPsStts "Reports when the current joystick grip position is on the positive travel side (forward, right, clockwise, up) relative to the";
CM_ SG_ 2365401086 Jystck8GrpYAxsLvrBckNgtvPsStatus "Reports when the current joystick grip position is on the negative travel side (back, left, counterclockwise, down) relative";
CM_ SG_ 2365401086 Jystck8GripYAxisNeutralPosStatus "Reports when the current joystick grip position is in the neutral position for that axis of travel. The neutral position";
CM_ SG_ 2365401086 Joystick8GripXAxisPos "The position of the joystick grip in the relative motion of travel from the neutral position. Position value of 0 is Neutral and";
CM_ SG_ 2365401086 Jystck8GrpXAxsLvrRghtPstvPsSttus "Reports when the current joystick grip position is on the positive travel side (forward, right, clockwise, up) relative to the";
CM_ SG_ 2365401086 Jystck8GrpXAxsLvrLftNgtvPsStatus "Reports when the current joystick grip position is on the negative travel side (back, left, counterclockwise, down) relative";
CM_ SG_ 2365401086 Jystck8GripXAxisNeutralPosStatus "Reports when the current joystick grip position is in the neutral position for that axis of travel. The neutral position";
CM_ BO_ 2365401598 "Extended Joystick Message 7";
CM_ SG_ 2365401598 Jystick7GripXAxisDetentPosStatus "Reports when the current joystick grip position is in the detent position for that axis of travel.";
CM_ SG_ 2365401598 Jystick7GripYAxisDetentPosStatus "Reports when the current joystick grip position is in the detent position for that axis of travel.";
CM_ SG_ 2365401598 Jystick7ThetaAxisDetentPosStatus "Reports when the current joystick position is in the detent position for that axis of travel.";
CM_ SG_ 2365401598 Joystick7ThetaAxisPos "The position of the joystick in the relative motion of travel from the neutral position. Position value of 0 is Neutral and";
CM_ SG_ 2365401598 Jystck7ThtAxsClckwsPstvPosStatus "Reports when the current joystick position is on the positive travel side (forward, right, clockwise, up) relative to the";
CM_ SG_ 2365401598 Jystck7ThtAxsCntrClckwsNgtvPsStt "Reports when the current joystick position is on the negative travel side (back, left, counterclockwise, down) relative to the";
CM_ SG_ 2365401598 Jystck7ThetaAxisNeutralPosStatus "Reports when the current joystick position is in the neutral position for that axis of travel. The neutral position";
CM_ SG_ 2365401598 Joystick7GripYAxisPos "The position of the joystick grip in the relative motion of travel from the neutral position. Position value of 0 is Neutral and";
CM_ SG_ 2365401598 Jystck7GrpYAxsLvrFrwrdPstvPsStts "Reports when the current joystick grip position is on the positive travel side (forward, right, clockwise, up) relative to the";
CM_ SG_ 2365401598 Jystck7GrpYAxsLvrBckNgtvPsStatus "Reports when the current joystick grip position is on the negative travel side (back, left, counterclockwise, down) relative";
CM_ SG_ 2365401598 Jystck7GripYAxisNeutralPosStatus "Reports when the current joystick grip position is in the neutral position for that axis of travel. The neutral position";
CM_ SG_ 2365401598 Joystick7GripXAxisPos "The position of the joystick grip in the relative motion of travel from the neutral position. Position value of 0 is Neutral and";
CM_ SG_ 2365401598 Jystck7GrpXAxsLvrRghtPstvPsSttus "Reports when the current joystick grip position is on the positive travel side (forward, right, clockwise, up) relative to the";
CM_ SG_ 2365401598 Jystck7GrpXAxsLvrLftNgtvPsStatus "Reports when the current joystick grip position is on the negative travel side (back, left, counterclockwise, down) relative";
CM_ SG_ 2365401598 Jystck7GripXAxisNeutralPosStatus "Reports when the current joystick grip position is in the neutral position for that axis of travel. The neutral position";
CM_ BO_ 2365402110 "Extended Joystick Message 6";
CM_ SG_ 2365402110 Jystick6GripXAxisDetentPosStatus "Reports when the current joystick grip position is in the detent position for that axis of travel.";
CM_ SG_ 2365402110 Jystick6GripYAxisDetentPosStatus "Reports when the current joystick grip position is in the detent position for that axis of travel.";
CM_ SG_ 2365402110 Jystick6ThetaAxisDetentPosStatus "Reports when the current joystick position is in the detent position for that axis of travel.";
CM_ SG_ 2365402110 Joystick6ThetaAxisPos "The position of the joystick in the relative motion of travel from the neutral position. Position value of 0 is Neutral and";
CM_ SG_ 2365402110 Jystck6ThtAxsClckwsPstvPosStatus "Reports when the current joystick position is on the positive travel side (forward, right, clockwise, up) relative to the";
CM_ SG_ 2365402110 Jystck6ThtAxsCntrClckwsNgtvPsStt "Reports when the current joystick position is on the negative travel side (back, left, counterclockwise, down) relative to the";
CM_ SG_ 2365402110 Jystck6ThetaAxisNeutralPosStatus "Reports when the current joystick position is in the neutral position for that axis of travel. The neutral position";
CM_ SG_ 2365402110 Joystick6GripYAxisPos "The position of the joystick grip in the relative motion of travel from the neutral position. Position value of 0 is Neutral and";
CM_ SG_ 2365402110 Jystck6GrpYAxsLvrFrwrdPstvPsStts "Reports when the current joystick grip position is on the positive travel side (forward, right, clockwise, up) relative to the";
CM_ SG_ 2365402110 Jystck6GrpYAxsLvrBckNgtvPsStatus "Reports when the current joystick grip position is on the negative travel side (back, left, counterclockwise, down) relative";
CM_ SG_ 2365402110 Jystck6GripYAxisNeutralPosStatus "Reports when the current joystick grip position is in the neutral position for that axis of travel. The neutral position";
CM_ SG_ 2365402110 Joystick6GripXAxisPos "The position of the joystick grip in the relative motion of travel from the neutral position. Position value of 0 is Neutral and";
CM_ SG_ 2365402110 Jystck6GrpXAxsLvrRghtPstvPsSttus "Reports when the current joystick grip position is on the positive travel side (forward, right, clockwise, up) relative to the";
CM_ SG_ 2365402110 Jystck6GrpXAxsLvrLftNgtvPsStatus "Reports when the current joystick grip position is on the negative travel side (back, left, counterclockwise, down) relative";
CM_ SG_ 2365402110 Jystck6GripXAxisNeutralPosStatus "Reports when the current joystick grip position is in the neutral position for that axis of travel. The neutral position";
BA_DEF_ SG_  "SigType" ENUM  "Default","Range","RangeSigned","ASCII","Discrete","Control","ReferencePGN","DTC","StringDelimiter","StringLength","StringLengthControl";
BA_DEF_ SG_  "GenSigStartValue" INT 0 10000;
BA_DEF_ SG_  "GenSigSendType" ENUM  "Cyclic","OnWrite","reserved","OnChange","reserved","reserved","reserved","NoSigSendType";
BA_DEF_ SG_  "GenSigILSupport" ENUM  "Yes","No";
BA_DEF_ SG_  "GenSigEVName" STRING ;
BA_DEF_ SG_  "SPN" INT 0 524287;
BA_DEF_ SG_  "SAEDocument" STRING ;
BA_DEF_ BO_  "GenMsgStartDelayTime" INT 0 100000;
BA_DEF_ BO_  "GenMsgILSupport" ENUM  "Yes","No";
BA_DEF_ BO_  "GenMsgRequestable" INT 0 1;
BA_DEF_ BO_  "GenMsgSendType" ENUM  "cyclic","reserved","cyclicIfActive","reserved","reserved","reserved","reserved","reserved","noMsgSendType";
BA_DEF_ BO_  "VFrameFormat" ENUM  "StandardCAN","ExtendedCAN","reserved","J1939PG";
BA_DEF_ BO_  "SingleFrame" INT 0 1;
BA_DEF_ BO_  "GenMsgCycleTime" INT 0 3600000;
BA_DEF_ BO_  "SAE_Document" STRING ;
BA_DEF_ BU_  "NmStationAddress" INT 0 255;
BA_DEF_ BU_  "NmJ1939IndustryGroup" INT 0 7;
BA_DEF_ BU_  "NmJ1939System" INT 0 127;
BA_DEF_ BU_  "NmJ1939Function" INT 0 255;
BA_DEF_ BU_  "NmJ1939FunctionInstance" INT 0 7;
BA_DEF_ BU_  "NmJ1939ECUInstance" INT 0 3;
BA_DEF_  "DatabaseVersion" STRING ;
BA_DEF_  "BusType" STRING ;
BA_DEF_  "ProtocolType" STRING ;
BA_DEF_  "SAE_J1939_75_SpecVersion" STRING ;
BA_DEF_  "SAE_J1939_21_SpecVersion" STRING ;
BA_DEF_  "SAE_J1939_73_SpecVersion" STRING ;
BA_DEF_  "SAE_J1939_71_SpecVersion" STRING ;
BA_DEF_ SG_  "SystemSignalLongSymbol" STRING ;
BA_DEF_DEF_  "SigType" "Default";
BA_DEF_DEF_  "GenSigStartValue" 0;
BA_DEF_DEF_  "GenSigSendType" "NoSigSendType";
BA_DEF_DEF_  "GenSigILSupport" "Yes";
BA_DEF_DEF_  "GenSigEVName" "Env@Nodename_@Signame";
BA_DEF_DEF_  "SPN" 0;
BA_DEF_DEF_  "SAEDocument" "";
BA_DEF_DEF_  "GenMsgStartDelayTime" 0;
BA_DEF_DEF_  "GenMsgILSupport" "Yes";
BA_DEF_DEF_  "GenMsgRequestable" 1;
BA_DEF_DEF_  "GenMsgSendType" "noMsgSendType";
BA_DEF_DEF_  "VFrameFormat" "J1939PG";
BA_DEF_DEF_  "SingleFrame" 1;
BA_DEF_DEF_  "GenMsgCycleTime" 0;
BA_DEF_DEF_  "SAE_Document" "";
BA_DEF_DEF_  "NmStationAddress" 254;
BA_DEF_DEF_  "NmJ1939IndustryGroup" 0;
BA_DEF_DEF_  "NmJ1939System" 0;
BA_DEF_DEF_  "NmJ1939Function" 0;
BA_DEF_DEF_  "NmJ1939FunctionInstance" 0;
BA_DEF_DEF_  "NmJ1939ECUInstance" 0;
BA_DEF_DEF_  "DatabaseVersion" "";
BA_DEF_DEF_  "BusType" "";
BA_DEF_DEF_  "ProtocolType" "";
BA_DEF_DEF_  "SAE_J1939_75_SpecVersion" "";
BA_DEF_DEF_  "SAE_J1939_21_SpecVersion" "";
BA_DEF_DEF_  "SAE_J1939_73_SpecVersion" "";
BA_DEF_DEF_  "SAE_J1939_71_SpecVersion" "";
BA_DEF_DEF_  "SystemSignalLongSymbol" "";
BA_ "DatabaseVersion" "7.5";
BA_ "BusType" "CAN";
BA_ "ProtocolType" "J1939";
BA_ "SAE_J1939_75_SpecVersion" "2005-10";
BA_ "SAE_J1939_21_SpecVersion" "2006-10";
BA_ "SAE_J1939_73_SpecVersion" "2010-10";
BA_ "SAE_J1939_71_SpecVersion" "2010-10";
BA_ "NmStationAddress" BU_ Turbocharger 2;
BA_ "NmJ1939Function" BU_ Turbocharger 133;
BA_ "NmStationAddress" BU_ OnBoardDataLogger 251;
BA_ "NmJ1939Function" BU_ OnBoardDataLogger 130;
BA_ "NmStationAddress" BU_ OffBoardDiagnosticTool2 250;
BA_ "NmJ1939Function" BU_ OffBoardDiagnosticTool2 129;
BA_ "NmJ1939FunctionInstance" BU_ OffBoardDiagnosticTool2 1;
BA_ "NmStationAddress" BU_ OffBoardDiagnosticTool1 249;
BA_ "NmJ1939Function" BU_ OffBoardDiagnosticTool1 129;
BA_ "NmStationAddress" BU_ FileServer 248;
BA_ "NmJ1939Function" BU_ FileServer 61;
BA_ "NmStationAddress" BU_ ParkingBrakeController 80;
BA_ "NmJ1939Function" BU_ ParkingBrakeController 9;
BA_ "NmStationAddress" BU_ SeatControl2 79;
BA_ "NmJ1939Function" BU_ SeatControl2 40;
BA_ "NmStationAddress" BU_ FanDriveController 78;
BA_ "NmJ1939Function" BU_ FanDriveController 58;
BA_ "NmStationAddress" BU_ SteeringColumnUnit 77;
BA_ "NmJ1939Function" BU_ SteeringColumnUnit 57;
BA_ "NmStationAddress" BU_ CommunicationUnitRadio 76;
BA_ "NmJ1939Function" BU_ CommunicationUnitRadio 56;
BA_ "NmStationAddress" BU_ CommunicationUnitSatellite 75;
BA_ "NmJ1939Function" BU_ CommunicationUnitSatellite 55;
BA_ "NmStationAddress" BU_ CommunicationUnitCellular 74;
BA_ "NmJ1939Function" BU_ CommunicationUnitCellular 54;
BA_ "NmStationAddress" BU_ PropulsionBatteryCharger 73;
BA_ "NmJ1939Function" BU_ PropulsionBatteryCharger 31;
BA_ "NmStationAddress" BU_ ChassisController2 72;
BA_ "NmJ1939Function" BU_ ChassisController2 52;
BA_ "NmJ1939FunctionInstance" BU_ ChassisController2 1;
BA_ "NmStationAddress" BU_ ChassisController1 71;
BA_ "NmJ1939Function" BU_ ChassisController1 52;
BA_ "NmStationAddress" BU_ EngineValveControl 70;
BA_ "NmJ1939Function" BU_ EngineValveControl 63;
BA_ "NmStationAddress" BU_ AuxiliaryHeater2 69;
BA_ "NmJ1939Function" BU_ AuxiliaryHeater2 50;
BA_ "NmJ1939FunctionInstance" BU_ AuxiliaryHeater2 1;
BA_ "NmStationAddress" BU_ AuxiliaryHeater1 68;
BA_ "NmJ1939Function" BU_ AuxiliaryHeater1 50;
BA_ "NmStationAddress" BU_ ClutchUnit 67;
BA_ "NmJ1939Function" BU_ ClutchUnit 49;
BA_ "NmStationAddress" BU_ RampControl 66;
BA_ "NmJ1939Function" BU_ RampControl 48;
BA_ "NmStationAddress" BU_ InformationSystem1 65;
BA_ "NmJ1939Function" BU_ InformationSystem1 47;
BA_ "NmStationAddress" BU_ SuspensionSystemController2 64;
BA_ "NmJ1939Function" BU_ SuspensionSystemController2 35;
BA_ "NmStationAddress" BU_ OilSensor 63;
BA_ "NmJ1939Function" BU_ OilSensor 46;
BA_ "NmStationAddress" BU_ VehicleDynamicStability 62;
BA_ "NmJ1939Function" BU_ VehicleDynamicStability 45;
BA_ "NmStationAddress" BU_ ExhaustEmissionController 61;
BA_ "NmJ1939Function" BU_ ExhaustEmissionController 44;
BA_ "NmStationAddress" BU_ TransmissionDisplay2 60;
BA_ "NmJ1939Function" BU_ TransmissionDisplay2 43;
BA_ "NmStationAddress" BU_ TransmissionDisplay1 59;
BA_ "NmJ1939Function" BU_ TransmissionDisplay1 43;
BA_ "NmStationAddress" BU_ ClimateControl2 58;
BA_ "NmJ1939Function" BU_ ClimateControl2 21;
BA_ "NmStationAddress" BU_ WaterPumpController 57;
BA_ "NmJ1939Function" BU_ WaterPumpController 42;
BA_ "NmStationAddress" BU_ RearAxleSteeringController 56;
BA_ "NmJ1939System" BU_ RearAxleSteeringController 127;
BA_ "NmJ1939Function" BU_ RearAxleSteeringController 255;
BA_ "NmStationAddress" BU_ LightingOperatorControl 55;
BA_ "NmJ1939Function" BU_ LightingOperatorControl 41;
BA_ "NmStationAddress" BU_ SeatController1 54;
BA_ "NmJ1939Function" BU_ SeatController1 40;
BA_ "NmStationAddress" BU_ IgnitionController2 53;
BA_ "NmJ1939Function" BU_ IgnitionController2 39;
BA_ "NmJ1939FunctionInstance" BU_ IgnitionController2 1;
BA_ "NmStationAddress" BU_ IgnitionController1 52;
BA_ "NmJ1939Function" BU_ IgnitionController1 39;
BA_ "NmStationAddress" BU_ TirePressureController 51;
BA_ "NmJ1939Function" BU_ TirePressureController 38;
BA_ "NmStationAddress" BU_ CabController2 50;
BA_ "NmJ1939Function" BU_ CabController2 37;
BA_ "NmStationAddress" BU_ CabController1 49;
BA_ "NmJ1939Function" BU_ CabController1 37;
BA_ "NmStationAddress" BU_ PneumaticSystemController 48;
BA_ "NmJ1939Function" BU_ PneumaticSystemController 36;
BA_ "NmStationAddress" BU_ SuspensionSystemController1 47;
BA_ "NmJ1939Function" BU_ SuspensionSystemController1 35;
BA_ "NmStationAddress" BU_ HydraulicPumpController 46;
BA_ "NmJ1939Function" BU_ HydraulicPumpController 34;
BA_ "NmStationAddress" BU_ EnduranceBrakingSystem 45;
BA_ "NmJ1939Function" BU_ EnduranceBrakingSystem 64;
BA_ "NmStationAddress" BU_ RetarderExhaustEngine2 44;
BA_ "NmJ1939Function" BU_ RetarderExhaustEngine2 12;
BA_ "NmJ1939FunctionInstance" BU_ RetarderExhaustEngine2 1;
BA_ "NmStationAddress" BU_ OnBoardDiagnosticUnit 43;
BA_ "NmJ1939Function" BU_ OnBoardDiagnosticUnit 62;
BA_ "NmStationAddress" BU_ HeadwayController 42;
BA_ "NmJ1939Function" BU_ HeadwayController 32;
BA_ "NmStationAddress" BU_ RetarderExhaustEngine1 41;
BA_ "NmJ1939Function" BU_ RetarderExhaustEngine1 12;
BA_ "NmStationAddress" BU_ CabDisplay1 40;
BA_ "NmJ1939Function" BU_ CabDisplay1 60;
BA_ "NmStationAddress" BU_ ManagementComputer 39;
BA_ "NmJ1939Function" BU_ ManagementComputer 30;
BA_ "NmStationAddress" BU_ VirtualTerminal 38;
BA_ "NmJ1939Function" BU_ VirtualTerminal 29;
BA_ "NmStationAddress" BU_ OffVehicleGateway 37;
BA_ "NmJ1939Function" BU_ OffVehicleGateway 28;
BA_ "NmStationAddress" BU_ PowerTakeOffFront 36;
BA_ "NmJ1939Function" BU_ PowerTakeOffFront 27;
BA_ "NmStationAddress" BU_ HitchControl 35;
BA_ "NmJ1939System" BU_ HitchControl 127;
BA_ "NmJ1939Function" BU_ HitchControl 255;
BA_ "NmStationAddress" BU_ AuxiliaryValveControl 34;
BA_ "NmJ1939IndustryGroup" BU_ AuxiliaryValveControl 2;
BA_ "NmJ1939System" BU_ AuxiliaryValveControl 1;
BA_ "NmJ1939Function" BU_ AuxiliaryValveControl 129;
BA_ "NmStationAddress" BU_ BodyController 33;
BA_ "NmJ1939Function" BU_ BodyController 26;
BA_ "NmStationAddress" BU_ TractorTrailerBridge1 32;
BA_ "NmJ1939System" BU_ TractorTrailerBridge1 127;
BA_ "NmJ1939Function" BU_ TractorTrailerBridge1 255;
BA_ "NmStationAddress" BU_ StarterSystem 31;
BA_ "NmJ1939Function" BU_ StarterSystem 59;
BA_ "NmStationAddress" BU_ ElectricalSystem 30;
BA_ "NmJ1939Function" BU_ ElectricalSystem 67;
BA_ "NmStationAddress" BU_ VehicleSecurity 29;
BA_ "NmJ1939Function" BU_ VehicleSecurity 24;
BA_ "NmStationAddress" BU_ VehicleNavigation 28;
BA_ "NmJ1939Function" BU_ VehicleNavigation 23;
BA_ "NmStationAddress" BU_ AerodynamicControl 27;
BA_ "NmJ1939Function" BU_ AerodynamicControl 22;
BA_ "NmStationAddress" BU_ ElectricalChargingSystem 26;
BA_ "NmJ1939Function" BU_ ElectricalChargingSystem 53;
BA_ "NmStationAddress" BU_ ClimateControl1 25;
BA_ "NmJ1939Function" BU_ ClimateControl1 21;
BA_ "NmStationAddress" BU_ TripRecorder 24;
BA_ "NmJ1939Function" BU_ TripRecorder 20;
BA_ "NmStationAddress" BU_ InstrumentCluster 23;
BA_ "NmJ1939Function" BU_ InstrumentCluster 19;
BA_ "NmStationAddress" BU_ SuspensionDriveAxle2 22;
BA_ "NmJ1939Function" BU_ SuspensionDriveAxle2 18;
BA_ "NmJ1939FunctionInstance" BU_ SuspensionDriveAxle2 1;
BA_ "NmStationAddress" BU_ SuspensionDriveAxle1 21;
BA_ "NmJ1939Function" BU_ SuspensionDriveAxle1 18;
BA_ "NmStationAddress" BU_ SuspensionSteerAxle 20;
BA_ "NmJ1939Function" BU_ SuspensionSteerAxle 17;
BA_ "NmStationAddress" BU_ SteeringController 19;
BA_ "NmJ1939Function" BU_ SteeringController 16;
BA_ "NmStationAddress" BU_ FuelSystem 18;
BA_ "NmJ1939Function" BU_ FuelSystem 15;
BA_ "NmStationAddress" BU_ CruiseControl 17;
BA_ "NmJ1939Function" BU_ CruiseControl 14;
BA_ "NmStationAddress" BU_ RetarderDriveline 16;
BA_ "NmJ1939Function" BU_ RetarderDriveline 13;
BA_ "NmStationAddress" BU_ RetarderEngine 15;
BA_ "NmJ1939Function" BU_ RetarderEngine 12;
BA_ "NmStationAddress" BU_ BrakesDriveAxle2 14;
BA_ "NmJ1939Function" BU_ BrakesDriveAxle2 11;
BA_ "NmJ1939FunctionInstance" BU_ BrakesDriveAxle2 1;
BA_ "NmStationAddress" BU_ BrakesDriveAxle1 13;
BA_ "NmJ1939Function" BU_ BrakesDriveAxle1 11;
BA_ "NmStationAddress" BU_ BrakesSystemController 11;
BA_ "NmJ1939Function" BU_ BrakesSystemController 9;
BA_ "NmStationAddress" BU_ BrakesSteerAxle 12;
BA_ "NmJ1939Function" BU_ BrakesSteerAxle 10;
BA_ "NmStationAddress" BU_ AxleDrive2 10;
BA_ "NmJ1939Function" BU_ AxleDrive2 8;
BA_ "NmJ1939FunctionInstance" BU_ AxleDrive2 1;
BA_ "NmStationAddress" BU_ AxleDrive1 9;
BA_ "NmJ1939Function" BU_ AxleDrive1 8;
BA_ "NmStationAddress" BU_ AxleSteering 8;
BA_ "NmJ1939Function" BU_ AxleSteering 7;
BA_ "NmStationAddress" BU_ PowerTakeOff 7;
BA_ "NmJ1939Function" BU_ PowerTakeOff 6;
BA_ "NmStationAddress" BU_ ShiftConsoleSecondary 6;
BA_ "NmJ1939Function" BU_ ShiftConsoleSecondary 5;
BA_ "NmJ1939FunctionInstance" BU_ ShiftConsoleSecondary 1;
BA_ "NmStationAddress" BU_ ShiftConsolePrimary 5;
BA_ "NmJ1939Function" BU_ ShiftConsolePrimary 5;
BA_ "NmStationAddress" BU_ Transmission2 4;
BA_ "NmJ1939Function" BU_ Transmission2 3;
BA_ "NmJ1939ECUInstance" BU_ Transmission2 1;
BA_ "NmStationAddress" BU_ Transmission1 3;
BA_ "NmJ1939Function" BU_ Transmission1 3;
BA_ "NmStationAddress" BU_ Engine2 1;
BA_ "NmJ1939FunctionInstance" BU_ Engine2 1;
BA_ "NmStationAddress" BU_ Engine1 0;
BA_ "SAE_Document" BO_ 2148676695 "J1939-71";
BA_ "GenMsgCycleTime" BO_ 2148676695 20;
BA_ "GenMsgSendType" BO_ 2148676695 0;
BA_ "SAE_Document" BO_ 2148676694 "J1939-71";
BA_ "GenMsgCycleTime" BO_ 2148676694 500;
BA_ "GenMsgSendType" BO_ 2148676694 0;
BA_ "GenMsgSendType" BO_ 2297441790 0;
BA_ "GenMsgCycleTime" BO_ 2297441790 10;
BA_ "SAE_Document" BO_ 2297441790 "J1939-71";
BA_ "SAE_Document" BO_ 2566712062 "J1939-71";
BA_ "GenMsgSendType" BO_ 2364549630 0;
BA_ "GenMsgCycleTime" BO_ 2364549630 10;
BA_ "SAE_Document" BO_ 2364549630 "J1939-71";
BA_ "GenMsgSendType" BO_ 2499614462 0;
BA_ "GenMsgCycleTime" BO_ 2499614462 5000;
BA_ "SAE_Document" BO_ 2499614462 "J1939-71";
BA_ "GenMsgSendType" BO_ 2560098046 0;
BA_ "GenMsgCycleTime" BO_ 2560098046 10000;
BA_ "SAE_Document" BO_ 2560098046 "J1939-71";
BA_ "GenMsgSendType" BO_ 2560163582 0;
BA_ "GenMsgCycleTime" BO_ 2560163582 10000;
BA_ "SAE_Document" BO_ 2560163582 "J1939-71";
BA_ "GenMsgSendType" BO_ 2297441534 0;
BA_ "GenMsgCycleTime" BO_ 2297441534 50;
BA_ "SAE_Document" BO_ 2297441534 "J1939-71";
BA_ "GenMsgSendType" BO_ 2566722302 0;
BA_ "GenMsgCycleTime" BO_ 2566722302 500;
BA_ "SAE_Document" BO_ 2566722302 "J1939-71";
BA_ "SAE_Document" BO_ 2566722558 "J1939-71";
BA_ "GenMsgSendType" BO_ 2560032510 0;
BA_ "GenMsgCycleTime" BO_ 2560032510 500;
BA_ "SAE_Document" BO_ 2560032510 "J1939-71";
BA_ "GenMsgSendType" BO_ 2566717950 0;
BA_ "GenMsgCycleTime" BO_ 2566717950 500;
BA_ "SAE_Document" BO_ 2566717950 "J1939-71";
BA_ "GenMsgSendType" BO_ 2499604222 0;
BA_ "GenMsgCycleTime" BO_ 2499604222 200;
BA_ "SAE_Document" BO_ 2499604222 "J1939-71";
BA_ "GenMsgSendType" BO_ 2358902526 0;
BA_ "GenMsgCycleTime" BO_ 2358902526 100;
BA_ "SAE_Document" BO_ 2358902526 "J1939-71";
BA_ "GenMsgSendType" BO_ 2566711550 0;
BA_ "GenMsgCycleTime" BO_ 2566711550 500;
BA_ "SAE_Document" BO_ 2566711550 "J1939-71";
BA_ "SAE_Document" BO_ 2633832958 "J1939-71";
BA_ "GenMsgSendType" BO_ 2566719998 0;
BA_ "GenMsgCycleTime" BO_ 2566719998 1000;
BA_ "SAE_Document" BO_ 2566719998 "J1939-71";
BA_ "SAE_Document" BO_ 2565877502 "J1939-71";
BA_ "GenMsgSendType" BO_ 2566713854 0;
BA_ "GenMsgCycleTime" BO_ 2566713854 100;
BA_ "SAE_Document" BO_ 2566713854 "J1939-71";
BA_ "GenMsgSendType" BO_ 2566714366 0;
BA_ "GenMsgCycleTime" BO_ 2566714366 100;
BA_ "SAE_Document" BO_ 2566714366 "J1939-71";
BA_ "GenMsgSendType" BO_ 2566714110 0;
BA_ "GenMsgCycleTime" BO_ 2566714110 100;
BA_ "SAE_Document" BO_ 2566714110 "J1939-71";
BA_ "GenMsgSendType" BO_ 2566717438 0;
BA_ "GenMsgCycleTime" BO_ 2566717438 1000;
BA_ "SAE_Document" BO_ 2566717438 "J1939-71";
BA_ "GenMsgSendType" BO_ 2633828606 0;
BA_ "GenMsgCycleTime" BO_ 2633828606 30000;
BA_ "SAE_Document" BO_ 2633828606 "J1939-71";
BA_ "SAE_Document" BO_ 2499607550 "J1939-71";
BA_ "SAE_Document" BO_ 2633825534 "J1939-71";
BA_ "SAE_Document" BO_ 2365400574 "J1939-71";
BA_ "SAE_Document" BO_ 2365401086 "J1939-71";
BA_ "SAE_Document" BO_ 2365401598 "J1939-71";
BA_ "SAE_Document" BO_ 2365402110 "J1939-71";
BA_ "SigType" SG_ 3221225472 TrailerWeight 1;
BA_ "SPN" SG_ 3221225472 TrailerWeight 180;
BA_ "SAEDocument" SG_ 3221225472 TrailerWeight "J1939-71";
BA_ "SPN" SG_ 3221225472 ReferenceTirePressSetting 3193;
BA_ "SAEDocument" SG_ 3221225472 ReferenceTirePressSetting "J1939-71";
BA_ "SPN" SG_ 3221225472 ReferenceTirePress 3191;
BA_ "SAEDocument" SG_ 3221225472 ReferenceTirePress "J1939-71";
BA_ "SPN" SG_ 3221225472 TirePressThresholdDetection 2587;
BA_ "SAEDocument" SG_ 3221225472 TirePressThresholdDetection "J1939-71";
BA_ "SigType" SG_ 3221225472 TireAirLeakageRate 1;
BA_ "SPN" SG_ 3221225472 TireAirLeakageRate 2586;
BA_ "SAEDocument" SG_ 3221225472 TireAirLeakageRate "J1939-71";
BA_ "SigType" SG_ 3221225472 CTIWheelEndElectricalFault 4;
BA_ "SPN" SG_ 3221225472 CTIWheelEndElectricalFault 1697;
BA_ "SAEDocument" SG_ 3221225472 CTIWheelEndElectricalFault "J1939-71";
BA_ "SigType" SG_ 3221225472 CTITireStatus 4;
BA_ "SPN" SG_ 3221225472 CTITireStatus 1698;
BA_ "SAEDocument" SG_ 3221225472 CTITireStatus "J1939-71";
BA_ "SigType" SG_ 3221225472 CTIWheelSensorStatus 4;
BA_ "SPN" SG_ 3221225472 CTIWheelSensorStatus 1699;
BA_ "SAEDocument" SG_ 3221225472 CTIWheelSensorStatus "J1939-71";
BA_ "SigType" SG_ 3221225472 TireTemp 1;
BA_ "SPN" SG_ 3221225472 TireTemp 242;
BA_ "SAEDocument" SG_ 3221225472 TireTemp "J1939-71";
BA_ "SigType" SG_ 3221225472 TirePress 1;
BA_ "SPN" SG_ 3221225472 TirePress 241;
BA_ "SAEDocument" SG_ 3221225472 TirePress "J1939-71";
BA_ "SigType" SG_ 3221225472 EngTurningGearEngaged 4;
BA_ "SPN" SG_ 3221225472 EngTurningGearEngaged 1206;
BA_ "SAEDocument" SG_ 3221225472 EngTurningGearEngaged "J1939-71";
BA_ "SigType" SG_ 2632975265 PSWErrDriveChip 1;
BA_ "SPN" SG_ 2632975265 PSWErrDriveChip 91;
BA_ "SAEDocument" SG_ 2632975265 PSWErrDriveChip "J1939-71";
BA_ "SigType" SG_ 2632975265 PSWErrShortDrive724_U19 1;
BA_ "SPN" SG_ 2632975265 PSWErrShortDrive724_U19 91;
BA_ "SAEDocument" SG_ 2632975265 PSWErrShortDrive724_U19 "J1939-71";
BA_ "SigType" SG_ 2632975265 PSWErrOpenDrive724_U19 1;
BA_ "SPN" SG_ 2632975265 PSWErrOpenDrive724_U19 91;
BA_ "SAEDocument" SG_ 2632975265 PSWErrOpenDrive724_U19 "J1939-71";
BA_ "SigType" SG_ 2632975264 PSWErrShortDrive724_U9 1;
BA_ "SPN" SG_ 2632975264 PSWErrShortDrive724_U9 91;
BA_ "SAEDocument" SG_ 2632975264 PSWErrShortDrive724_U9 "J1939-71";
BA_ "SigType" SG_ 2632975264 PSWErrShortDrive724_U6 1;
BA_ "SPN" SG_ 2632975264 PSWErrShortDrive724_U6 91;
BA_ "SAEDocument" SG_ 2632975264 PSWErrShortDrive724_U6 "J1939-71";
BA_ "SigType" SG_ 2632975264 PSWErrShortDrive724_U13 1;
BA_ "SPN" SG_ 2632975264 PSWErrShortDrive724_U13 91;
BA_ "SAEDocument" SG_ 2632975264 PSWErrShortDrive724_U13 "J1939-71";
BA_ "SigType" SG_ 2632975264 PSWErrShortDrive724_U12 1;
BA_ "SPN" SG_ 2632975264 PSWErrShortDrive724_U12 91;
BA_ "SAEDocument" SG_ 2632975264 PSWErrShortDrive724_U12 "J1939-71";
BA_ "SigType" SG_ 2632975264 PSWErrOpenDrive724_U9 1;
BA_ "SPN" SG_ 2632975264 PSWErrOpenDrive724_U9 91;
BA_ "SAEDocument" SG_ 2632975264 PSWErrOpenDrive724_U9 "J1939-71";
BA_ "SigType" SG_ 2632975264 PSWErrOpenDrive724_U6 1;
BA_ "SPN" SG_ 2632975264 PSWErrOpenDrive724_U6 91;
BA_ "SAEDocument" SG_ 2632975264 PSWErrOpenDrive724_U6 "J1939-71";
BA_ "SigType" SG_ 2632975264 PSWErrOpenDrive724_U13 1;
BA_ "SPN" SG_ 2632975264 PSWErrOpenDrive724_U13 91;
BA_ "SAEDocument" SG_ 2632975264 PSWErrOpenDrive724_U13 "J1939-71";
BA_ "SigType" SG_ 2632975264 PSWErrOpenDrive724_U12 1;
BA_ "SPN" SG_ 2632975264 PSWErrOpenDrive724_U12 91;
BA_ "SAEDocument" SG_ 2632975264 PSWErrOpenDrive724_U12 "J1939-71";
BA_ "SigType" SG_ 2632975251 PSWErrInValXR 1;
BA_ "SPN" SG_ 2632975251 PSWErrInValXR 91;
BA_ "SAEDocument" SG_ 2632975251 PSWErrInValXR "J1939-71";
BA_ "SigType" SG_ 2632975251 PSWErrInValXL 1;
BA_ "SPN" SG_ 2632975251 PSWErrInValXL 91;
BA_ "SAEDocument" SG_ 2632975251 PSWErrInValXL "J1939-71";
BA_ "SigType" SG_ 2632975251 PSWErrInValTr 1;
BA_ "SPN" SG_ 2632975251 PSWErrInValTr 91;
BA_ "SAEDocument" SG_ 2632975251 PSWErrInValTr "J1939-71";
BA_ "SigType" SG_ 2632975250 PSWErrInValRR 1;
BA_ "SPN" SG_ 2632975250 PSWErrInValRR 91;
BA_ "SAEDocument" SG_ 2632975250 PSWErrInValRR "J1939-71";
BA_ "SigType" SG_ 2632975250 PSWErrInValRL 1;
BA_ "SPN" SG_ 2632975250 PSWErrInValRL 91;
BA_ "SAEDocument" SG_ 2632975250 PSWErrInValRL "J1939-71";
BA_ "SigType" SG_ 2632975250 PSWErrInValFR 1;
BA_ "SPN" SG_ 2632975250 PSWErrInValFR 91;
BA_ "SAEDocument" SG_ 2632975250 PSWErrInValFR "J1939-71";
BA_ "SigType" SG_ 2632975250 PSWErrInValFL 1;
BA_ "SPN" SG_ 2632975250 PSWErrInValFL 91;
BA_ "SAEDocument" SG_ 2632975250 PSWErrInValFL "J1939-71";
BA_ "SigType" SG_ 2632975248 ASRRLowSideSt 1;
BA_ "SPN" SG_ 2632975248 ASRRLowSideSt 91;
BA_ "SAEDocument" SG_ 2632975248 ASRRLowSideSt "J1939-71";
BA_ "SigType" SG_ 2632975248 ASRFLowSideSt 1;
BA_ "SPN" SG_ 2632975248 ASRFLowSideSt 91;
BA_ "SAEDocument" SG_ 2632975248 ASRFLowSideSt "J1939-71";
BA_ "SigType" SG_ 2632975233 PSWWheelSpeedXR 1;
BA_ "SPN" SG_ 2632975233 PSWWheelSpeedXR 91;
BA_ "SAEDocument" SG_ 2632975233 PSWWheelSpeedXR "J1939-71";
BA_ "SigType" SG_ 2632975233 PSWWheelSpeedXL 1;
BA_ "SPN" SG_ 2632975233 PSWWheelSpeedXL 91;
BA_ "SAEDocument" SG_ 2632975233 PSWWheelSpeedXL "J1939-71";
BA_ "SigType" SG_ 2632975232 PSWWheelSpeedRR 1;
BA_ "SPN" SG_ 2632975232 PSWWheelSpeedRR 91;
BA_ "SAEDocument" SG_ 2632975232 PSWWheelSpeedRR "J1939-71";
BA_ "SigType" SG_ 2632975232 PSWWheelSpeedRL 1;
BA_ "SPN" SG_ 2632975232 PSWWheelSpeedRL 91;
BA_ "SAEDocument" SG_ 2632975232 PSWWheelSpeedRL "J1939-71";
BA_ "SigType" SG_ 2632975232 PSWWheelSpeedFR 1;
BA_ "SPN" SG_ 2632975232 PSWWheelSpeedFR 91;
BA_ "SAEDocument" SG_ 2632975232 PSWWheelSpeedFR "J1939-71";
BA_ "SigType" SG_ 2632975232 PSWWheelSpeedFL 1;
BA_ "SPN" SG_ 2632975232 PSWWheelSpeedFL 91;
BA_ "SAEDocument" SG_ 2632975232 PSWWheelSpeedFL "J1939-71";
BA_ "SigType" SG_ 2148676695 RearAxleRightWheelSpeed 1;
BA_ "SPN" SG_ 2148676695 RearAxleRightWheelSpeed 1595;
BA_ "SAEDocument" SG_ 2148676695 RearAxleRightWheelSpeed "J1939-71";
BA_ "SigType" SG_ 2148676695 RearAxleLeftWheelSpeed 1;
BA_ "SPN" SG_ 2148676695 RearAxleLeftWheelSpeed 1594;
BA_ "SAEDocument" SG_ 2148676695 RearAxleLeftWheelSpeed "J1939-71";
BA_ "SigType" SG_ 2148676695 FrontAxleRightWheelSpeed 1;
BA_ "SPN" SG_ 2148676695 FrontAxleRightWheelSpeed 1593;
BA_ "SAEDocument" SG_ 2148676695 FrontAxleRightWheelSpeed "J1939-71";
BA_ "SigType" SG_ 2148676695 FrontAxleLeftWheelSpeed 1;
BA_ "SPN" SG_ 2148676695 FrontAxleLeftWheelSpeed 1592;
BA_ "SAEDocument" SG_ 2148676695 FrontAxleLeftWheelSpeed "J1939-71";
BA_ "SAEDocument" SG_ 2148676694 A_A_ADC_wheelSPD "J1939-71";
BA_ "SPN" SG_ 2148676694 A_A_ADC_wheelSPD 985;
BA_ "SigType" SG_ 2148676694 A_A_ADC_wheelSPD 4;
BA_ "SAEDocument" SG_ 2148676694 A_A_ADC_errWssGap "J1939-71";
BA_ "SPN" SG_ 2148676694 A_A_ADC_errWssGap 985;
BA_ "SigType" SG_ 2148676694 A_A_ADC_errWssGap 4;
BA_ "SAEDocument" SG_ 2148676694 A_A_ADC_adcvalue "J1939-71";
BA_ "SPN" SG_ 2148676694 A_A_ADC_adcvalue 985;
BA_ "SigType" SG_ 2148676694 A_A_ADC_adcvalue 4;
BA_ "SigType" SG_ 2297441790 SpprtVrblTrnsRpttnRtFrAcclrtnSns 5;
BA_ "SPN" SG_ 2297441790 SpprtVrblTrnsRpttnRtFrAcclrtnSns 5353;
BA_ "SAEDocument" SG_ 2297441790 SpprtVrblTrnsRpttnRtFrAcclrtnSns "J1939-71";
BA_ "SigType" SG_ 2297441790 VrtclAcclrtnExRangeFigureOfMerit 5;
BA_ "SPN" SG_ 2297441790 VrtclAcclrtnExRangeFigureOfMerit 5352;
BA_ "SAEDocument" SG_ 2297441790 VrtclAcclrtnExRangeFigureOfMerit "J1939-71";
BA_ "SigType" SG_ 2297441790 LngtdnlAcclrtnExRngFigureOfMerit 5;
BA_ "SPN" SG_ 2297441790 LngtdnlAcclrtnExRngFigureOfMerit 5351;
BA_ "SAEDocument" SG_ 2297441790 LngtdnlAcclrtnExRngFigureOfMerit "J1939-71";
BA_ "SigType" SG_ 2297441790 LtrlAcclrtonExRangeFigureOfMerit 5;
BA_ "SPN" SG_ 2297441790 LtrlAcclrtonExRangeFigureOfMerit 5350;
BA_ "SAEDocument" SG_ 2297441790 LtrlAcclrtonExRangeFigureOfMerit "J1939-71";
BA_ "SigType" SG_ 2297441790 VerticalAccelerationExRange 1;
BA_ "SPN" SG_ 2297441790 VerticalAccelerationExRange 5349;
BA_ "SAEDocument" SG_ 2297441790 VerticalAccelerationExRange "J1939-71";
BA_ "SigType" SG_ 2297441790 LateralAccelerationExRange 1;
BA_ "SPN" SG_ 2297441790 LateralAccelerationExRange 5347;
BA_ "SAEDocument" SG_ 2297441790 LateralAccelerationExRange "J1939-71";
BA_ "SigType" SG_ 2297441790 LongitudinalAccelerationExRange 1;
BA_ "SPN" SG_ 2297441790 LongitudinalAccelerationExRange 5348;
BA_ "SAEDocument" SG_ 2297441790 LongitudinalAccelerationExRange "J1939-71";
BA_ "SigType" SG_ 2566712062 HybridBatteryPackRemainingCharge 1;
BA_ "SPN" SG_ 2566712062 HybridBatteryPackRemainingCharge 5464;
BA_ "SAEDocument" SG_ 2566712062 HybridBatteryPackRemainingCharge "J1939-71";
BA_ "SigType" SG_ 2364549630 RllAndPtchExRngMasurementLatency 1;
BA_ "SPN" SG_ 2364549630 RllAndPtchExRngMasurementLatency 4982;
BA_ "SAEDocument" SG_ 2364549630 RllAndPtchExRngMasurementLatency "J1939-71";
BA_ "SigType" SG_ 2364549630 RollAngleExRangeFigureOfMerit 5;
BA_ "SPN" SG_ 2364549630 RollAngleExRangeFigureOfMerit 4981;
BA_ "SAEDocument" SG_ 2364549630 RollAngleExRangeFigureOfMerit "J1939-71";
BA_ "SigType" SG_ 2364549630 RollAngleExRangeCompensation 5;
BA_ "SPN" SG_ 2364549630 RollAngleExRangeCompensation 4980;
BA_ "SAEDocument" SG_ 2364549630 RollAngleExRangeCompensation "J1939-71";
BA_ "SigType" SG_ 2364549630 PitchAngleExRangeFigureOfMerit 5;
BA_ "SPN" SG_ 2364549630 PitchAngleExRangeFigureOfMerit 4979;
BA_ "SAEDocument" SG_ 2364549630 PitchAngleExRangeFigureOfMerit "J1939-71";
BA_ "SigType" SG_ 2364549630 PitchAngleExRangeCompensation 5;
BA_ "SPN" SG_ 2364549630 PitchAngleExRangeCompensation 4978;
BA_ "SAEDocument" SG_ 2364549630 PitchAngleExRangeCompensation "J1939-71";
BA_ "SPN" SG_ 2364549630 RollAngleExRange 4977;
BA_ "SAEDocument" SG_ 2364549630 RollAngleExRange "J1939-71";
BA_ "SPN" SG_ 2364549630 PitchAngleExRange 4976;
BA_ "SAEDocument" SG_ 2364549630 PitchAngleExRange "J1939-71";
BA_ "SigType" SG_ 2499614462 OccpntClssficationSystem10Status 5;
BA_ "SPN" SG_ 2499614462 OccpntClssficationSystem10Status 4972;
BA_ "SAEDocument" SG_ 2499614462 OccpntClssficationSystem10Status "J1939-71";
BA_ "SigType" SG_ 2499614462 OccpntClssificationSystem9Status 5;
BA_ "SPN" SG_ 2499614462 OccpntClssificationSystem9Status 4971;
BA_ "SAEDocument" SG_ 2499614462 OccpntClssificationSystem9Status "J1939-71";
BA_ "SigType" SG_ 2499614462 OccpntClssificationSystem8Status 5;
BA_ "SPN" SG_ 2499614462 OccpntClssificationSystem8Status 4970;
BA_ "SAEDocument" SG_ 2499614462 OccpntClssificationSystem8Status "J1939-71";
BA_ "SigType" SG_ 2499614462 OccpntClssificationSystem7Status 5;
BA_ "SPN" SG_ 2499614462 OccpntClssificationSystem7Status 4969;
BA_ "SAEDocument" SG_ 2499614462 OccpntClssificationSystem7Status "J1939-71";
BA_ "SigType" SG_ 2499614462 OccpntClssificationSystem6Status 5;
BA_ "SPN" SG_ 2499614462 OccpntClssificationSystem6Status 4968;
BA_ "SAEDocument" SG_ 2499614462 OccpntClssificationSystem6Status "J1939-71";
BA_ "SigType" SG_ 2499614462 OccpntClssificationSystem5Status 5;
BA_ "SPN" SG_ 2499614462 OccpntClssificationSystem5Status 4967;
BA_ "SAEDocument" SG_ 2499614462 OccpntClssificationSystem5Status "J1939-71";
BA_ "SigType" SG_ 2499614462 OccpntClssificationSystem4Status 5;
BA_ "SPN" SG_ 2499614462 OccpntClssificationSystem4Status 4966;
BA_ "SAEDocument" SG_ 2499614462 OccpntClssificationSystem4Status "J1939-71";
BA_ "SigType" SG_ 2499614462 OccpntClssificationSystem3Status 5;
BA_ "SPN" SG_ 2499614462 OccpntClssificationSystem3Status 4965;
BA_ "SAEDocument" SG_ 2499614462 OccpntClssificationSystem3Status "J1939-71";
BA_ "SPN" SG_ 2499614462 PssngrOccpntClssfctnSystemStatus 4964;
BA_ "SAEDocument" SG_ 2499614462 PssngrOccpntClssfctnSystemStatus "J1939-71";
BA_ "SPN" SG_ 2499614462 DrvrOccpntClssfctionSystemStatus 4963;
BA_ "SAEDocument" SG_ 2499614462 DrvrOccpntClssfctionSystemStatus "J1939-71";
BA_ "SPN" SG_ 2560098046 CabNoiseCtrlTuningStatus 5060;
BA_ "SAEDocument" SG_ 2560098046 CabNoiseCtrlTuningStatus "J1939-71";
BA_ "SigType" SG_ 2560098046 CabNoiseCtrlStatus 5;
BA_ "SPN" SG_ 2560098046 CabNoiseCtrlStatus 5059;
BA_ "SAEDocument" SG_ 2560098046 CabNoiseCtrlStatus "J1939-71";
BA_ "SPN" SG_ 2560163582 CabNoiseCtrlTuningState 5058;
BA_ "SAEDocument" SG_ 2560163582 CabNoiseCtrlTuningState "J1939-71";
BA_ "SigType" SG_ 2560163582 CabNoiseCtrlState 5;
BA_ "SPN" SG_ 2560163582 CabNoiseCtrlState 5057;
BA_ "SAEDocument" SG_ 2560163582 CabNoiseCtrlState "J1939-71";
BA_ "SigType" SG_ 2297441534 DropRelayCtrl 5;
BA_ "SPN" SG_ 2297441534 DropRelayCtrl 5403;
BA_ "SAEDocument" SG_ 2297441534 DropRelayCtrl "J1939-71";
BA_ "SigType" SG_ 2297441534 LiftRelayCtrl 5;
BA_ "SPN" SG_ 2297441534 LiftRelayCtrl 5402;
BA_ "SAEDocument" SG_ 2297441534 LiftRelayCtrl "J1939-71";
BA_ "SigType" SG_ 2297441534 MaterialDropActiveStatus 5;
BA_ "SPN" SG_ 2297441534 MaterialDropActiveStatus 5014;
BA_ "SAEDocument" SG_ 2297441534 MaterialDropActiveStatus "J1939-71";
BA_ "SigType" SG_ 2297441534 MaterialLiftActiveStatus 5;
BA_ "SPN" SG_ 2297441534 MaterialLiftActiveStatus 5013;
BA_ "SAEDocument" SG_ 2297441534 MaterialLiftActiveStatus "J1939-71";
BA_ "SigType" SG_ 2297441534 GneratorCurrentBoostActiveStatus 5;
BA_ "SPN" SG_ 2297441534 GneratorCurrentBoostActiveStatus 5012;
BA_ "SAEDocument" SG_ 2297441534 GneratorCurrentBoostActiveStatus "J1939-71";
BA_ "SigType" SG_ 2297441534 MaterialDropSwitch 5;
BA_ "SPN" SG_ 2297441534 MaterialDropSwitch 5011;
BA_ "SAEDocument" SG_ 2297441534 MaterialDropSwitch "J1939-71";
BA_ "SigType" SG_ 2297441534 MaterialLiftSwitch 5;
BA_ "SPN" SG_ 2297441534 MaterialLiftSwitch 5010;
BA_ "SAEDocument" SG_ 2297441534 MaterialLiftSwitch "J1939-71";
BA_ "SPN" SG_ 2297441534 MagnetReverseCurrent 5009;
BA_ "SAEDocument" SG_ 2297441534 MagnetReverseCurrent "J1939-71";
BA_ "SPN" SG_ 2297441534 MagnetForwardCurrent 5008;
BA_ "SAEDocument" SG_ 2297441534 MagnetForwardCurrent "J1939-71";
BA_ "SigType" SG_ 2566722302 GeneratorDutyCycleExceededStatus 5;
BA_ "SPN" SG_ 2566722302 GeneratorDutyCycleExceededStatus 5007;
BA_ "SAEDocument" SG_ 2566722302 GeneratorDutyCycleExceededStatus "J1939-71";
BA_ "SigType" SG_ 2566722302 VoltageMonitorActiveStatus 5;
BA_ "SPN" SG_ 2566722302 VoltageMonitorActiveStatus 5006;
BA_ "SAEDocument" SG_ 2566722302 VoltageMonitorActiveStatus "J1939-71";
BA_ "SigType" SG_ 2566722302 GensetEnableActiveStatus 5;
BA_ "SPN" SG_ 2566722302 GensetEnableActiveStatus 5005;
BA_ "SAEDocument" SG_ 2566722302 GensetEnableActiveStatus "J1939-71";
BA_ "SPN" SG_ 2566722302 ReverseCurrentRangeSetting 5002;
BA_ "SAEDocument" SG_ 2566722302 ReverseCurrentRangeSetting "J1939-71";
BA_ "SigType" SG_ 2566722302 GensetSoftstartActiveStatus 5;
BA_ "SPN" SG_ 2566722302 GensetSoftstartActiveStatus 5004;
BA_ "SAEDocument" SG_ 2566722302 GensetSoftstartActiveStatus "J1939-71";
BA_ "SigType" SG_ 2566722302 Grapple_MagnetSelectionSwitch 5;
BA_ "SPN" SG_ 2566722302 Grapple_MagnetSelectionSwitch 5003;
BA_ "SAEDocument" SG_ 2566722302 Grapple_MagnetSelectionSwitch "J1939-71";
BA_ "SigType" SG_ 2566722302 GnstSystmOtputVoltageRangeStatus 5;
BA_ "SPN" SG_ 2566722302 GnstSystmOtputVoltageRangeStatus 5001;
BA_ "SAEDocument" SG_ 2566722302 GnstSystmOtputVoltageRangeStatus "J1939-71";
BA_ "SigType" SG_ 2566722302 GeneratorOverheatStatus 5;
BA_ "SPN" SG_ 2566722302 GeneratorOverheatStatus 5000;
BA_ "SAEDocument" SG_ 2566722302 GeneratorOverheatStatus "J1939-71";
BA_ "SPN" SG_ 2566722558 MagnetRatedPower 4999;
BA_ "SAEDocument" SG_ 2566722558 MagnetRatedPower "J1939-71";
BA_ "SPN" SG_ 2566722558 MagnetBoostTime 4998;
BA_ "SAEDocument" SG_ 2566722558 MagnetBoostTime "J1939-71";
BA_ "SPN" SG_ 2560032510 LwVltgDscnnctDsiredOperatingMode 5149;
BA_ "SAEDocument" SG_ 2560032510 LwVltgDscnnctDsiredOperatingMode "J1939-71";
BA_ "SigType" SG_ 2566717950 LowVoltageDisconnectTemp 1;
BA_ "SPN" SG_ 2566717950 LowVoltageDisconnectTemp 5148;
BA_ "SAEDocument" SG_ 2566717950 LowVoltageDisconnectTemp "J1939-71";
BA_ "SPN" SG_ 2566717950 LwVltgeDisconnectVoutOutputState 5147;
BA_ "SAEDocument" SG_ 2566717950 LwVltgeDisconnectVoutOutputState "J1939-71";
BA_ "SPN" SG_ 2566717950 LowVoltageDisconnectOutput1State 5146;
BA_ "SAEDocument" SG_ 2566717950 LowVoltageDisconnectOutput1State "J1939-71";
BA_ "SPN" SG_ 2566717950 LowVoltageDisconnectOutput2State 5145;
BA_ "SAEDocument" SG_ 2566717950 LowVoltageDisconnectOutput2State "J1939-71";
BA_ "SPN" SG_ 2566717950 LowVoltageDisconnectOutput3State 5144;
BA_ "SAEDocument" SG_ 2566717950 LowVoltageDisconnectOutput3State "J1939-71";
BA_ "SPN" SG_ 2566717950 LwVltgDscnnctCrrentOperatingMode 5143;
BA_ "SAEDocument" SG_ 2566717950 LwVltgDscnnctCrrentOperatingMode "J1939-71";
BA_ "SigType" SG_ 2566717950 LwVltgDscnnectManualConnectState 4;
BA_ "SPN" SG_ 2566717950 LwVltgDscnnectManualConnectState 5142;
BA_ "SAEDocument" SG_ 2566717950 LwVltgDscnnectManualConnectState "J1939-71";
BA_ "SigType" SG_ 2566717950 LwVltgDscnnctMnalDisconnectState 4;
BA_ "SPN" SG_ 2566717950 LwVltgDscnnctMnalDisconnectState 5141;
BA_ "SAEDocument" SG_ 2566717950 LwVltgDscnnctMnalDisconnectState "J1939-71";
BA_ "SPN" SG_ 2499604222 BldReferenceElevationOffsetRight 5413;
BA_ "SAEDocument" SG_ 2499604222 BldReferenceElevationOffsetRight "J1939-71";
BA_ "SPN" SG_ 2499604222 BldeReferenceElevationOffsetLeft 5412;
BA_ "SAEDocument" SG_ 2499604222 BldeReferenceElevationOffsetLeft "J1939-71";
BA_ "SPN" SG_ 2499604222 BladeElevationDeviationRight 5411;
BA_ "SAEDocument" SG_ 2499604222 BladeElevationDeviationRight "J1939-71";
BA_ "SPN" SG_ 2499604222 BladeElevationDeviationLeft 5410;
BA_ "SAEDocument" SG_ 2499604222 BladeElevationDeviationLeft "J1939-71";
BA_ "SigType" SG_ 2358902526 Joystick3Lamp10Cmd 5;
BA_ "SPN" SG_ 2358902526 Joystick3Lamp10Cmd 4489;
BA_ "SAEDocument" SG_ 2358902526 Joystick3Lamp10Cmd "J1939-71";
BA_ "SigType" SG_ 2358902526 Joystick3Lamp9Cmd 5;
BA_ "SPN" SG_ 2358902526 Joystick3Lamp9Cmd 4488;
BA_ "SAEDocument" SG_ 2358902526 Joystick3Lamp9Cmd "J1939-71";
BA_ "SigType" SG_ 2358902526 Joystick3Lamp8Cmd 5;
BA_ "SPN" SG_ 2358902526 Joystick3Lamp8Cmd 4487;
BA_ "SAEDocument" SG_ 2358902526 Joystick3Lamp8Cmd "J1939-71";
BA_ "SigType" SG_ 2358902526 Joystick3Lamp7Cmd 5;
BA_ "SPN" SG_ 2358902526 Joystick3Lamp7Cmd 4486;
BA_ "SAEDocument" SG_ 2358902526 Joystick3Lamp7Cmd "J1939-71";
BA_ "SigType" SG_ 2358902526 Joystick3Lamp6Cmd 5;
BA_ "SPN" SG_ 2358902526 Joystick3Lamp6Cmd 4485;
BA_ "SAEDocument" SG_ 2358902526 Joystick3Lamp6Cmd "J1939-71";
BA_ "SigType" SG_ 2358902526 Joystick3Lamp5Cmd 5;
BA_ "SPN" SG_ 2358902526 Joystick3Lamp5Cmd 4484;
BA_ "SAEDocument" SG_ 2358902526 Joystick3Lamp5Cmd "J1939-71";
BA_ "SigType" SG_ 2358902526 Joystick3Lamp4Cmd 5;
BA_ "SPN" SG_ 2358902526 Joystick3Lamp4Cmd 4483;
BA_ "SAEDocument" SG_ 2358902526 Joystick3Lamp4Cmd "J1939-71";
BA_ "SigType" SG_ 2358902526 Joystick3Lamp3Cmd 5;
BA_ "SPN" SG_ 2358902526 Joystick3Lamp3Cmd 4482;
BA_ "SAEDocument" SG_ 2358902526 Joystick3Lamp3Cmd "J1939-71";
BA_ "SigType" SG_ 2358902526 Joystick3Lamp2Cmd 5;
BA_ "SPN" SG_ 2358902526 Joystick3Lamp2Cmd 4481;
BA_ "SAEDocument" SG_ 2358902526 Joystick3Lamp2Cmd "J1939-71";
BA_ "SigType" SG_ 2358902526 Joystick3Lamp1Cmd 5;
BA_ "SPN" SG_ 2358902526 Joystick3Lamp1Cmd 4480;
BA_ "SAEDocument" SG_ 2358902526 Joystick3Lamp1Cmd "J1939-71";
BA_ "SigType" SG_ 2358902526 Joystick2Lamp10Cmd 5;
BA_ "SPN" SG_ 2358902526 Joystick2Lamp10Cmd 4479;
BA_ "SAEDocument" SG_ 2358902526 Joystick2Lamp10Cmd "J1939-71";
BA_ "SigType" SG_ 2358902526 Joystick2Lamp9Cmd 5;
BA_ "SPN" SG_ 2358902526 Joystick2Lamp9Cmd 4478;
BA_ "SAEDocument" SG_ 2358902526 Joystick2Lamp9Cmd "J1939-71";
BA_ "SigType" SG_ 2358902526 Joystick2Lamp8Cmd 5;
BA_ "SPN" SG_ 2358902526 Joystick2Lamp8Cmd 4477;
BA_ "SAEDocument" SG_ 2358902526 Joystick2Lamp8Cmd "J1939-71";
BA_ "SigType" SG_ 2358902526 Joystick2Lamp7Cmd 5;
BA_ "SPN" SG_ 2358902526 Joystick2Lamp7Cmd 4476;
BA_ "SAEDocument" SG_ 2358902526 Joystick2Lamp7Cmd "J1939-71";
BA_ "SigType" SG_ 2358902526 Joystick2Lamp6Cmd 5;
BA_ "SPN" SG_ 2358902526 Joystick2Lamp6Cmd 4475;
BA_ "SAEDocument" SG_ 2358902526 Joystick2Lamp6Cmd "J1939-71";
BA_ "SigType" SG_ 2358902526 Joystick2Lamp5Cmd 5;
BA_ "SPN" SG_ 2358902526 Joystick2Lamp5Cmd 4474;
BA_ "SAEDocument" SG_ 2358902526 Joystick2Lamp5Cmd "J1939-71";
BA_ "SigType" SG_ 2358902526 Joystick2Lamp4Cmd 5;
BA_ "SPN" SG_ 2358902526 Joystick2Lamp4Cmd 4473;
BA_ "SAEDocument" SG_ 2358902526 Joystick2Lamp4Cmd "J1939-71";
BA_ "SigType" SG_ 2358902526 Joystick2Lamp3Cmd 5;
BA_ "SPN" SG_ 2358902526 Joystick2Lamp3Cmd 4472;
BA_ "SAEDocument" SG_ 2358902526 Joystick2Lamp3Cmd "J1939-71";
BA_ "SigType" SG_ 2358902526 Joystick2Lamp2Cmd 5;
BA_ "SPN" SG_ 2358902526 Joystick2Lamp2Cmd 4471;
BA_ "SAEDocument" SG_ 2358902526 Joystick2Lamp2Cmd "J1939-71";
BA_ "SigType" SG_ 2358902526 Joystick2Lamp1Cmd 5;
BA_ "SPN" SG_ 2358902526 Joystick2Lamp1Cmd 4470;
BA_ "SAEDocument" SG_ 2358902526 Joystick2Lamp1Cmd "J1939-71";
BA_ "SigType" SG_ 2358902526 Joystick1Lamp10Cmd 5;
BA_ "SPN" SG_ 2358902526 Joystick1Lamp10Cmd 4469;
BA_ "SAEDocument" SG_ 2358902526 Joystick1Lamp10Cmd "J1939-71";
BA_ "SigType" SG_ 2358902526 Joystick1Lamp9Cmd 5;
BA_ "SPN" SG_ 2358902526 Joystick1Lamp9Cmd 4468;
BA_ "SAEDocument" SG_ 2358902526 Joystick1Lamp9Cmd "J1939-71";
BA_ "SigType" SG_ 2358902526 Joystick1Lamp8Cmd 5;
BA_ "SPN" SG_ 2358902526 Joystick1Lamp8Cmd 4467;
BA_ "SAEDocument" SG_ 2358902526 Joystick1Lamp8Cmd "J1939-71";
BA_ "SigType" SG_ 2358902526 Joystick1Lamp7Cmd 5;
BA_ "SPN" SG_ 2358902526 Joystick1Lamp7Cmd 4466;
BA_ "SAEDocument" SG_ 2358902526 Joystick1Lamp7Cmd "J1939-71";
BA_ "SigType" SG_ 2358902526 Joystick1Lamp6Cmd 5;
BA_ "SPN" SG_ 2358902526 Joystick1Lamp6Cmd 4465;
BA_ "SAEDocument" SG_ 2358902526 Joystick1Lamp6Cmd "J1939-71";
BA_ "SigType" SG_ 2358902526 Joystick1Lamp5Cmd 5;
BA_ "SPN" SG_ 2358902526 Joystick1Lamp5Cmd 4464;
BA_ "SAEDocument" SG_ 2358902526 Joystick1Lamp5Cmd "J1939-71";
BA_ "SigType" SG_ 2358902526 Joystick1Lamp4Cmd 5;
BA_ "SPN" SG_ 2358902526 Joystick1Lamp4Cmd 4463;
BA_ "SAEDocument" SG_ 2358902526 Joystick1Lamp4Cmd "J1939-71";
BA_ "SigType" SG_ 2358902526 Joystick1Lamp3Cmd 5;
BA_ "SPN" SG_ 2358902526 Joystick1Lamp3Cmd 4462;
BA_ "SAEDocument" SG_ 2358902526 Joystick1Lamp3Cmd "J1939-71";
BA_ "SigType" SG_ 2358902526 Joystick1Lamp2Cmd 5;
BA_ "SPN" SG_ 2358902526 Joystick1Lamp2Cmd 4461;
BA_ "SAEDocument" SG_ 2358902526 Joystick1Lamp2Cmd "J1939-71";
BA_ "SigType" SG_ 2358902526 Joystick1Lamp1Cmd 5;
BA_ "SPN" SG_ 2358902526 Joystick1Lamp1Cmd 4460;
BA_ "SAEDocument" SG_ 2358902526 Joystick1Lamp1Cmd "J1939-71";
BA_ "SigType" SG_ 2566711550 IntkVlvActtnSystmOlPrss2SlndCtrl 5;
BA_ "SPN" SG_ 2566711550 IntkVlvActtnSystmOlPrss2SlndCtrl 5500;
BA_ "SAEDocument" SG_ 2566711550 IntkVlvActtnSystmOlPrss2SlndCtrl "J1939-71";
BA_ "SigType" SG_ 2566711550 IntkVlvActtnSystmOlPrss1SlndCtrl 5;
BA_ "SPN" SG_ 2566711550 IntkVlvActtnSystmOlPrss1SlndCtrl 5499;
BA_ "SAEDocument" SG_ 2566711550 IntkVlvActtnSystmOlPrss1SlndCtrl "J1939-71";
BA_ "SigType" SG_ 2633832958 SpecialIgnitorLoop90Resistance 1;
BA_ "SPN" SG_ 2633832958 SpecialIgnitorLoop90Resistance 4917;
BA_ "SAEDocument" SG_ 2633832958 SpecialIgnitorLoop90Resistance "J1939-71";
BA_ "SigType" SG_ 2633832958 SpecialIgnitorLoop89Resistance 1;
BA_ "SPN" SG_ 2633832958 SpecialIgnitorLoop89Resistance 4916;
BA_ "SAEDocument" SG_ 2633832958 SpecialIgnitorLoop89Resistance "J1939-71";
BA_ "SigType" SG_ 2633832958 SpecialIgnitorLoop88Resistance 1;
BA_ "SPN" SG_ 2633832958 SpecialIgnitorLoop88Resistance 4915;
BA_ "SAEDocument" SG_ 2633832958 SpecialIgnitorLoop88Resistance "J1939-71";
BA_ "SigType" SG_ 2633832958 SpecialIgnitorLoop87Resistance 1;
BA_ "SPN" SG_ 2633832958 SpecialIgnitorLoop87Resistance 4914;
BA_ "SAEDocument" SG_ 2633832958 SpecialIgnitorLoop87Resistance "J1939-71";
BA_ "SigType" SG_ 2633832958 SpecialIgnitorLoop86Resistance 1;
BA_ "SPN" SG_ 2633832958 SpecialIgnitorLoop86Resistance 4913;
BA_ "SAEDocument" SG_ 2633832958 SpecialIgnitorLoop86Resistance "J1939-71";
BA_ "SigType" SG_ 2633832958 SpecialIgnitorLoop85Resistance 1;
BA_ "SPN" SG_ 2633832958 SpecialIgnitorLoop85Resistance 4912;
BA_ "SAEDocument" SG_ 2633832958 SpecialIgnitorLoop85Resistance "J1939-71";
BA_ "SigType" SG_ 2633832958 SpecialIgnitorLoop84Resistance 1;
BA_ "SPN" SG_ 2633832958 SpecialIgnitorLoop84Resistance 4911;
BA_ "SAEDocument" SG_ 2633832958 SpecialIgnitorLoop84Resistance "J1939-71";
BA_ "SigType" SG_ 2633832958 SpecialIgnitorLoop83Resistance 1;
BA_ "SPN" SG_ 2633832958 SpecialIgnitorLoop83Resistance 4910;
BA_ "SAEDocument" SG_ 2633832958 SpecialIgnitorLoop83Resistance "J1939-71";
BA_ "SigType" SG_ 2633832958 SpecialIgnitorLoop82Resistance 1;
BA_ "SPN" SG_ 2633832958 SpecialIgnitorLoop82Resistance 4909;
BA_ "SAEDocument" SG_ 2633832958 SpecialIgnitorLoop82Resistance "J1939-71";
BA_ "SigType" SG_ 2633832958 SpecialIgnitorLoop81Resistance 1;
BA_ "SPN" SG_ 2633832958 SpecialIgnitorLoop81Resistance 4908;
BA_ "SAEDocument" SG_ 2633832958 SpecialIgnitorLoop81Resistance "J1939-71";
BA_ "SigType" SG_ 2633832958 SpecialIgnitorLoop80Resistance 1;
BA_ "SPN" SG_ 2633832958 SpecialIgnitorLoop80Resistance 4907;
BA_ "SAEDocument" SG_ 2633832958 SpecialIgnitorLoop80Resistance "J1939-71";
BA_ "SigType" SG_ 2633832958 SpecialIgnitorLoop79Resistance 1;
BA_ "SPN" SG_ 2633832958 SpecialIgnitorLoop79Resistance 4906;
BA_ "SAEDocument" SG_ 2633832958 SpecialIgnitorLoop79Resistance "J1939-71";
BA_ "SigType" SG_ 2633832958 SpecialIgnitorLoop78Resistance 1;
BA_ "SPN" SG_ 2633832958 SpecialIgnitorLoop78Resistance 4905;
BA_ "SAEDocument" SG_ 2633832958 SpecialIgnitorLoop78Resistance "J1939-71";
BA_ "SigType" SG_ 2633832958 SpecialIgnitorLoop77Resistance 1;
BA_ "SPN" SG_ 2633832958 SpecialIgnitorLoop77Resistance 4904;
BA_ "SAEDocument" SG_ 2633832958 SpecialIgnitorLoop77Resistance "J1939-71";
BA_ "SigType" SG_ 2633832958 SpecialIgnitorLoop76Resistance 1;
BA_ "SPN" SG_ 2633832958 SpecialIgnitorLoop76Resistance 4903;
BA_ "SAEDocument" SG_ 2633832958 SpecialIgnitorLoop76Resistance "J1939-71";
BA_ "SigType" SG_ 2633832958 SpecialIgnitorLoop75Resistance 1;
BA_ "SPN" SG_ 2633832958 SpecialIgnitorLoop75Resistance 4902;
BA_ "SAEDocument" SG_ 2633832958 SpecialIgnitorLoop75Resistance "J1939-71";
BA_ "SigType" SG_ 2633832958 SpecialIgnitorLoop74Resistance 1;
BA_ "SPN" SG_ 2633832958 SpecialIgnitorLoop74Resistance 4901;
BA_ "SAEDocument" SG_ 2633832958 SpecialIgnitorLoop74Resistance "J1939-71";
BA_ "SigType" SG_ 2633832958 SpecialIgnitorLoop73Resistance 1;
BA_ "SPN" SG_ 2633832958 SpecialIgnitorLoop73Resistance 4900;
BA_ "SAEDocument" SG_ 2633832958 SpecialIgnitorLoop73Resistance "J1939-71";
BA_ "SigType" SG_ 2633832958 SpecialIgnitorLoop72Resistance 1;
BA_ "SPN" SG_ 2633832958 SpecialIgnitorLoop72Resistance 4899;
BA_ "SAEDocument" SG_ 2633832958 SpecialIgnitorLoop72Resistance "J1939-71";
BA_ "SigType" SG_ 2633832958 SpecialIgnitorLoop71Resistance 1;
BA_ "SPN" SG_ 2633832958 SpecialIgnitorLoop71Resistance 4898;
BA_ "SAEDocument" SG_ 2633832958 SpecialIgnitorLoop71Resistance "J1939-71";
BA_ "SigType" SG_ 2633832958 SpecialIgnitorLoop70Resistance 1;
BA_ "SPN" SG_ 2633832958 SpecialIgnitorLoop70Resistance 4897;
BA_ "SAEDocument" SG_ 2633832958 SpecialIgnitorLoop70Resistance "J1939-71";
BA_ "SigType" SG_ 2633832958 SpecialIgnitorLoop69Resistance 1;
BA_ "SPN" SG_ 2633832958 SpecialIgnitorLoop69Resistance 4896;
BA_ "SAEDocument" SG_ 2633832958 SpecialIgnitorLoop69Resistance "J1939-71";
BA_ "SigType" SG_ 2633832958 SpecialIgnitorLoop68Resistance 1;
BA_ "SPN" SG_ 2633832958 SpecialIgnitorLoop68Resistance 4895;
BA_ "SAEDocument" SG_ 2633832958 SpecialIgnitorLoop68Resistance "J1939-71";
BA_ "SigType" SG_ 2633832958 SpecialIgnitorLoop67Resistance 1;
BA_ "SPN" SG_ 2633832958 SpecialIgnitorLoop67Resistance 4894;
BA_ "SAEDocument" SG_ 2633832958 SpecialIgnitorLoop67Resistance "J1939-71";
BA_ "SigType" SG_ 2633832958 SpecialIgnitorLoop66Resistance 1;
BA_ "SPN" SG_ 2633832958 SpecialIgnitorLoop66Resistance 4893;
BA_ "SAEDocument" SG_ 2633832958 SpecialIgnitorLoop66Resistance "J1939-71";
BA_ "SigType" SG_ 2633832958 SpecialIgnitorLoop65Resistance 1;
BA_ "SPN" SG_ 2633832958 SpecialIgnitorLoop65Resistance 4892;
BA_ "SAEDocument" SG_ 2633832958 SpecialIgnitorLoop65Resistance "J1939-71";
BA_ "SigType" SG_ 2633832958 SpecialIgnitorLoop64Resistance 1;
BA_ "SPN" SG_ 2633832958 SpecialIgnitorLoop64Resistance 4891;
BA_ "SAEDocument" SG_ 2633832958 SpecialIgnitorLoop64Resistance "J1939-71";
BA_ "SigType" SG_ 2633832958 SpecialIgnitorLoop63Resistance 1;
BA_ "SPN" SG_ 2633832958 SpecialIgnitorLoop63Resistance 4890;
BA_ "SAEDocument" SG_ 2633832958 SpecialIgnitorLoop63Resistance "J1939-71";
BA_ "SigType" SG_ 2633832958 SpecialIgnitorLoop61Resistance 1;
BA_ "SPN" SG_ 2633832958 SpecialIgnitorLoop61Resistance 4888;
BA_ "SAEDocument" SG_ 2633832958 SpecialIgnitorLoop61Resistance "J1939-71";
BA_ "SigType" SG_ 2633832958 SpecialIgnitorLoop60Resistance 1;
BA_ "SPN" SG_ 2633832958 SpecialIgnitorLoop60Resistance 4887;
BA_ "SAEDocument" SG_ 2633832958 SpecialIgnitorLoop60Resistance "J1939-71";
BA_ "SigType" SG_ 2633832958 SpecialIgnitorLoop59Resistance 1;
BA_ "SPN" SG_ 2633832958 SpecialIgnitorLoop59Resistance 4886;
BA_ "SAEDocument" SG_ 2633832958 SpecialIgnitorLoop59Resistance "J1939-71";
BA_ "SigType" SG_ 2633832958 SpecialIgnitorLoop58Resistance 1;
BA_ "SPN" SG_ 2633832958 SpecialIgnitorLoop58Resistance 4885;
BA_ "SAEDocument" SG_ 2633832958 SpecialIgnitorLoop58Resistance "J1939-71";
BA_ "SigType" SG_ 2633832958 SpecialIgnitorLoop57Resistance 1;
BA_ "SPN" SG_ 2633832958 SpecialIgnitorLoop57Resistance 4884;
BA_ "SAEDocument" SG_ 2633832958 SpecialIgnitorLoop57Resistance "J1939-71";
BA_ "SigType" SG_ 2633832958 SpecialIgnitorLoop56Resistance 1;
BA_ "SPN" SG_ 2633832958 SpecialIgnitorLoop56Resistance 4883;
BA_ "SAEDocument" SG_ 2633832958 SpecialIgnitorLoop56Resistance "J1939-71";
BA_ "SigType" SG_ 2633832958 SpecialIgnitorLoop55Resistance 1;
BA_ "SPN" SG_ 2633832958 SpecialIgnitorLoop55Resistance 4882;
BA_ "SAEDocument" SG_ 2633832958 SpecialIgnitorLoop55Resistance "J1939-71";
BA_ "SigType" SG_ 2633832958 SpecialIgnitorLoop54Resistance 1;
BA_ "SPN" SG_ 2633832958 SpecialIgnitorLoop54Resistance 4881;
BA_ "SAEDocument" SG_ 2633832958 SpecialIgnitorLoop54Resistance "J1939-71";
BA_ "SigType" SG_ 2633832958 SpecialIgnitorLoop53Resistance 1;
BA_ "SPN" SG_ 2633832958 SpecialIgnitorLoop53Resistance 4880;
BA_ "SAEDocument" SG_ 2633832958 SpecialIgnitorLoop53Resistance "J1939-71";
BA_ "SigType" SG_ 2633832958 SpecialIgnitorLoop52Resistance 1;
BA_ "SPN" SG_ 2633832958 SpecialIgnitorLoop52Resistance 4879;
BA_ "SAEDocument" SG_ 2633832958 SpecialIgnitorLoop52Resistance "J1939-71";
BA_ "SigType" SG_ 2633832958 SpecialIgnitorLoop51Resistance 1;
BA_ "SPN" SG_ 2633832958 SpecialIgnitorLoop51Resistance 4878;
BA_ "SAEDocument" SG_ 2633832958 SpecialIgnitorLoop51Resistance "J1939-71";
BA_ "SigType" SG_ 2633832958 SpecialIgnitorLoop50Resistance 1;
BA_ "SPN" SG_ 2633832958 SpecialIgnitorLoop50Resistance 4877;
BA_ "SAEDocument" SG_ 2633832958 SpecialIgnitorLoop50Resistance "J1939-71";
BA_ "SigType" SG_ 2633832958 SpecialIgnitorLoop49Resistance 1;
BA_ "SPN" SG_ 2633832958 SpecialIgnitorLoop49Resistance 4876;
BA_ "SAEDocument" SG_ 2633832958 SpecialIgnitorLoop49Resistance "J1939-71";
BA_ "SigType" SG_ 2633832958 SpecialIgnitorLoop48Resistance 1;
BA_ "SPN" SG_ 2633832958 SpecialIgnitorLoop48Resistance 4875;
BA_ "SAEDocument" SG_ 2633832958 SpecialIgnitorLoop48Resistance "J1939-71";
BA_ "SigType" SG_ 2633832958 SpecialIgnitorLoop47Resistance 1;
BA_ "SPN" SG_ 2633832958 SpecialIgnitorLoop47Resistance 4874;
BA_ "SAEDocument" SG_ 2633832958 SpecialIgnitorLoop47Resistance "J1939-71";
BA_ "SigType" SG_ 2633832958 SpecialIgnitorLoop46Resistance 1;
BA_ "SPN" SG_ 2633832958 SpecialIgnitorLoop46Resistance 4873;
BA_ "SAEDocument" SG_ 2633832958 SpecialIgnitorLoop46Resistance "J1939-71";
BA_ "SigType" SG_ 2633832958 SpecialIgnitorLoop45Resistance 1;
BA_ "SPN" SG_ 2633832958 SpecialIgnitorLoop45Resistance 4872;
BA_ "SAEDocument" SG_ 2633832958 SpecialIgnitorLoop45Resistance "J1939-71";
BA_ "SigType" SG_ 2633832958 SpecialIgnitorLoop44Resistance 1;
BA_ "SPN" SG_ 2633832958 SpecialIgnitorLoop44Resistance 4871;
BA_ "SAEDocument" SG_ 2633832958 SpecialIgnitorLoop44Resistance "J1939-71";
BA_ "SigType" SG_ 2633832958 SpecialIgnitorLoop43Resistance 1;
BA_ "SPN" SG_ 2633832958 SpecialIgnitorLoop43Resistance 4870;
BA_ "SAEDocument" SG_ 2633832958 SpecialIgnitorLoop43Resistance "J1939-71";
BA_ "SigType" SG_ 2633832958 SpecialIgnitorLoop42Resistance 1;
BA_ "SPN" SG_ 2633832958 SpecialIgnitorLoop42Resistance 4869;
BA_ "SAEDocument" SG_ 2633832958 SpecialIgnitorLoop42Resistance "J1939-71";
BA_ "SigType" SG_ 2633832958 SpecialIgnitorLoop41Resistance 1;
BA_ "SPN" SG_ 2633832958 SpecialIgnitorLoop41Resistance 4868;
BA_ "SAEDocument" SG_ 2633832958 SpecialIgnitorLoop41Resistance "J1939-71";
BA_ "SigType" SG_ 2633832958 SpecialIgnitorLoop40Resistance 1;
BA_ "SPN" SG_ 2633832958 SpecialIgnitorLoop40Resistance 4867;
BA_ "SAEDocument" SG_ 2633832958 SpecialIgnitorLoop40Resistance "J1939-71";
BA_ "SigType" SG_ 2633832958 SpecialIgnitorLoop39Resistance 1;
BA_ "SPN" SG_ 2633832958 SpecialIgnitorLoop39Resistance 4866;
BA_ "SAEDocument" SG_ 2633832958 SpecialIgnitorLoop39Resistance "J1939-71";
BA_ "SigType" SG_ 2633832958 SpecialIgnitorLoop38Resistance 1;
BA_ "SPN" SG_ 2633832958 SpecialIgnitorLoop38Resistance 4865;
BA_ "SAEDocument" SG_ 2633832958 SpecialIgnitorLoop38Resistance "J1939-71";
BA_ "SigType" SG_ 2633832958 SpecialIgnitorLoop37Resistance 1;
BA_ "SPN" SG_ 2633832958 SpecialIgnitorLoop37Resistance 4864;
BA_ "SAEDocument" SG_ 2633832958 SpecialIgnitorLoop37Resistance "J1939-71";
BA_ "SigType" SG_ 2633832958 SpecialIgnitorLoop36Resistance 1;
BA_ "SPN" SG_ 2633832958 SpecialIgnitorLoop36Resistance 4863;
BA_ "SAEDocument" SG_ 2633832958 SpecialIgnitorLoop36Resistance "J1939-71";
BA_ "SigType" SG_ 2633832958 SpecialIgnitorLoop35Resistance 1;
BA_ "SPN" SG_ 2633832958 SpecialIgnitorLoop35Resistance 4862;
BA_ "SAEDocument" SG_ 2633832958 SpecialIgnitorLoop35Resistance "J1939-71";
BA_ "SigType" SG_ 2633832958 SpecialIgnitorLoop34Resistance 1;
BA_ "SPN" SG_ 2633832958 SpecialIgnitorLoop34Resistance 4861;
BA_ "SAEDocument" SG_ 2633832958 SpecialIgnitorLoop34Resistance "J1939-71";
BA_ "SigType" SG_ 2633832958 SpecialIgnitorLoop33Resistance 1;
BA_ "SPN" SG_ 2633832958 SpecialIgnitorLoop33Resistance 4860;
BA_ "SAEDocument" SG_ 2633832958 SpecialIgnitorLoop33Resistance "J1939-71";
BA_ "SigType" SG_ 2633832958 SpecialIgnitorLoop32Resistance 1;
BA_ "SPN" SG_ 2633832958 SpecialIgnitorLoop32Resistance 4859;
BA_ "SAEDocument" SG_ 2633832958 SpecialIgnitorLoop32Resistance "J1939-71";
BA_ "SigType" SG_ 2633832958 SpecialIgnitorLoop31Resistance 1;
BA_ "SPN" SG_ 2633832958 SpecialIgnitorLoop31Resistance 4858;
BA_ "SAEDocument" SG_ 2633832958 SpecialIgnitorLoop31Resistance "J1939-71";
BA_ "SigType" SG_ 2633832958 SpecialIgnitorLoop30Resistance 1;
BA_ "SPN" SG_ 2633832958 SpecialIgnitorLoop30Resistance 4857;
BA_ "SAEDocument" SG_ 2633832958 SpecialIgnitorLoop30Resistance "J1939-71";
BA_ "SigType" SG_ 2633832958 SpecialIgnitorLoop29Resistance 1;
BA_ "SPN" SG_ 2633832958 SpecialIgnitorLoop29Resistance 4856;
BA_ "SAEDocument" SG_ 2633832958 SpecialIgnitorLoop29Resistance "J1939-71";
BA_ "SigType" SG_ 2633832958 SpecialIgnitorLoop28Resistance 1;
BA_ "SPN" SG_ 2633832958 SpecialIgnitorLoop28Resistance 4855;
BA_ "SAEDocument" SG_ 2633832958 SpecialIgnitorLoop28Resistance "J1939-71";
BA_ "SigType" SG_ 2633832958 SpecialIgnitorLoop27Resistance 1;
BA_ "SPN" SG_ 2633832958 SpecialIgnitorLoop27Resistance 4854;
BA_ "SAEDocument" SG_ 2633832958 SpecialIgnitorLoop27Resistance "J1939-71";
BA_ "SigType" SG_ 2633832958 SpecialIgnitorLoop26Resistance 1;
BA_ "SPN" SG_ 2633832958 SpecialIgnitorLoop26Resistance 4853;
BA_ "SAEDocument" SG_ 2633832958 SpecialIgnitorLoop26Resistance "J1939-71";
BA_ "SigType" SG_ 2633832958 SpecialIgnitorLoop25Resistance 1;
BA_ "SPN" SG_ 2633832958 SpecialIgnitorLoop25Resistance 4852;
BA_ "SAEDocument" SG_ 2633832958 SpecialIgnitorLoop25Resistance "J1939-71";
BA_ "SigType" SG_ 2633832958 SpecialIgnitorLoop24Resistance 1;
BA_ "SPN" SG_ 2633832958 SpecialIgnitorLoop24Resistance 4851;
BA_ "SAEDocument" SG_ 2633832958 SpecialIgnitorLoop24Resistance "J1939-71";
BA_ "SigType" SG_ 2633832958 SpecialIgnitorLoop23Resistance 1;
BA_ "SPN" SG_ 2633832958 SpecialIgnitorLoop23Resistance 4850;
BA_ "SAEDocument" SG_ 2633832958 SpecialIgnitorLoop23Resistance "J1939-71";
BA_ "SigType" SG_ 2633832958 SpecialIgnitorLoop22Resistance 1;
BA_ "SPN" SG_ 2633832958 SpecialIgnitorLoop22Resistance 4849;
BA_ "SAEDocument" SG_ 2633832958 SpecialIgnitorLoop22Resistance "J1939-71";
BA_ "SigType" SG_ 2633832958 SpecialIgnitorLoop21Resistance 1;
BA_ "SPN" SG_ 2633832958 SpecialIgnitorLoop21Resistance 4848;
BA_ "SAEDocument" SG_ 2633832958 SpecialIgnitorLoop21Resistance "J1939-71";
BA_ "SigType" SG_ 2633832958 SpecialIgnitorLoop20Resistance 1;
BA_ "SPN" SG_ 2633832958 SpecialIgnitorLoop20Resistance 4847;
BA_ "SAEDocument" SG_ 2633832958 SpecialIgnitorLoop20Resistance "J1939-71";
BA_ "SigType" SG_ 2633832958 SpecialIgnitorLoop19Resistance 1;
BA_ "SPN" SG_ 2633832958 SpecialIgnitorLoop19Resistance 4846;
BA_ "SAEDocument" SG_ 2633832958 SpecialIgnitorLoop19Resistance "J1939-71";
BA_ "SigType" SG_ 2633832958 SpecialIgnitorLoop18Resistance 1;
BA_ "SPN" SG_ 2633832958 SpecialIgnitorLoop18Resistance 4845;
BA_ "SAEDocument" SG_ 2633832958 SpecialIgnitorLoop18Resistance "J1939-71";
BA_ "SigType" SG_ 2633832958 SpecialIgnitorLoop17Resistance 1;
BA_ "SPN" SG_ 2633832958 SpecialIgnitorLoop17Resistance 4844;
BA_ "SAEDocument" SG_ 2633832958 SpecialIgnitorLoop17Resistance "J1939-71";
BA_ "SigType" SG_ 2633832958 SpecialIgnitorLoop16Resistance 1;
BA_ "SPN" SG_ 2633832958 SpecialIgnitorLoop16Resistance 4843;
BA_ "SAEDocument" SG_ 2633832958 SpecialIgnitorLoop16Resistance "J1939-71";
BA_ "SigType" SG_ 2633832958 SpecialIgnitorLoop15Resistance 1;
BA_ "SPN" SG_ 2633832958 SpecialIgnitorLoop15Resistance 4842;
BA_ "SAEDocument" SG_ 2633832958 SpecialIgnitorLoop15Resistance "J1939-71";
BA_ "SigType" SG_ 2633832958 SpecialIgnitorLoop14Resistance 1;
BA_ "SPN" SG_ 2633832958 SpecialIgnitorLoop14Resistance 4841;
BA_ "SAEDocument" SG_ 2633832958 SpecialIgnitorLoop14Resistance "J1939-71";
BA_ "SigType" SG_ 2633832958 SpecialIgnitorLoop13Resistance 1;
BA_ "SPN" SG_ 2633832958 SpecialIgnitorLoop13Resistance 4840;
BA_ "SAEDocument" SG_ 2633832958 SpecialIgnitorLoop13Resistance "J1939-71";
BA_ "SigType" SG_ 2633832958 SpecialIgnitorLoop12Resistance 1;
BA_ "SPN" SG_ 2633832958 SpecialIgnitorLoop12Resistance 4839;
BA_ "SAEDocument" SG_ 2633832958 SpecialIgnitorLoop12Resistance "J1939-71";
BA_ "SigType" SG_ 2633832958 SpecialIgnitorLoop11Resistance 1;
BA_ "SPN" SG_ 2633832958 SpecialIgnitorLoop11Resistance 4838;
BA_ "SAEDocument" SG_ 2633832958 SpecialIgnitorLoop11Resistance "J1939-71";
BA_ "SigType" SG_ 2633832958 SpecialIgnitorLoop10Resistance 1;
BA_ "SPN" SG_ 2633832958 SpecialIgnitorLoop10Resistance 4837;
BA_ "SAEDocument" SG_ 2633832958 SpecialIgnitorLoop10Resistance "J1939-71";
BA_ "SigType" SG_ 2633832958 SpecialIgnitorLoop9Resistance 1;
BA_ "SPN" SG_ 2633832958 SpecialIgnitorLoop9Resistance 4836;
BA_ "SAEDocument" SG_ 2633832958 SpecialIgnitorLoop9Resistance "J1939-71";
BA_ "SigType" SG_ 2633832958 SpecialIgnitorLoop8Resistance 1;
BA_ "SPN" SG_ 2633832958 SpecialIgnitorLoop8Resistance 4835;
BA_ "SAEDocument" SG_ 2633832958 SpecialIgnitorLoop8Resistance "J1939-71";
BA_ "SigType" SG_ 2633832958 SpecialIgnitorLoop7Resistance 1;
BA_ "SPN" SG_ 2633832958 SpecialIgnitorLoop7Resistance 4834;
BA_ "SAEDocument" SG_ 2633832958 SpecialIgnitorLoop7Resistance "J1939-71";
BA_ "SigType" SG_ 2633832958 SpecialIgnitorLoop6Resistance 1;
BA_ "SPN" SG_ 2633832958 SpecialIgnitorLoop6Resistance 4833;
BA_ "SAEDocument" SG_ 2633832958 SpecialIgnitorLoop6Resistance "J1939-71";
BA_ "SigType" SG_ 2633832958 SpecialIgnitorLoop5Resistance 1;
BA_ "SPN" SG_ 2633832958 SpecialIgnitorLoop5Resistance 4832;
BA_ "SAEDocument" SG_ 2633832958 SpecialIgnitorLoop5Resistance "J1939-71";
BA_ "SigType" SG_ 2633832958 SpecialIgnitorLoop4Resistance 1;
BA_ "SPN" SG_ 2633832958 SpecialIgnitorLoop4Resistance 4831;
BA_ "SAEDocument" SG_ 2633832958 SpecialIgnitorLoop4Resistance "J1939-71";
BA_ "SigType" SG_ 2633832958 SpecialIgnitorLoop3Resistance 1;
BA_ "SPN" SG_ 2633832958 SpecialIgnitorLoop3Resistance 4830;
BA_ "SAEDocument" SG_ 2633832958 SpecialIgnitorLoop3Resistance "J1939-71";
BA_ "SigType" SG_ 2633832958 SpecialIgnitorLoop2Resistance 1;
BA_ "SPN" SG_ 2633832958 SpecialIgnitorLoop2Resistance 4829;
BA_ "SAEDocument" SG_ 2633832958 SpecialIgnitorLoop2Resistance "J1939-71";
BA_ "SigType" SG_ 2633832958 SpecialIgnitorLoop1Resistance 1;
BA_ "SPN" SG_ 2633832958 SpecialIgnitorLoop1Resistance 4828;
BA_ "SAEDocument" SG_ 2633832958 SpecialIgnitorLoop1Resistance "J1939-71";
BA_ "SigType" SG_ 2633832958 SdBagIgnitorLoop2RightResistance 1;
BA_ "SPN" SG_ 2633832958 SdBagIgnitorLoop2RightResistance 4827;
BA_ "SAEDocument" SG_ 2633832958 SdBagIgnitorLoop2RightResistance "J1939-71";
BA_ "SigType" SG_ 2633832958 SdBagIgnitorLoop1RightResistance 1;
BA_ "SPN" SG_ 2633832958 SdBagIgnitorLoop1RightResistance 4826;
BA_ "SAEDocument" SG_ 2633832958 SdBagIgnitorLoop1RightResistance "J1939-71";
BA_ "SigType" SG_ 2633832958 SdeBagIgnitorLoop2LeftResistance 1;
BA_ "SPN" SG_ 2633832958 SdeBagIgnitorLoop2LeftResistance 4825;
BA_ "SAEDocument" SG_ 2633832958 SdeBagIgnitorLoop2LeftResistance "J1939-71";
BA_ "SigType" SG_ 2633832958 SdeBagIgnitorLoop1LeftResistance 1;
BA_ "SPN" SG_ 2633832958 SdeBagIgnitorLoop1LeftResistance 4824;
BA_ "SAEDocument" SG_ 2633832958 SdeBagIgnitorLoop1LeftResistance "J1939-71";
BA_ "SigType" SG_ 2633832958 PssngrBltTnsnrIgntrLopResistance 1;
BA_ "SPN" SG_ 2633832958 PssngrBltTnsnrIgntrLopResistance 4823;
BA_ "SAEDocument" SG_ 2633832958 PssngrBltTnsnrIgntrLopResistance "J1939-71";
BA_ "SigType" SG_ 2633832958 DrvrBltTnsnrIgntorLoopResistance 1;
BA_ "SPN" SG_ 2633832958 DrvrBltTnsnrIgntorLoopResistance 4822;
BA_ "SAEDocument" SG_ 2633832958 DrvrBltTnsnrIgntorLoopResistance "J1939-71";
BA_ "SigType" SG_ 2633832958 PssngrArbgIgntrLp2ndStgRsistance 1;
BA_ "SPN" SG_ 2633832958 PssngrArbgIgntrLp2ndStgRsistance 4821;
BA_ "SAEDocument" SG_ 2633832958 PssngrArbgIgntrLp2ndStgRsistance "J1939-71";
BA_ "SigType" SG_ 2633832958 DrvrArbgIgntrLp2ndStgeResistance 1;
BA_ "SPN" SG_ 2633832958 DrvrArbgIgntrLp2ndStgeResistance 4820;
BA_ "SAEDocument" SG_ 2633832958 DrvrArbgIgntrLp2ndStgeResistance "J1939-71";
BA_ "SigType" SG_ 2633832958 PssngrArbgIgntrLp1stStgRsistance 1;
BA_ "SPN" SG_ 2633832958 PssngrArbgIgntrLp1stStgRsistance 4819;
BA_ "SAEDocument" SG_ 2633832958 PssngrArbgIgntrLp1stStgRsistance "J1939-71";
BA_ "SigType" SG_ 2633832958 DrvrArbgIgntrLp1stStgeResistance 1;
BA_ "SPN" SG_ 2633832958 DrvrArbgIgntrLp1stStgeResistance 4818;
BA_ "SAEDocument" SG_ 2633832958 DrvrArbgIgntrLp1stStgeResistance "J1939-71";
BA_ "SigType" SG_ 2566719998 HighResolutionEngTotalFuelUsed 1;
BA_ "SPN" SG_ 2566719998 HighResolutionEngTotalFuelUsed 5054;
BA_ "SAEDocument" SG_ 2566719998 HighResolutionEngTotalFuelUsed "J1939-71";
BA_ "SigType" SG_ 2566719998 HighResolutionEngTripFuel 1;
BA_ "SPN" SG_ 2566719998 HighResolutionEngTripFuel 5053;
BA_ "SAEDocument" SG_ 2566719998 HighResolutionEngTripFuel "J1939-71";
BA_ "SPN" SG_ 2565877502 EngTurboWastegateActuator2Cmd 5387;
BA_ "SAEDocument" SG_ 2565877502 EngTurboWastegateActuator2Cmd "J1939-71";
BA_ "SPN" SG_ 2565877502 EngTurboWastegateActuator1Cmd 5386;
BA_ "SAEDocument" SG_ 2565877502 EngTurboWastegateActuator1Cmd "J1939-71";
BA_ "SPN" SG_ 2566713854 EngTrbWstgtActtr2OperationStatus 5452;
BA_ "SAEDocument" SG_ 2566713854 EngTrbWstgtActtr2OperationStatus "J1939-71";
BA_ "SPN" SG_ 2566713854 EngTrbWstgtActtr1OperationStatus 5451;
BA_ "SAEDocument" SG_ 2566713854 EngTrbWstgtActtr1OperationStatus "J1939-71";
BA_ "SPN" SG_ 2566713854 EngTrbWstgateActuator2TempStatus 5385;
BA_ "SAEDocument" SG_ 2566713854 EngTrbWstgateActuator2TempStatus "J1939-71";
BA_ "SPN" SG_ 2566713854 EngTrbWstgtActtor2PreliminaryFMI 5384;
BA_ "SAEDocument" SG_ 2566713854 EngTrbWstgtActtor2PreliminaryFMI "J1939-71";
BA_ "SPN" SG_ 2566714366 EngTrbCmprssrBypssActtr2OprtnStt 5450;
BA_ "SAEDocument" SG_ 2566714366 EngTrbCmprssrBypssActtr2OprtnStt "J1939-71";
BA_ "SPN" SG_ 2566714366 EngTrbCmprssrBypssActtr1OprtnStt 5449;
BA_ "SAEDocument" SG_ 2566714366 EngTrbCmprssrBypssActtr1OprtnStt "J1939-71";
BA_ "SPN" SG_ 2566714366 EngTrbCmprssrBypssActtr2TmpSttus 5391;
BA_ "SAEDocument" SG_ 2566714366 EngTrbCmprssrBypssActtr2TmpSttus "J1939-71";
BA_ "SPN" SG_ 2566714366 EngTrbCmprssrBypssActtr2PrlmnryF 5390;
BA_ "SAEDocument" SG_ 2566714366 EngTrbCmprssrBypssActtr2PrlmnryF "J1939-71";
BA_ "SPN" SG_ 2566714366 EngDsrdTrbCmprssrBypssActtor2Pos 5389;
BA_ "SAEDocument" SG_ 2566714366 EngDsrdTrbCmprssrBypssActtor2Pos "J1939-71";
BA_ "SigType" SG_ 2566714366 EngTrbCmprssorBypassActuator2Pos 1;
BA_ "SPN" SG_ 2566714366 EngTrbCmprssorBypassActuator2Pos 5388;
BA_ "SAEDocument" SG_ 2566714366 EngTrbCmprssorBypassActuator2Pos "J1939-71";
BA_ "SPN" SG_ 2566714110 EngFuelValve2OperationStatus 5448;
BA_ "SAEDocument" SG_ 2566714110 EngFuelValve2OperationStatus "J1939-71";
BA_ "SPN" SG_ 2566714110 EngFuelValve1OperationStatus 5447;
BA_ "SAEDocument" SG_ 2566714110 EngFuelValve1OperationStatus "J1939-71";
BA_ "SPN" SG_ 2566714110 EngThrottleValve2OperationStatus 5446;
BA_ "SAEDocument" SG_ 2566714110 EngThrottleValve2OperationStatus "J1939-71";
BA_ "SPN" SG_ 2566714110 EngThrottleValve1OperationStatus 5445;
BA_ "SAEDocument" SG_ 2566714110 EngThrottleValve1OperationStatus "J1939-71";
BA_ "SPN" SG_ 2566714110 EngFuelValve2TempStatus 5383;
BA_ "SAEDocument" SG_ 2566714110 EngFuelValve2TempStatus "J1939-71";
BA_ "SPN" SG_ 2566714110 EngFuelValve2PreliminaryFMI 5382;
BA_ "SAEDocument" SG_ 2566714110 EngFuelValve2PreliminaryFMI "J1939-71";
BA_ "SPN" SG_ 2566714110 EngFuelValve1TempStatus 5381;
BA_ "SAEDocument" SG_ 2566714110 EngFuelValve1TempStatus "J1939-71";
BA_ "SPN" SG_ 2566714110 EngFuelValve1PreliminaryFMI 5380;
BA_ "SAEDocument" SG_ 2566714110 EngFuelValve1PreliminaryFMI "J1939-71";
BA_ "SPN" SG_ 2566714110 EngThrottleValve2TempStatus 5379;
BA_ "SAEDocument" SG_ 2566714110 EngThrottleValve2TempStatus "J1939-71";
BA_ "SPN" SG_ 2566714110 EngThrottleValve2PreliminaryFMI 5378;
BA_ "SAEDocument" SG_ 2566714110 EngThrottleValve2PreliminaryFMI "J1939-71";
BA_ "SPN" SG_ 2566714110 EngDesiredThrottleValve2Pos 5377;
BA_ "SAEDocument" SG_ 2566714110 EngDesiredThrottleValve2Pos "J1939-71";
BA_ "SPN" SG_ 2566714110 EngThrottleValve1TempStatus 5376;
BA_ "SAEDocument" SG_ 2566714110 EngThrottleValve1TempStatus "J1939-71";
BA_ "SPN" SG_ 2566714110 EngThrottleValve1PreliminaryFMI 5375;
BA_ "SAEDocument" SG_ 2566714110 EngThrottleValve1PreliminaryFMI "J1939-71";
BA_ "SPN" SG_ 2566714110 EngDesiredThrottleValve1Pos 5374;
BA_ "SAEDocument" SG_ 2566714110 EngDesiredThrottleValve1Pos "J1939-71";
BA_ "SigType" SG_ 2566717438 EngExhstGsRcrcltn2MxerIntakeTemp 1;
BA_ "SPN" SG_ 2566717438 EngExhstGsRcrcltn2MxerIntakeTemp 5256;
BA_ "SAEDocument" SG_ 2566717438 EngExhstGsRcrcltn2MxerIntakeTemp "J1939-71";
BA_ "SigType" SG_ 2566717438 EngExhaustGasRecirculation2Temp 1;
BA_ "SPN" SG_ 2566717438 EngExhaustGasRecirculation2Temp 5255;
BA_ "SAEDocument" SG_ 2566717438 EngExhaustGasRecirculation2Temp "J1939-71";
BA_ "SigType" SG_ 2633828606 EngOilRelativeDielectricity 1;
BA_ "SPN" SG_ 2633828606 EngOilRelativeDielectricity 5468;
BA_ "SAEDocument" SG_ 2633828606 EngOilRelativeDielectricity "J1939-71";
BA_ "SigType" SG_ 2633828606 EngOilDensity 1;
BA_ "SPN" SG_ 2633828606 EngOilDensity 5056;
BA_ "SAEDocument" SG_ 2633828606 EngOilDensity "J1939-71";
BA_ "SigType" SG_ 2633828606 EngOilViscosity 1;
BA_ "SPN" SG_ 2633828606 EngOilViscosity 5055;
BA_ "SAEDocument" SG_ 2633828606 EngOilViscosity "J1939-71";
BA_ "SigType" SG_ 2499607550 EngExhstMnfldBnk2FlwBlncVlvActtr 1;
BA_ "SPN" SG_ 2499607550 EngExhstMnfldBnk2FlwBlncVlvActtr 5279;
BA_ "SAEDocument" SG_ 2499607550 EngExhstMnfldBnk2FlwBlncVlvActtr "J1939-71";
BA_ "SigType" SG_ 2499607550 EngExhstMnfldBnk1FlwBlncVlvActtr 1;
BA_ "SPN" SG_ 2499607550 EngExhstMnfldBnk1FlwBlncVlvActtr 5277;
BA_ "SAEDocument" SG_ 2499607550 EngExhstMnfldBnk1FlwBlncVlvActtr "J1939-71";
BA_ "SPN" SG_ 2633825534 EngExhstMnfldBnk2FlwBlncVlvActtr 5278;
BA_ "SAEDocument" SG_ 2633825534 EngExhstMnfldBnk2FlwBlncVlvActtr "J1939-71";
BA_ "SPN" SG_ 2633825534 EngExhstMnfldBnk1FlwBlncVlvActtr 5276;
BA_ "SAEDocument" SG_ 2633825534 EngExhstMnfldBnk1FlwBlncVlvActtr "J1939-71";
BA_ "SigType" SG_ 2365400574 Jystick9GripXAxisDetentPosStatus 4;
BA_ "SPN" SG_ 2365400574 Jystick9GripXAxisDetentPosStatus 4712;
BA_ "SAEDocument" SG_ 2365400574 Jystick9GripXAxisDetentPosStatus "J1939-71";
BA_ "SigType" SG_ 2365400574 Jystick9GripYAxisDetentPosStatus 4;
BA_ "SPN" SG_ 2365400574 Jystick9GripYAxisDetentPosStatus 4711;
BA_ "SAEDocument" SG_ 2365400574 Jystick9GripYAxisDetentPosStatus "J1939-71";
BA_ "SigType" SG_ 2365400574 Jystick9ThetaAxisDetentPosStatus 4;
BA_ "SPN" SG_ 2365400574 Jystick9ThetaAxisDetentPosStatus 4710;
BA_ "SAEDocument" SG_ 2365400574 Jystick9ThetaAxisDetentPosStatus "J1939-71";
BA_ "SPN" SG_ 2365400574 Joystick9ThetaAxisPos 4709;
BA_ "SAEDocument" SG_ 2365400574 Joystick9ThetaAxisPos "J1939-71";
BA_ "SigType" SG_ 2365400574 Jystck9ThtAxsClckwsPstvPosStatus 4;
BA_ "SPN" SG_ 2365400574 Jystck9ThtAxsClckwsPstvPosStatus 4708;
BA_ "SAEDocument" SG_ 2365400574 Jystck9ThtAxsClckwsPstvPosStatus "J1939-71";
BA_ "SigType" SG_ 2365400574 Jystck9ThtAxsCntrClckwsNgtvPsStt 4;
BA_ "SPN" SG_ 2365400574 Jystck9ThtAxsCntrClckwsNgtvPsStt 4707;
BA_ "SAEDocument" SG_ 2365400574 Jystck9ThtAxsCntrClckwsNgtvPsStt "J1939-71";
BA_ "SigType" SG_ 2365400574 Jystck9ThetaAxisNeutralPosStatus 4;
BA_ "SPN" SG_ 2365400574 Jystck9ThetaAxisNeutralPosStatus 4706;
BA_ "SAEDocument" SG_ 2365400574 Jystck9ThetaAxisNeutralPosStatus "J1939-71";
BA_ "SPN" SG_ 2365400574 Joystick9GripYAxisPos 4705;
BA_ "SAEDocument" SG_ 2365400574 Joystick9GripYAxisPos "J1939-71";
BA_ "SigType" SG_ 2365400574 Jystck9GrpYAxsLvrFrwrdPstvPsStts 4;
BA_ "SPN" SG_ 2365400574 Jystck9GrpYAxsLvrFrwrdPstvPsStts 4704;
BA_ "SAEDocument" SG_ 2365400574 Jystck9GrpYAxsLvrFrwrdPstvPsStts "J1939-71";
BA_ "SigType" SG_ 2365400574 Jystck9GrpYAxsLvrBckNgtvPsStatus 4;
BA_ "SPN" SG_ 2365400574 Jystck9GrpYAxsLvrBckNgtvPsStatus 4703;
BA_ "SAEDocument" SG_ 2365400574 Jystck9GrpYAxsLvrBckNgtvPsStatus "J1939-71";
BA_ "SigType" SG_ 2365400574 Jystck9GripYAxisNeutralPosStatus 4;
BA_ "SPN" SG_ 2365400574 Jystck9GripYAxisNeutralPosStatus 4702;
BA_ "SAEDocument" SG_ 2365400574 Jystck9GripYAxisNeutralPosStatus "J1939-71";
BA_ "SPN" SG_ 2365400574 Joystick9GripXAxisPos 4701;
BA_ "SAEDocument" SG_ 2365400574 Joystick9GripXAxisPos "J1939-71";
BA_ "SigType" SG_ 2365400574 Jystck9GrpXAxsLvrRghtPstvPsSttus 4;
BA_ "SPN" SG_ 2365400574 Jystck9GrpXAxsLvrRghtPstvPsSttus 4700;
BA_ "SAEDocument" SG_ 2365400574 Jystck9GrpXAxsLvrRghtPstvPsSttus "J1939-71";
BA_ "SigType" SG_ 2365400574 Jystck9GrpXAxsLvrLftNgtvPsStatus 4;
BA_ "SPN" SG_ 2365400574 Jystck9GrpXAxsLvrLftNgtvPsStatus 4699;
BA_ "SAEDocument" SG_ 2365400574 Jystck9GrpXAxsLvrLftNgtvPsStatus "J1939-71";
BA_ "SigType" SG_ 2365400574 Jystck9GripXAxisNeutralPosStatus 4;
BA_ "SPN" SG_ 2365400574 Jystck9GripXAxisNeutralPosStatus 4698;
BA_ "SAEDocument" SG_ 2365400574 Jystck9GripXAxisNeutralPosStatus "J1939-71";
BA_ "SigType" SG_ 2365401086 Jystick8GripXAxisDetentPosStatus 4;
BA_ "SPN" SG_ 2365401086 Jystick8GripXAxisDetentPosStatus 4675;
BA_ "SAEDocument" SG_ 2365401086 Jystick8GripXAxisDetentPosStatus "J1939-71";
BA_ "SigType" SG_ 2365401086 Jystick8GripYAxisDetentPosStatus 4;
BA_ "SPN" SG_ 2365401086 Jystick8GripYAxisDetentPosStatus 4674;
BA_ "SAEDocument" SG_ 2365401086 Jystick8GripYAxisDetentPosStatus "J1939-71";
BA_ "SigType" SG_ 2365401086 Jystick8ThetaAxisDetentPosStatus 4;
BA_ "SPN" SG_ 2365401086 Jystick8ThetaAxisDetentPosStatus 4673;
BA_ "SAEDocument" SG_ 2365401086 Jystick8ThetaAxisDetentPosStatus "J1939-71";
BA_ "SPN" SG_ 2365401086 Joystick8ThetaAxisPos 4672;
BA_ "SAEDocument" SG_ 2365401086 Joystick8ThetaAxisPos "J1939-71";
BA_ "SigType" SG_ 2365401086 Jystck8ThtAxsClckwsPstvPosStatus 4;
BA_ "SPN" SG_ 2365401086 Jystck8ThtAxsClckwsPstvPosStatus 4671;
BA_ "SAEDocument" SG_ 2365401086 Jystck8ThtAxsClckwsPstvPosStatus "J1939-71";
BA_ "SigType" SG_ 2365401086 Jystck8ThtAxsCntrClckwsNgtvPsStt 4;
BA_ "SPN" SG_ 2365401086 Jystck8ThtAxsCntrClckwsNgtvPsStt 4670;
BA_ "SAEDocument" SG_ 2365401086 Jystck8ThtAxsCntrClckwsNgtvPsStt "J1939-71";
BA_ "SigType" SG_ 2365401086 Jystck8ThetaAxisNeutralPosStatus 4;
BA_ "SPN" SG_ 2365401086 Jystck8ThetaAxisNeutralPosStatus 4669;
BA_ "SAEDocument" SG_ 2365401086 Jystck8ThetaAxisNeutralPosStatus "J1939-71";
BA_ "SPN" SG_ 2365401086 Joystick8GripYAxisPos 4668;
BA_ "SAEDocument" SG_ 2365401086 Joystick8GripYAxisPos "J1939-71";
BA_ "SigType" SG_ 2365401086 Jystck8GrpYAxsLvrFrwrdPstvPsStts 4;
BA_ "SPN" SG_ 2365401086 Jystck8GrpYAxsLvrFrwrdPstvPsStts 4667;
BA_ "SAEDocument" SG_ 2365401086 Jystck8GrpYAxsLvrFrwrdPstvPsStts "J1939-71";
BA_ "SigType" SG_ 2365401086 Jystck8GrpYAxsLvrBckNgtvPsStatus 4;
BA_ "SPN" SG_ 2365401086 Jystck8GrpYAxsLvrBckNgtvPsStatus 4666;
BA_ "SAEDocument" SG_ 2365401086 Jystck8GrpYAxsLvrBckNgtvPsStatus "J1939-71";
BA_ "SigType" SG_ 2365401086 Jystck8GripYAxisNeutralPosStatus 4;
BA_ "SPN" SG_ 2365401086 Jystck8GripYAxisNeutralPosStatus 4665;
BA_ "SAEDocument" SG_ 2365401086 Jystck8GripYAxisNeutralPosStatus "J1939-71";
BA_ "SPN" SG_ 2365401086 Joystick8GripXAxisPos 4664;
BA_ "SAEDocument" SG_ 2365401086 Joystick8GripXAxisPos "J1939-71";
BA_ "SigType" SG_ 2365401086 Jystck8GrpXAxsLvrRghtPstvPsSttus 4;
BA_ "SPN" SG_ 2365401086 Jystck8GrpXAxsLvrRghtPstvPsSttus 4663;
BA_ "SAEDocument" SG_ 2365401086 Jystck8GrpXAxsLvrRghtPstvPsSttus "J1939-71";
BA_ "SigType" SG_ 2365401086 Jystck8GrpXAxsLvrLftNgtvPsStatus 4;
BA_ "SPN" SG_ 2365401086 Jystck8GrpXAxsLvrLftNgtvPsStatus 4662;
BA_ "SAEDocument" SG_ 2365401086 Jystck8GrpXAxsLvrLftNgtvPsStatus "J1939-71";
BA_ "SigType" SG_ 2365401086 Jystck8GripXAxisNeutralPosStatus 4;
BA_ "SPN" SG_ 2365401086 Jystck8GripXAxisNeutralPosStatus 4661;
BA_ "SAEDocument" SG_ 2365401086 Jystck8GripXAxisNeutralPosStatus "J1939-71";
BA_ "SigType" SG_ 2365401598 Jystick7GripXAxisDetentPosStatus 4;
BA_ "SPN" SG_ 2365401598 Jystick7GripXAxisDetentPosStatus 4638;
BA_ "SAEDocument" SG_ 2365401598 Jystick7GripXAxisDetentPosStatus "J1939-71";
BA_ "SigType" SG_ 2365401598 Jystick7GripYAxisDetentPosStatus 4;
BA_ "SPN" SG_ 2365401598 Jystick7GripYAxisDetentPosStatus 4637;
BA_ "SAEDocument" SG_ 2365401598 Jystick7GripYAxisDetentPosStatus "J1939-71";
BA_ "SigType" SG_ 2365401598 Jystick7ThetaAxisDetentPosStatus 4;
BA_ "SPN" SG_ 2365401598 Jystick7ThetaAxisDetentPosStatus 4636;
BA_ "SAEDocument" SG_ 2365401598 Jystick7ThetaAxisDetentPosStatus "J1939-71";
BA_ "SPN" SG_ 2365401598 Joystick7ThetaAxisPos 4635;
BA_ "SAEDocument" SG_ 2365401598 Joystick7ThetaAxisPos "J1939-71";
BA_ "SigType" SG_ 2365401598 Jystck7ThtAxsClckwsPstvPosStatus 4;
BA_ "SPN" SG_ 2365401598 Jystck7ThtAxsClckwsPstvPosStatus 4634;
BA_ "SAEDocument" SG_ 2365401598 Jystck7ThtAxsClckwsPstvPosStatus "J1939-71";
BA_ "SigType" SG_ 2365401598 Jystck7ThtAxsCntrClckwsNgtvPsStt 4;
BA_ "SPN" SG_ 2365401598 Jystck7ThtAxsCntrClckwsNgtvPsStt 4633;
BA_ "SAEDocument" SG_ 2365401598 Jystck7ThtAxsCntrClckwsNgtvPsStt "J1939-71";
BA_ "SigType" SG_ 2365401598 Jystck7ThetaAxisNeutralPosStatus 4;
BA_ "SPN" SG_ 2365401598 Jystck7ThetaAxisNeutralPosStatus 4632;
BA_ "SAEDocument" SG_ 2365401598 Jystck7ThetaAxisNeutralPosStatus "J1939-71";
BA_ "SPN" SG_ 2365401598 Joystick7GripYAxisPos 4631;
BA_ "SAEDocument" SG_ 2365401598 Joystick7GripYAxisPos "J1939-71";
BA_ "SigType" SG_ 2365401598 Jystck7GrpYAxsLvrFrwrdPstvPsStts 4;
BA_ "SPN" SG_ 2365401598 Jystck7GrpYAxsLvrFrwrdPstvPsStts 4630;
BA_ "SAEDocument" SG_ 2365401598 Jystck7GrpYAxsLvrFrwrdPstvPsStts "J1939-71";
BA_ "SigType" SG_ 2365401598 Jystck7GrpYAxsLvrBckNgtvPsStatus 4;
BA_ "SPN" SG_ 2365401598 Jystck7GrpYAxsLvrBckNgtvPsStatus 4629;
BA_ "SAEDocument" SG_ 2365401598 Jystck7GrpYAxsLvrBckNgtvPsStatus "J1939-71";
BA_ "SigType" SG_ 2365401598 Jystck7GripYAxisNeutralPosStatus 4;
BA_ "SPN" SG_ 2365401598 Jystck7GripYAxisNeutralPosStatus 4628;
BA_ "SAEDocument" SG_ 2365401598 Jystck7GripYAxisNeutralPosStatus "J1939-71";
BA_ "SPN" SG_ 2365401598 Joystick7GripXAxisPos 4627;
BA_ "SAEDocument" SG_ 2365401598 Joystick7GripXAxisPos "J1939-71";
BA_ "SigType" SG_ 2365401598 Jystck7GrpXAxsLvrRghtPstvPsSttus 4;
BA_ "SPN" SG_ 2365401598 Jystck7GrpXAxsLvrRghtPstvPsSttus 4626;
BA_ "SAEDocument" SG_ 2365401598 Jystck7GrpXAxsLvrRghtPstvPsSttus "J1939-71";
BA_ "SigType" SG_ 2365401598 Jystck7GrpXAxsLvrLftNgtvPsStatus 4;
BA_ "SPN" SG_ 2365401598 Jystck7GrpXAxsLvrLftNgtvPsStatus 4625;
BA_ "SAEDocument" SG_ 2365401598 Jystck7GrpXAxsLvrLftNgtvPsStatus "J1939-71";
BA_ "SigType" SG_ 2365401598 Jystck7GripXAxisNeutralPosStatus 4;
BA_ "SPN" SG_ 2365401598 Jystck7GripXAxisNeutralPosStatus 4624;
BA_ "SAEDocument" SG_ 2365401598 Jystck7GripXAxisNeutralPosStatus "J1939-71";
BA_ "SigType" SG_ 2365402110 Jystick6GripXAxisDetentPosStatus 4;
BA_ "SPN" SG_ 2365402110 Jystick6GripXAxisDetentPosStatus 4601;
BA_ "SAEDocument" SG_ 2365402110 Jystick6GripXAxisDetentPosStatus "J1939-71";
BA_ "SigType" SG_ 2365402110 Jystick6GripYAxisDetentPosStatus 4;
BA_ "SPN" SG_ 2365402110 Jystick6GripYAxisDetentPosStatus 4600;
BA_ "SAEDocument" SG_ 2365402110 Jystick6GripYAxisDetentPosStatus "J1939-71";
BA_ "SigType" SG_ 2365402110 Jystick6ThetaAxisDetentPosStatus 4;
BA_ "SPN" SG_ 2365402110 Jystick6ThetaAxisDetentPosStatus 4599;
BA_ "SAEDocument" SG_ 2365402110 Jystick6ThetaAxisDetentPosStatus "J1939-71";
BA_ "SPN" SG_ 2365402110 Joystick6ThetaAxisPos 4598;
BA_ "SAEDocument" SG_ 2365402110 Joystick6ThetaAxisPos "J1939-71";
BA_ "SigType" SG_ 2365402110 Jystck6ThtAxsClckwsPstvPosStatus 4;
BA_ "SPN" SG_ 2365402110 Jystck6ThtAxsClckwsPstvPosStatus 4597;
BA_ "SAEDocument" SG_ 2365402110 Jystck6ThtAxsClckwsPstvPosStatus "J1939-71";
BA_ "SigType" SG_ 2365402110 Jystck6ThtAxsCntrClckwsNgtvPsStt 4;
BA_ "SPN" SG_ 2365402110 Jystck6ThtAxsCntrClckwsNgtvPsStt 4596;
BA_ "SAEDocument" SG_ 2365402110 Jystck6ThtAxsCntrClckwsNgtvPsStt "J1939-71";
BA_ "SigType" SG_ 2365402110 Jystck6ThetaAxisNeutralPosStatus 4;
BA_ "SPN" SG_ 2365402110 Jystck6ThetaAxisNeutralPosStatus 4595;
BA_ "SAEDocument" SG_ 2365402110 Jystck6ThetaAxisNeutralPosStatus "J1939-71";
BA_ "SPN" SG_ 2365402110 Joystick6GripYAxisPos 4594;
BA_ "SAEDocument" SG_ 2365402110 Joystick6GripYAxisPos "J1939-71";
BA_ "SigType" SG_ 2365402110 Jystck6GrpYAxsLvrFrwrdPstvPsStts 4;
BA_ "SPN" SG_ 2365402110 Jystck6GrpYAxsLvrFrwrdPstvPsStts 4593;
BA_ "SAEDocument" SG_ 2365402110 Jystck6GrpYAxsLvrFrwrdPstvPsStts "J1939-71";
BA_ "SigType" SG_ 2365402110 Jystck6GrpYAxsLvrBckNgtvPsStatus 4;
BA_ "SPN" SG_ 2365402110 Jystck6GrpYAxsLvrBckNgtvPsStatus 4592;
BA_ "SAEDocument" SG_ 2365402110 Jystck6GrpYAxsLvrBckNgtvPsStatus "J1939-71";
BA_ "SigType" SG_ 2365402110 Jystck6GripYAxisNeutralPosStatus 4;
BA_ "SPN" SG_ 2365402110 Jystck6GripYAxisNeutralPosStatus 4591;
BA_ "SAEDocument" SG_ 2365402110 Jystck6GripYAxisNeutralPosStatus "J1939-71";
BA_ "SPN" SG_ 2365402110 Joystick6GripXAxisPos 4590;
BA_ "SAEDocument" SG_ 2365402110 Joystick6GripXAxisPos "J1939-71";
BA_ "SigType" SG_ 2365402110 Jystck6GrpXAxsLvrRghtPstvPsSttus 4;
BA_ "SPN" SG_ 2365402110 Jystck6GrpXAxsLvrRghtPstvPsSttus 4589;
BA_ "SAEDocument" SG_ 2365402110 Jystck6GrpXAxsLvrRghtPstvPsSttus "J1939-71";
BA_ "SigType" SG_ 2365402110 Jystck6GrpXAxsLvrLftNgtvPsStatus 4;
BA_ "SPN" SG_ 2365402110 Jystck6GrpXAxsLvrLftNgtvPsStatus 4588;
BA_ "SAEDocument" SG_ 2365402110 Jystck6GrpXAxsLvrLftNgtvPsStatus "J1939-71";
BA_ "SigType" SG_ 2365402110 Jystck6GripXAxisNeutralPosStatus 4;
BA_ "SPN" SG_ 2365402110 Jystck6GripXAxisNeutralPosStatus 4587;
BA_ "SAEDocument" SG_ 2365402110 Jystck6GripXAxisNeutralPosStatus "J1939-71";
VAL_ 3221225472 TirePressThresholdDetection 7 "Not available" 6 "Error indicator" 5 "Not defined" 4 "Extreme under pressure  The tire pressure is at a level where the safety of the vehicle may be jeopardised" 3 "Under pressure  The tire pressure is lower than the pressure defined by the vehicle or tire manufacturer" 2 "No warning pressure  The tire pressure is within the thresholds defined by the vehicle or tire manufacturer" 1 "Over pressure  The tire pressure is higher than the pressure defined by the vehicle or tire manufacturer" 0 "Extreme over pressure  The tire pressure is at a level where the safety of the vehicle may be jeopardised" ;
VAL_ 3221225472 CTIWheelEndElectricalFault 3 "Not Supported" 2 "Error" 1 "Not Defined" 0 "Ok  No Fault" ;
VAL_ 3221225472 CTITireStatus 3 "Not Supported" 2 "Error" 1 "Tire leak detected" 0 "Ok no fault" ;
VAL_ 3221225472 CTIWheelSensorStatus 3 "Not Supported" 2 "Not Defined" 1 "On tire is polled" 0 "Off / isolated from CTI Pressure Controller" ;
VAL_ 3221225472 EngTurningGearEngaged 1 "Engaged" 0 "Not engaged" 3 "Not available" 2 "Error" ;
VAL_ 2148676694 A_A_ADC_wheelSPD 3 "Not available" 2 "Error" 1 "Pressure high fan may be engaged" 0 "Pressure normal" ;
VAL_ 2148676694 A_A_ADC_errWssGap 3 "Not available" 2 "Error" 1 "Pressure high fan may be engaged" 0 "Pressure normal" ;
VAL_ 2148676694 A_A_ADC_adcvalue 3 "Not available" 2 "Error" 1 "Pressure high fan may be engaged" 0 "Pressure normal" ;
VAL_ 2297441790 VrtclAcclrtnExRangeFigureOfMerit 3 "not available" 2 "error" 1 "verticalacceleration is degraded Data is suspect due to enviromental conditions" 0 "vertical acceleration is fully functional Data is within sensor specification" ;
VAL_ 2297441790 LngtdnlAcclrtnExRngFigureOfMerit 3 "not available" 2 "error" 1 "longitudinal acceleration is degraded Data is suspect due to enviromental conditions" 0 "longitudinal acceleration is fully functional Data is within sensor specification" ;
VAL_ 2297441790 LtrlAcclrtonExRangeFigureOfMerit 3 "not available" 2 "error" 1 "lateral acceleration is degraded Data is suspect due to enviromental conditions" 0 "lateral acceleration is fully functional Data is within sensor specification" ;
VAL_ 2364549630 RollAngleExRangeFigureOfMerit 3 "Not available" 2 "Error" 1 "Roll rate degraded Data is suspect due to environmental conditions" 0 "Roll rate fully functional Data is within sensor specification" ;
VAL_ 2364549630 RollAngleExRangeCompensation 3 "Not Available" 2 "Error" 1 "Off" 0 "On" ;
VAL_ 2364549630 PitchAngleExRangeFigureOfMerit 3 "Not available" 2 "Error" 1 "Pitch rate degraded Data is suspect due to environmental conditions" 0 "Pitch rate fully functional Data is within sensor specification" ;
VAL_ 2364549630 PitchAngleExRangeCompensation 3 "Not Available" 2 "Error" 1 "Off" 0 "On" ;
VAL_ 2499614462 OccpntClssficationSystem10Status 3 "not available" 2 "Error  Classification cannot be determined" 1 "occupied" 0 "empty" ;
VAL_ 2499614462 OccpntClssificationSystem9Status 3 "not available" 2 "Error  Classification cannot be determined" 1 "occupied" 0 "empty" ;
VAL_ 2499614462 OccpntClssificationSystem8Status 3 "not available" 2 "Error  Classification cannot be determined" 1 "occupied" 0 "empty" ;
VAL_ 2499614462 OccpntClssificationSystem7Status 3 "not available" 2 "Error  Classification cannot be determined" 1 "occupied" 0 "empty" ;
VAL_ 2499614462 OccpntClssificationSystem6Status 3 "not available" 2 "Error  Classification cannot be determined" 1 "occupied" 0 "empty" ;
VAL_ 2499614462 OccpntClssificationSystem5Status 3 "not available" 2 "Error  Classification cannot be determined" 1 "occupied" 0 "empty" ;
VAL_ 2499614462 OccpntClssificationSystem4Status 3 "not available" 2 "Error  Classification cannot be determined" 1 "occupied" 0 "empty" ;
VAL_ 2499614462 OccpntClssificationSystem3Status 3 "not available" 2 "Error  Classification cannot be determined" 1 "occupied" 0 "empty" ;
VAL_ 2499614462 PssngrOccpntClssfctnSystemStatus 3 "adult" 4 "reserved" 2 "small adult" 1 "child" 0 "empty" ;
VAL_ 2499614462 DrvrOccpntClssfctionSystemStatus 7 "not available" 6 "Error  Classification of occupant cannot be determined" 5 "reserved" 4 "large adult" 3 "adult" 2 "small adult" 1 "child" 0 "empty" ;
VAL_ 2560098046 CabNoiseCtrlTuningStatus 12 "Reserved" 11 "Reserved" 6 "Reserved" 5 "Reserved" 4 "Reserved" 3 "Reserved" 15 "Not Available/Not Tuning/Not Requested" 14 "Tuning Mode  Error" 10 "Automatic Tuning Mode  Saving Data" 9 "Automatic Tuning Mode  Command Complete" 8 "Automatic Tuning Mode" 7 "Manual Tuning Denied  Requires Security Verification" 13 "Reserved" 2 "Manual Tuning Mode  Saving Data" 1 "Manual Tuning Mode  Command Complete" 0 "Manual Tuning Mode" ;
VAL_ 2560098046 CabNoiseCtrlStatus 3 "Not Available/Not Requested" 2 "Error Indicator" 1 "Cab Noise Control System OFFLine" 0 "Cab Noise Control System ONLine" ;
VAL_ 2560163582 CabNoiseCtrlTuningState 7 "Dont Care NOT Commanded" 6 "Reserved" 5 "Exit Tuning Saving Parameters" 4 "Exit Tuning Not Saving Parameters" 3 "Remain In Tuning Save Current Parameters" 2 "Activate Automatic Tuning State Saveing Parameters Exit on Completion" 1 "Activate Automatic Tuning Wait for Save and Exit Commands" 0 "Activate Manual Tuning Wait for Save and Exit Commands" ;
VAL_ 2560163582 CabNoiseCtrlState 3 "Dont Care/Not Commanded" 2 "Reserved" 1 "Bring Cab Noise Control System On Line" 0 "Take Cab Noise Control System Off Line" ;
VAL_ 2297441534 DropRelayCtrl 3 "Take No Action" 2 "Reserved" 1 "On Enable Drop Relay Request" 0 "Off Disable Drop Relay Request" ;
VAL_ 2297441534 LiftRelayCtrl 3 "Take No Action" 2 "Reserved" 1 "On Enable Lift Relay Request" 0 "Off Disable Lift Relay Request" ;
VAL_ 2297441534 MaterialDropActiveStatus 3 "Not Available" 2 "Error" 1 "On" 0 "Off" ;
VAL_ 2297441534 MaterialLiftActiveStatus 3 "Not Available" 2 "Error" 1 "On" 0 "Off" ;
VAL_ 2297441534 GneratorCurrentBoostActiveStatus 3 "Not Available" 2 "Error" 1 "On" 0 "Off" ;
VAL_ 2297441534 MaterialDropSwitch 3 "Not Available" 2 "Error" 1 "Drop" 0 "Dont Drop" ;
VAL_ 2297441534 MaterialLiftSwitch 3 "Not Available" 2 "Error" 1 "Lift" 0 "Dont Lift" ;
VAL_ 2566722302 GeneratorDutyCycleExceededStatus 3 "Not Avaiable" 2 "Error" 1 "Duty Cycle Exceed" 0 "Duty Cycle Not Exceed" ;
VAL_ 2566722302 VoltageMonitorActiveStatus 3 "Not Available" 2 "Error" 1 "Monitor is On" 0 "Monitor is Off" ;
VAL_ 2566722302 GensetEnableActiveStatus 3 "Not Avaialble" 2 "Error" 1 "Enabled" 0 "Not Enabled" ;
VAL_ 2566722302 ReverseCurrentRangeSetting 31 "Not Available" 30 "Error" 15 "16" 14 "15" 13 "14" 12 "13" 11 "12" 10 "11" 9 "10" 8 "9" 7 "8" 6 "7" 5 "6" 4 "5" 3 "4" 2 "3" 1 "2" 0 "1" ;
VAL_ 2566722302 GensetSoftstartActiveStatus 3 "Not Available" 2 "Error" 1 "On" 0 "Off" ;
VAL_ 2566722302 Grapple_MagnetSelectionSwitch 3 "Not Available" 2 "Error" 1 "Magnet Selected" 0 "Grapple Selected" ;
VAL_ 2566722302 GnstSystmOtputVoltageRangeStatus 3 "Not Available" 2 "Error" 1 "In Range" 0 "Out of Range" ;
VAL_ 2566722302 GeneratorOverheatStatus 3 "Not Available" 2 "Error" 1 "Overheat" 0 "Not Overheat" ;
VAL_ 2560032510 LwVltgDscnnctDsiredOperatingMode 15 "No change" 5 "Manual Connect" 4 "Manual Disconnect" 0 "Automatic" ;
VAL_ 2566717950 LwVltgeDisconnectVoutOutputState 15 "Not available or not installed" 14 "Output fault" 4 "Connect pending alarm active" 3 "Disconnect pending alarm active" 2 "Disconnect alarm expired output off or disconnected" 1 "Output on or connected" 0 "Output off or disconnected" ;
VAL_ 2566717950 LowVoltageDisconnectOutput1State 15 "Not available or not installed" 14 "Output fault" 4 "Connect pending alarm active" 3 "Disconnect pending alarm active" 2 "Disconnect alarm expired output off or disconnected" 1 "Output on or connected" 0 "Output off or disconnected" ;
VAL_ 2566717950 LowVoltageDisconnectOutput2State 15 "Not available or not installed" 14 "Output fault" 4 "Connect pending alarm active" 3 "Disconnect pending alarm active" 2 "Disconnect alarm expired output off or disconnected" 1 "Output on or connected" 0 "Output off or disconnected" ;
VAL_ 2566717950 LowVoltageDisconnectOutput3State 15 "Not available or not installed" 14 "Output fault" 4 "Connect pending alarm active" 3 "Disconnect pending alarm active" 2 "Disconnect alarm expired output off or disconnected" 1 "Output on or connected" 0 "Output off or disconnected" ;
VAL_ 2566717950 LwVltgDscnnctCrrentOperatingMode 15 "Not available" 9 "Manual Connect via hardwired input" 8 "Manual Disconnect via hardwired input" 5 "Manual Connect via J1939 request" 4 "Manual Disconnect via J1939 request" 0 "Automatic" ;
VAL_ 2566717950 LwVltgDscnnectManualConnectState 3 "Not installed" 2 "Error" 1 "Input on" 0 "Input off" ;
VAL_ 2566717950 LwVltgDscnnctMnalDisconnectState 3 "Not installed" 2 "Error" 1 "Input on" 0 "Input off" ;
VAL_ 2358902526 Joystick3Lamp10Cmd 3 "Not available or not installed" 2 "Blinking" 1 "On" 0 "Off" ;
VAL_ 2358902526 Joystick3Lamp9Cmd 3 "Not available or not installed" 2 "Blinking" 1 "On" 0 "Off" ;
VAL_ 2358902526 Joystick3Lamp8Cmd 3 "Not available or not installed" 2 "Blinking" 1 "On" 0 "Off" ;
VAL_ 2358902526 Joystick3Lamp7Cmd 3 "Not available or not installed" 2 "Blinking" 1 "On" 0 "Off" ;
VAL_ 2358902526 Joystick3Lamp6Cmd 3 "Not available or not installed" 2 "Blinking" 1 "On" 0 "Off" ;
VAL_ 2358902526 Joystick3Lamp5Cmd 3 "Not available or not installed" 2 "Blinking" 1 "On" 0 "Off" ;
VAL_ 2358902526 Joystick3Lamp4Cmd 3 "Not available or not installed" 2 "Blinking" 1 "On" 0 "Off" ;
VAL_ 2358902526 Joystick3Lamp3Cmd 3 "Not available or not installed" 2 "Blinking" 1 "On" 0 "Off" ;
VAL_ 2358902526 Joystick3Lamp2Cmd 3 "Not available or not installed" 2 "Blinking" 1 "On" 0 "Off" ;
VAL_ 2358902526 Joystick3Lamp1Cmd 3 "Not available or not installed" 2 "Blinking" 1 "On" 0 "Off" ;
VAL_ 2358902526 Joystick2Lamp10Cmd 3 "Not available or not installed" 2 "Blinking" 1 "On" 0 "Off" ;
VAL_ 2358902526 Joystick2Lamp9Cmd 3 "Not available or not installed" 2 "Blinking" 1 "On" 0 "Off" ;
VAL_ 2358902526 Joystick2Lamp8Cmd 3 "Not available or not installed" 2 "Blinking" 1 "On" 0 "Off" ;
VAL_ 2358902526 Joystick2Lamp7Cmd 3 "Not available or not installed" 2 "Blinking" 1 "On" 0 "Off" ;
VAL_ 2358902526 Joystick2Lamp6Cmd 3 "Not available or not installed" 2 "Blinking" 1 "On" 0 "Off" ;
VAL_ 2358902526 Joystick2Lamp5Cmd 3 "Not available or not installed" 2 "Blinking" 1 "On" 0 "Off" ;
VAL_ 2358902526 Joystick2Lamp4Cmd 3 "Not available or not installed" 2 "Blinking" 1 "On" 0 "Off" ;
VAL_ 2358902526 Joystick2Lamp3Cmd 3 "Not available or not installed" 2 "Blinking" 1 "On" 0 "Off" ;
VAL_ 2358902526 Joystick2Lamp2Cmd 3 "Not available or not installed" 2 "Blinking" 1 "On" 0 "Off" ;
VAL_ 2358902526 Joystick2Lamp1Cmd 3 "Not available or not installed" 2 "Blinking" 1 "On" 0 "Off" ;
VAL_ 2358902526 Joystick1Lamp10Cmd 3 "Not available or not installed" 2 "Blinking" 1 "On" 0 "Off" ;
VAL_ 2358902526 Joystick1Lamp9Cmd 3 "Not available or not installed" 2 "Blinking" 1 "On" 0 "Off" ;
VAL_ 2358902526 Joystick1Lamp8Cmd 3 "Not available or not installed" 2 "Blinking" 1 "On" 0 "Off" ;
VAL_ 2358902526 Joystick1Lamp7Cmd 3 "Not available or not installed" 2 "Blinking" 1 "On" 0 "Off" ;
VAL_ 2358902526 Joystick1Lamp6Cmd 3 "Not available or not installed" 2 "Blinking" 1 "On" 0 "Off" ;
VAL_ 2358902526 Joystick1Lamp5Cmd 3 "Not available or not installed" 2 "Blinking" 1 "On" 0 "Off" ;
VAL_ 2358902526 Joystick1Lamp4Cmd 3 "Not available or not installed" 2 "Blinking" 1 "On" 0 "Off" ;
VAL_ 2358902526 Joystick1Lamp3Cmd 3 "Not available or not installed" 2 "Blinking" 1 "On" 0 "Off" ;
VAL_ 2358902526 Joystick1Lamp2Cmd 3 "Not available or not installed" 2 "Blinking" 1 "On" 0 "Off" ;
VAL_ 2358902526 Joystick1Lamp1Cmd 3 "Not available or not installed" 2 "Blinking" 1 "On" 0 "Off" ;
VAL_ 2566711550 IntkVlvActtnSystmOlPrss2SlndCtrl 3 "not available" 2 "reserved for SAE assignment" 1 "on" 0 "off" ;
VAL_ 2566711550 IntkVlvActtnSystmOlPrss1SlndCtrl 3 "not available" 2 "reserved for SAE assignment" 1 "on" 0 "off" ;
VAL_ 2566713854 EngTrbWstgtActtr2OperationStatus 14 "Error" 6 "1101ReservedForFutureAssignment" 5 "UnCtrlledShutdownActive" 4 "CtrlledShutdownActive" 3 "DerateActive" 2 "AlarmHighSeverity" 1 "Alarm" 0 "Normal" ;
VAL_ 2566713854 EngTrbWstgtActtr1OperationStatus 14 "Error" 6 "1101ReservedForFutureAssignment" 5 "UnCtrlledShutdownActive" 4 "CtrlledShutdownActive" 3 "DerateActive" 2 "AlarmHighSeverity" 1 "Alarm" 0 "Normal" ;
VAL_ 2566713854 EngTrbWstgateActuator2TempStatus 7 "Not available" 6 "Error" 5 "Not Defined" 4 "Low Most severe" 3 "Low Least severe" 2 "In Range" 1 "High Least severe" 0 "High most severe" ;
VAL_ 2566714366 EngTrbCmprssrBypssActtr2OprtnStt 14 "Error" 6 "1101ReservedForFutureAssignment" 5 "UnCtrlledShutdownActive" 4 "CtrlledShutdownActive" 3 "DerateActive" 2 "AlarmHighSeverity" 1 "Alarm" 0 "Normal" ;
VAL_ 2566714366 EngTrbCmprssrBypssActtr1OprtnStt 14 "Error" 6 "1101ReservedForFutureAssignment" 5 "UnCtrlledShutdownActive" 4 "CtrlledShutdownActive" 3 "DerateActive" 2 "AlarmHighSeverity" 1 "Alarm" 0 "Normal" ;
VAL_ 2566714366 EngTrbCmprssrBypssActtr2TmpSttus 7 "Not available" 6 "Error" 5 "Not Defined" 4 "Low Most severe" 3 "Low Least severe" 2 "In Range" 1 "High Least severe" 0 "High most severe" ;
VAL_ 2566714110 EngFuelValve2OperationStatus 14 "Error" 6 "1101ReservedForFutureAssignment" 5 "UnCtrlledShutdownActive" 4 "CtrlledShutdownActive" 3 "DerateActive" 2 "AlarmHighSeverity" 1 "Alarm" 0 "Normal" ;
VAL_ 2566714110 EngFuelValve1OperationStatus 14 "Error" 6 "1101ReservedForFutureAssignment" 5 "UnCtrlledShutdownActive" 4 "CtrlledShutdownActive" 3 "DerateActive" 2 "AlarmHighSeverity" 1 "Alarm" 0 "Normal" ;
VAL_ 2566714110 EngThrottleValve2OperationStatus 14 "Error" 6 "1101ReservedForFutureAssignment" 5 "UnCtrlledShutdownActive" 4 "CtrlledShutdownActive" 3 "DerateActive" 2 "AlarmHighSeverity" 1 "Alarm" 0 "Normal" ;
VAL_ 2566714110 EngThrottleValve1OperationStatus 15 "Not available" 14 "Error" 6 "1101 Reserved for future assignment" 5 "Uncontrolled Shutdown Active actuator current is off so it is limp" 4 "Controlled Shutdown Active driving to the default position  usually this means closed" 3 "Derate Active torque output reduced due to environmental conditions" 2 "Alarm High Severity functional but transient performance may be reduced" 1 "Alarm fully operational but needs service" 0 "Normal" ;
VAL_ 2566714110 EngFuelValve2TempStatus 7 "Not available" 6 "Error" 5 "Not Defined" 4 "Low Most severe" 3 "Low Least severe" 2 "In Range" 1 "High Least severe" 0 "High most severe" ;
VAL_ 2566714110 EngFuelValve1TempStatus 7 "Not available" 6 "Error" 5 "Not Defined" 4 "Low Most severe" 3 "Low Least severe" 2 "In Range" 1 "High Least severe" 0 "High Most severe" ;
VAL_ 2566714110 EngThrottleValve2TempStatus 7 "Not available" 6 "Error" 5 "Not Defined" 4 "Low Most severe" 3 "Low Least severe" 2 "In Range" 1 "High Least severe" 0 "High Most severe" ;
VAL_ 2566714110 EngThrottleValve1TempStatus 7 "Not available" 6 "Error" 5 "Not Defined" 4 "Low Most severe" 3 "Low Least severe" 2 "In Range" 1 "High Least severe" 0 "High most severe" ;
VAL_ 2365400574 Jystick9GripXAxisDetentPosStatus 3 "Not Available" 2 "Error Indicator" 1 "In the Detent Position" 0 "Not in the Detent Position" ;
VAL_ 2365400574 Jystick9GripYAxisDetentPosStatus 3 "Not Available" 2 "Error Indicator" 1 "In the Detent Position" 0 "Not in the Detent Position" ;
VAL_ 2365400574 Jystick9ThetaAxisDetentPosStatus 3 "Not Available" 2 "Error Indicator" 1 "In the Detent Position" 0 "Not in the Detent Position" ;
VAL_ 2365400574 Jystck9ThtAxsClckwsPstvPosStatus 3 "Not Available" 2 "Error Indicator" 1 "On positive side of Neutral" 0 "Not on Positive side of Neutral" ;
VAL_ 2365400574 Jystck9ThtAxsCntrClckwsNgtvPsStt 3 "Not Available" 2 "Error Indicator" 1 "On negative side of Neutral" 0 "Not on negative side of Neutral" ;
VAL_ 2365400574 Jystck9ThetaAxisNeutralPosStatus 3 "Not Available" 2 "Error Indicator" 1 "In Neutral Position" 0 "Not in Neutral Position" ;
VAL_ 2365400574 Jystck9GrpYAxsLvrFrwrdPstvPsStts 3 "Not Available" 2 "Error Indicator" 1 "On positive side of Neutral" 0 "Not on Positive side of Neutral" ;
VAL_ 2365400574 Jystck9GrpYAxsLvrBckNgtvPsStatus 3 "Not Available" 2 "Error Indicator" 1 "On negative side of Neutral" 0 "Not on negative side of Neutral" ;
VAL_ 2365400574 Jystck9GripYAxisNeutralPosStatus 3 "Not Available" 2 "Error Indicator" 1 "In Neutral Position" 0 "Not in Neutral Position" ;
VAL_ 2365400574 Jystck9GrpXAxsLvrRghtPstvPsSttus 3 "Not Available" 2 "Error Indicator" 1 "On positive side of Neutral" 0 "Not on Positive side of Neutral" ;
VAL_ 2365400574 Jystck9GrpXAxsLvrLftNgtvPsStatus 3 "Not Available" 2 "Error Indicator" 1 "On negative side of Neutral" 0 "Not on negative side of Neutral" ;
VAL_ 2365400574 Jystck9GripXAxisNeutralPosStatus 3 "Not Available" 2 "Error Indicator" 1 "In Neutral Position" 0 "Not in Neutral Position" ;
VAL_ 2365401086 Jystick8GripXAxisDetentPosStatus 3 "Not Available" 2 "Error Indicator" 1 "In the Detent Position" 0 "Not in the Detent Position" ;
VAL_ 2365401086 Jystick8GripYAxisDetentPosStatus 3 "Not Available" 2 "Error Indicator" 1 "In the Detent Position" 0 "Not in the Detent Position" ;
VAL_ 2365401086 Jystick8ThetaAxisDetentPosStatus 3 "Not Available" 2 "Error Indicator" 1 "In the Detent Position" 0 "Not in the Detent Position" ;
VAL_ 2365401086 Jystck8ThtAxsClckwsPstvPosStatus 3 "Not Available" 2 "Error Indicator" 1 "On positive side of Neutral" 0 "Not on Positive side of Neutral" ;
VAL_ 2365401086 Jystck8ThtAxsCntrClckwsNgtvPsStt 3 "Not Available" 2 "Error Indicator" 1 "On negative side of Neutral" 0 "Not on negative side of Neutral" ;
VAL_ 2365401086 Jystck8ThetaAxisNeutralPosStatus 3 "Not Available" 2 "Error Indicator" 1 "In Neutral Position" 0 "Not in Neutral Position" ;
VAL_ 2365401086 Jystck8GrpYAxsLvrFrwrdPstvPsStts 3 "Not Available" 2 "Error Indicator" 1 "On positive side of Neutral" 0 "Not on Positive side of Neutral" ;
VAL_ 2365401086 Jystck8GrpYAxsLvrBckNgtvPsStatus 3 "Not Available" 2 "Error Indicator" 1 "On negative side of Neutral" 0 "Not on negative side of Neutral" ;
VAL_ 2365401086 Jystck8GripYAxisNeutralPosStatus 3 "Not Available" 2 "Error Indicator" 1 "In Neutral Position" 0 "Not in Neutral Position" ;
VAL_ 2365401086 Jystck8GrpXAxsLvrRghtPstvPsSttus 3 "Not Available" 2 "Error Indicator" 1 "On positive side of Neutral" 0 "Not on Positive side of Neutral" ;
VAL_ 2365401086 Jystck8GrpXAxsLvrLftNgtvPsStatus 3 "Not Available" 2 "Error Indicator" 1 "On negative side of Neutral" 0 "Not on negative side of Neutral" ;
VAL_ 2365401086 Jystck8GripXAxisNeutralPosStatus 3 "Not Available" 2 "Error Indicator" 1 "In Neutral Position" 0 "Not in Neutral Position" ;
VAL_ 2365401598 Jystick7GripXAxisDetentPosStatus 3 "Not Available" 2 "Error Indicator" 1 "In the Detent Position" 0 "Not in the Detent Position" ;
VAL_ 2365401598 Jystick7GripYAxisDetentPosStatus 3 "Not Available" 2 "Error Indicator" 1 "In the Detent Position" 0 "Not in the Detent Position" ;
VAL_ 2365401598 Jystick7ThetaAxisDetentPosStatus 3 "Not Available" 2 "Error Indicator" 1 "In the Detent Position" 0 "Not in the Detent Position" ;
VAL_ 2365401598 Jystck7ThtAxsClckwsPstvPosStatus 3 "Not Available" 2 "Error Indicator" 1 "On positive side of Neutral" 0 "Not on Positive side of Neutral" ;
VAL_ 2365401598 Jystck7ThtAxsCntrClckwsNgtvPsStt 3 "Not Available" 2 "Error Indicator" 1 "On negative side of Neutral" 0 "Not on negative side of Neutral" ;
VAL_ 2365401598 Jystck7ThetaAxisNeutralPosStatus 3 "Not Available" 2 "Error Indicator" 1 "In Neutral Position" 0 "Not in Neutral Position" ;
VAL_ 2365401598 Jystck7GrpYAxsLvrFrwrdPstvPsStts 3 "Not Available" 2 "Error Indicator" 1 "On positive side of Neutral" 0 "Not on Positive side of Neutral" ;
VAL_ 2365401598 Jystck7GrpYAxsLvrBckNgtvPsStatus 3 "Not Available" 2 "Error Indicator" 1 "On negative side of Neutral" 0 "Not on negative side of Neutral" ;
VAL_ 2365401598 Jystck7GripYAxisNeutralPosStatus 3 "Not Available" 2 "Error Indicator" 1 "In Neutral Position" 0 "Not in Neutral Position" ;
VAL_ 2365401598 Jystck7GrpXAxsLvrRghtPstvPsSttus 3 "Not Available" 2 "Error Indicator" 1 "On positive side of Neutral" 0 "Not on Positive side of Neutral" ;
VAL_ 2365401598 Jystck7GrpXAxsLvrLftNgtvPsStatus 3 "Not Available" 2 "Error Indicator" 1 "On negative side of Neutral" 0 "Not on negative side of Neutral" ;
VAL_ 2365401598 Jystck7GripXAxisNeutralPosStatus 3 "Not Available" 2 "Error Indicator" 1 "In Neutral Position" 0 "Not in Neutral Position" ;
VAL_ 2365402110 Jystick6GripXAxisDetentPosStatus 3 "Not Available" 2 "Error Indicator" 1 "In the Detent Position" 0 "Not in the Detent Position" ;
VAL_ 2365402110 Jystick6GripYAxisDetentPosStatus 3 "Not Available" 2 "Error Indicator" 1 "In the Detent Position" 0 "Not in the Detent Position" ;
VAL_ 2365402110 Jystick6ThetaAxisDetentPosStatus 3 "Not Available" 2 "Error Indicator" 1 "In the Detent Position" 0 "Not in the Detent Position" ;
VAL_ 2365402110 Jystck6ThtAxsClckwsPstvPosStatus 3 "Not Available" 2 "Error Indicator" 1 "On positive side of Neutral" 0 "Not on Positive side of Neutral" ;
VAL_ 2365402110 Jystck6ThtAxsCntrClckwsNgtvPsStt 3 "Not Available" 2 "Error Indicator" 1 "On negative side of Neutral" 0 "Not on negative side of Neutral" ;
VAL_ 2365402110 Jystck6ThetaAxisNeutralPosStatus 3 "Not Available" 2 "Error Indicator" 1 "In Neutral Position" 0 "Not in Neutral Position" ;
VAL_ 2365402110 Jystck6GrpYAxsLvrFrwrdPstvPsStts 3 "Not Available" 2 "Error Indicator" 1 "On positive side of Neutral" 0 "Not on Positive side of Neutral" ;
VAL_ 2365402110 Jystck6GrpYAxsLvrBckNgtvPsStatus 3 "Not Available" 2 "Error Indicator" 1 "On negative side of Neutral" 0 "Not on negative side of Neutral" ;
VAL_ 2365402110 Jystck6GripYAxisNeutralPosStatus 3 "Not Available" 2 "Error Indicator" 1 "In Neutral Position" 0 "Not in Neutral Position" ;
VAL_ 2365402110 Jystck6GrpXAxsLvrRghtPstvPsSttus 3 "Not Available" 2 "Error Indicator" 1 "On positive side of Neutral" 0 "Not on Positive side of Neutral" ;
VAL_ 2365402110 Jystck6GrpXAxsLvrLftNgtvPsStatus 3 "Not Available" 2 "Error Indicator" 1 "On negative side of Neutral" 0 "Not on negative side of Neutral" ;
VAL_ 2365402110 Jystck6GripXAxisNeutralPosStatus 3 "Not Available" 2 "Error Indicator" 1 "In Neutral Position" 0 "Not in Neutral Position" ;
